VERSION ""

NS_ :

BS_:

BU_: Airbag Allrad EPS Teves_MK60_ESP LWS LWR Teves_MK70_MABS Waehlhebel EPB TRW_ESP ACC_Radar AFS Magne_Ride RKA_Plus Selespeed Waehlhebel_Sele PDC_PLA Lenkhilfe_APA VAQ Daempfer Hybrid_BMS Hybrid_PWR Hybrid_DQ200 EKlimakomp SWA HCA ACC_Lidar Lenkhilfe_ZF_3G FLA AG6 DQ Hybrid_MSG Diesel Otto Gateway_PQ35_A Gateway_PQ46_A Vector_XXX Fzg_CAN

BO_ 1472 mEPB_1: 8 EPB
 SG_ EP1_Spannkraft : 8|5@1+ (1,0) [0|30] "kN"  Gateway_PQ46_A,Diesel,Otto,ACC_Radar,Gateway_PQ35_A,Daempfer
 SG_ EP1_Sta_EPB : 6|1@1+ (1,0) [0|1] ""  Gateway_PQ46_A,Diesel,Otto,ACC_Radar,Gateway_PQ35_A,Daempfer,PDC_PLA
 SG_ EP1_Fehler_Sta : 4|2@1+ (1,0) [0|3] ""  Gateway_PQ46_A,Diesel,Otto,ACC_Radar,Gateway_PQ35_A,Daempfer,PDC_PLA
 SG_ EP1_Zaehler : 0|4@1+ (1,0) [0|15] ""  Gateway_PQ46_A,Diesel,Otto,ACC_Radar,Gateway_PQ35_A,Daempfer
 SG_ EP1_Schalterinfo : 13|2@1+ (1,0) [0|3] ""  Gateway_PQ46_A,Diesel,Otto,ACC_Radar,Gateway_PQ35_A,Daempfer
 SG_ EP1_Sta_Schalter : 7|1@1+ (1,0) [0|1] ""  Gateway_PQ46_A,Diesel,Otto,ACC_Radar,Gateway_PQ35_A,Daempfer
 SG_ EP1_Sta_NWS : 15|1@1+ (1,0) [0|1] ""  Gateway_PQ46_A,Diesel,Otto,ACC_Radar,Gateway_PQ35_A,Daempfer
 SG_ EP1_Fkt_Lampe : 48|1@1+ (1,0) [0|1] ""  Gateway_PQ46_A,Diesel,Otto,ACC_Radar,Gateway_PQ35_A,Daempfer
 SG_ EP1_Verzoegerung : 24|8@1+ (0.048,-7.968) [-7.968|4.224] "m/s²"  Gateway_PQ46_A,Diesel,Otto,ACC_Radar,Gateway_PQ35_A,Daempfer
 SG_ EP1_Neig_winkel : 16|8@1+ (1,-128) [-128|127] "%g"  Gateway_PQ46_A,Diesel,Otto,ACC_Radar,Gateway_PQ35_A,Daempfer
 SG_ EP1_Fehler_gelb : 51|1@1+ (1,0) [0|1] ""  Gateway_PQ46_A,Diesel,Otto,ACC_Radar,Gateway_PQ35_A,Daempfer
 SG_ EP1_Warnton : 49|1@1+ (1,0) [0|1] ""  Gateway_PQ46_A,Diesel,Otto,ACC_Radar,Gateway_PQ35_A,Daempfer
 SG_ EP1_Fehler_BKL : 50|1@1+ (1,0) [0|1] ""  Gateway_PQ46_A,Gateway_PQ35_A,Otto,Diesel,Daempfer,ACC_Radar
 SG_ EP1_Fehlereintr : 32|1@1+ (1,0) [0|1] ""  Gateway_PQ46_A,Diesel,Otto,ACC_Radar,Gateway_PQ35_A,Daempfer
 SG_ EP1__Text : 52|4@1+ (1,0) [0|15] ""  Gateway_PQ46_A,Diesel,Otto,ACC_Radar,Gateway_PQ35_A,Daempfer
 SG_ EP1_Freigabe_Ver : 33|1@1+ (1,0) [0|1] ""  Gateway_PQ46_A,Diesel,Otto,ACC_Radar,Gateway_PQ35_A,Daempfer
 SG_ EP1_Checksum : 56|8@1+ (1,0) [0|255] ""  Gateway_PQ46_A,Diesel,Otto,ACC_Radar,Gateway_PQ35_A,Daempfer
 SG_ EP1_Auto_Schl_Oe : 43|1@1+ (1,0) [0|1] ""  Gateway_PQ46_A,Gateway_PQ35_A
 SG_ EP1_SleepInd : 36|1@1+ (1,0) [0|1] ""  Gateway_PQ46_A,Diesel,Otto,ACC_Radar,Gateway_PQ35_A,Daempfer
 SG_ EP1_Bremslicht : 39|1@1+ (1,0) [0|1] ""  Gateway_PQ46_A,Diesel,Otto,ACC_Radar,Gateway_PQ35_A,Daempfer
 SG_ EP1_Status_Kl_15 : 37|1@1+ (1,0) [0|1] ""  Gateway_PQ46_A,Diesel,Otto,ACC_Radar,Gateway_PQ35_A,Daempfer
 SG_ EP1_Warnton2 : 41|1@1+ (1,0) [0|1] ""  Gateway_PQ46_A,Diesel,Otto,ACC_Radar,Gateway_PQ35_A,Daempfer
 SG_ EP1_Lampe_AutoP : 38|1@1+ (1,0) [0|1] ""  Gateway_PQ46_A,Diesel,Otto,ACC_Radar,Gateway_PQ35_A,Daempfer
 SG_ EP1_QualNeigWi : 44|1@1+ (1,0) [0|1] ""  Gateway_PQ46_A,Gateway_PQ35_A
 SG_ EP1_AnfShLock : 42|1@1+ (1,0) [0|1] ""  Gateway_PQ46_A,Diesel,Otto,ACC_Radar,Gateway_PQ35_A,Daempfer
 SG_ EP1_HydrHalten : 47|1@1+ (1,0) [0|1] ""  Gateway_PQ46_A,Diesel,Otto,ACC_Radar,Gateway_PQ35_A,Daempfer
 SG_ EP1_Warnton1 : 40|1@1+ (1,0) [0|1] ""  Gateway_PQ46_A,Diesel,Otto,ACC_Radar,Gateway_PQ35_A,Daempfer
 SG_ EP1_KuppModBer : 45|2@1+ (1,0) [0|3] ""  Gateway_PQ46_A,Diesel,Gateway_PQ35_A,Otto
 SG_ EP1_AutoHold_zul : 34|1@1+ (1,0) [0|1] ""  ACC_Radar,Daempfer,Gateway_PQ35_A,Diesel,Otto,Gateway_PQ46_A
 SG_ EP1_AutoHold_aktiv : 35|1@1+ (1,0) [0|1] ""  ACC_Radar,Daempfer,Gateway_PQ35_A,Diesel,Gateway_PQ46_A,Otto

BO_ 537 mTP_Er_EPB: 7 EPB
 SG_ EPB_TP_Er : 0|56@1+ (1,0) [0|7.2057594038E+016] ""  Gateway_PQ46_A,Gateway_PQ35_A

BO_ 1386 mACC_GRA_Anzeige: 8 ACC_Radar
 SG_ ACA_ID_StaACC : 11|5@1+ (1,0) [0|31] ""  Gateway_PQ46_A,Gateway_PQ35_A
 SG_ ACA_Fahrerhinw : 16|1@1+ (1,0) [0|1] ""  Gateway_PQ46_A,Gateway_PQ35_A
 SG_ ACA_V_Wunsch : 24|8@1+ (1,0) [0|254] "km/h"  Gateway_PQ46_A,Gateway_PQ35_A,DQ,AG6
 SG_ ACA_PrioDisp : 35|2@1+ (1,0) [0|3] ""  Gateway_PQ46_A,Gateway_PQ35_A
 SG_ ACA_StaACC : 8|3@1+ (1,0) [0|7] ""  Gateway_PQ46_A,Gateway_PQ35_A
 SG_ ACA_AnzDisplay : 17|1@1+ (1,0) [0|1] ""  Gateway_PQ46_A,Gateway_PQ35_A
 SG_ ACA_Zeitluecke : 18|4@1+ (1,0) [0|15] ""  Gateway_PQ46_A,Gateway_PQ35_A
 SG_ ACA_gemZeitl : 40|4@1+ (1,0) [0|15] ""  Gateway_PQ46_A,Gateway_PQ35_A
 SG_ ACA_kmh_mph : 32|1@1+ (1,0) [0|1] ""  Gateway_PQ46_A,Gateway_PQ35_A
 SG_ ACA_Akustik1 : 33|1@1+ (1,0) [0|1] ""  Gateway_PQ46_A,Gateway_PQ35_A
 SG_ ACA_Akustik2 : 34|1@1+ (1,0) [0|1] ""  Gateway_PQ46_A,Gateway_PQ35_A
 SG_ ACA_Checksum : 0|8@1+ (1,0) [0|255] ""  Gateway_PQ46_A,Gateway_PQ35_A
 SG_ ACA_Codierung : 56|1@1+ (1,0) [0|1] ""  Gateway_PQ46_A,Gateway_PQ35_A
 SG_ ACA_Tachokranz : 57|1@1+ (1,0) [0|1] ""  Gateway_PQ46_A,Gateway_PQ35_A
 SG_ ACA_ACC_Verz : 44|1@1+ (1,0) [0|1] ""  Gateway_PQ46_A,Gateway_PQ35_A
 SG_ ACA_res_22 : 22|2@1+ (1,0) [0|3] ""  Gateway_PQ46_A,Gateway_PQ35_A
 SG_ ACA_Zaehler : 60|4@1+ (1,0) [0|15] ""  Gateway_PQ46_A,Gateway_PQ35_A
 SG_ ACA_res_37 : 37|2@1+ (1,0) [0|3] ""  Gateway_PQ46_A,Gateway_PQ35_A
 SG_ ACA_res_45 : 45|3@1+ (1,0) [0|7] ""  Gateway_PQ46_A,Gateway_PQ35_A
 SG_ ACA_ID_StaGRA : 51|5@1+ (1,0) [0|31] ""  Gateway_PQ46_A,Gateway_PQ35_A
 SG_ ACA_res_59 : 59|1@1+ (1,0) [0|1] ""  Gateway_PQ46_A,Gateway_PQ35_A
 SG_ ACA_res_39 : 39|1@1+ (1,0) [0|1] ""  Gateway_PQ46_A,Gateway_PQ35_A
 SG_ ACA_Aend_Zeitluecke : 58|1@1+ (1,0) [0|1] ""  Gateway_PQ46_A,Gateway_PQ35_A
 SG_ ACA_StaGRA : 48|3@1+ (1,0) [0|7] ""  Gateway_PQ46_A,Gateway_PQ35_A

BO_ 523 mTP_Er_ADR: 7 ACC_Radar
 SG_ ADR_TP_Er : 0|56@1+ (1,0) [0|7.2057594038E+016] ""  Gateway_PQ46_A

BO_ 872 mACC_System: 8 ACC_Radar
 SG_ ACS_Schubabsch : 15|1@1+ (1,0) [0|1] ""  Diesel,Otto,AG6,DQ
 SG_ ACS_ADR_Schub : 14|1@1+ (1,0) [0|1] ""  Diesel,Otto,DQ,AG6
 SG_ ACS_Checksum : 0|8@1+ (1,0) [0|255] ""  Diesel,Otto,Daempfer
 SG_ ACS_Sta_ADR : 12|2@1+ (1,0) [0|3] ""  Diesel,Otto,AG6,DQ
 SG_ ACS_StSt_Info : 16|2@1+ (1,0) [0|3] ""  Diesel,Otto
 SG_ ACS_Zaehler : 8|4@1+ (1,0) [0|15] ""  Diesel,Otto,Daempfer
 SG_ ACS_MomEingriff : 18|1@1+ (1,0) [0|1] ""  Diesel,Otto,AG6,DQ
 SG_ ACS_FreigSollB : 23|1@1+ (1,0) [0|1] ""  Diesel,Otto,Daempfer,AG6,DQ
 SG_ ACS_Sollbeschl : 24|11@1+ (0.005,-7.22) [-7.22|3.005] "m/s²"  Diesel,Otto,Daempfer,DQ,AG6
 SG_ ACS_res_21 : 21|2@1+ (1,0) [0|3] ""  Otto,Diesel
 SG_ ACS_res_37 : 37|1@1+ (1,0) [0|1] ""  Otto,Diesel
 SG_ ACS_res_35 : 35|1@1+ (1,0) [0|1] ""  Otto,Diesel
 SG_ ACS_Typ_ACC : 19|2@1+ (1,0) [0|3] ""  Diesel,Otto,DQ,AG6
 SG_ ACS_Anhaltewunsch : 38|1@1+ (1,0) [0|1] ""  Diesel,Otto
 SG_ ACS_zul_Regelabw : 40|8@1+ (0.005,0) [0|1.265] "m/s²"  Diesel,Otto
 SG_ ACS_res_36 : 36|1@1+ (1,0) [0|1] ""  Otto,Diesel
 SG_ ACS_max_AendGrad : 48|8@1+ (0.02,0) [0.02|5.06] "m/s²"  Diesel,Otto
 SG_ ACS_res_56 : 56|1@1+ (1,0) [0|1] ""  Otto,Diesel
 SG_ ACS_res_57 : 57|1@1+ (1,0) [0|1] ""  Otto,Diesel
 SG_ ACS_Fehler : 39|1@1+ (1,0) [0|1] ""  Gateway_PQ46_A,Diesel,Otto,Gateway_PQ35_A
 SG_ ACS_res_58 : 58|1@1+ (1,0) [0|1] ""  Otto,Diesel
 SG_ ACS_res_59 : 59|1@1+ (1,0) [0|1] ""  Otto,Diesel
 SG_ ACS_res_63 : 63|1@1+ (1,0) [0|1] ""  Otto,Diesel
 SG_ ACS_res_60 : 60|1@1+ (1,0) [0|1] ""  Otto,Diesel
 SG_ ACS_res_62 : 62|1@1+ (1,0) [0|1] ""  Otto,Diesel
 SG_ ACS_res_61 : 61|1@1+ (1,0) [0|1] ""  Otto,Diesel

BO_ 870 mAWV: 5 ACC_Radar
 SG_ AWV_2_Status : 24|1@1+ (1,0) [0|1] ""  Gateway_PQ46_A,TRW_ESP,HCA,Gateway_PQ35_A
 SG_ AWV_2_SU_Warnzeit : 26|2@1+ (1,0) [0|3] ""  Gateway_PQ46_A,TRW_ESP,HCA,Gateway_PQ35_A
 SG_ AWV_Checksumme : 0|8@1+ (1,0) [0|255] ""  Gateway_PQ46_A,TRW_ESP,HCA,Gateway_PQ35_A
 SG_ AWV_Zaehler : 8|4@1+ (1,0) [0|15] ""  Gateway_PQ46_A,TRW_ESP,HCA,Gateway_PQ35_A
 SG_ AWV_2_Fehler : 25|1@1+ (1,0) [0|1] ""  Gateway_PQ46_A,TRW_ESP,HCA,Gateway_PQ35_A
 SG_ AWV_1_Prefill : 17|1@1+ (1,0) [0|1] ""  Gateway_PQ46_A,TRW_ESP,HCA,Gateway_PQ35_A
 SG_ AWV_Text : 12|4@1+ (1,0) [0|15] ""  Gateway_PQ46_A,TRW_ESP,HCA,Gateway_PQ35_A
 SG_ AWV_res_20 : 20|4@1+ (1,0) [0|15] ""  Gateway_PQ46_A,Gateway_PQ35_A,HCA,TRW_ESP
 SG_ AWV_1_Freigabe : 16|1@1+ (1,0) [0|1] ""  Gateway_PQ46_A,TRW_ESP,HCA,Gateway_PQ35_A
 SG_ AWV_2_SU_Bremsruck : 28|1@1+ (1,0) [0|1] ""  Gateway_PQ46_A,TRW_ESP,HCA,Gateway_PQ35_A
 SG_ AWV_1_Parameter : 18|2@1+ (1,0) [0|3] ""  Gateway_PQ46_A,TRW_ESP,HCA,Gateway_PQ35_A
 SG_ AWV_2_Umfeldwarn : 31|1@1+ (1,0) [0|1] ""  Gateway_PQ46_A,TRW_ESP,HCA,Gateway_PQ35_A
 SG_ AWV_2_Freigabe : 32|1@1+ (1,0) [0|1] ""  Gateway_PQ46_A,TRW_ESP,HCA,Gateway_PQ35_A
 SG_ AWV_2_Gurtstraffer : 39|1@1+ (1,0) [0|1] ""  Gateway_PQ46_A,TRW_ESP,HCA,Gateway_PQ35_A
 SG_ AWV_2_SU_Gong : 29|1@1+ (1,0) [0|1] ""  Gateway_PQ46_A,TRW_ESP,HCA,Gateway_PQ35_A
 SG_ AWV_Infoton : 38|1@1+ (1,0) [0|1] ""  Gateway_PQ46_A,TRW_ESP,HCA,Gateway_PQ35_A
 SG_ AWV_2_Warnsymbol : 37|1@1+ (1,0) [0|1] ""  Gateway_PQ46_A,TRW_ESP,HCA,Gateway_PQ35_A
 SG_ AWV_2_Warnton : 36|1@1+ (1,0) [0|1] ""  Gateway_PQ46_A,TRW_ESP,HCA,Gateway_PQ35_A
 SG_ AWV_2_Ruckprofil : 33|3@1+ (1,0) [0|7] ""  Gateway_PQ46_A,TRW_ESP,HCA,Gateway_PQ35_A
 SG_ AWV_2_SU_Lampe : 30|1@1+ (1,0) [0|1] ""  Gateway_PQ46_A,TRW_ESP,HCA,Gateway_PQ35_A

BO_ 1652 BAP_ACC: 8 ACC_Radar
 SG_ BAP_Data_ACC : 0|16@1+ (1,0) [0|65535] ""  Gateway_PQ46_A,Gateway_PQ35_A
 SG_ BAP_var_ACC : 16|48@1+ (1,0) [0|2.8147497671E+014] ""  Gateway_PQ46_A,Gateway_PQ35_A

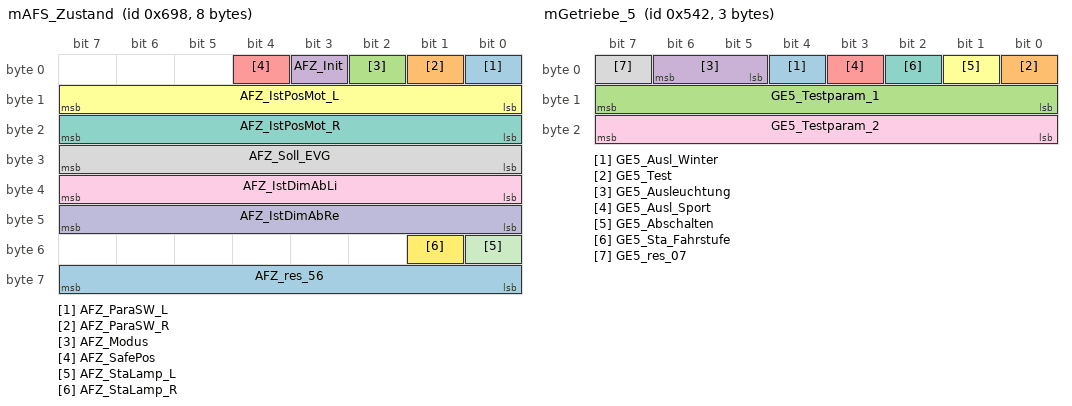
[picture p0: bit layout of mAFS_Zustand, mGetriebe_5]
BO_ 1688 mAFS_Zustand: 8 AFS
 SG_ AFZ_ParaSW_L : 0|1@1+ (1,0) [0|1] "" Vector__XXX
 SG_ AFZ_ParaSW_R : 1|1@1+ (1,0) [0|1] "" Vector__XXX
 SG_ AFZ_Modus : 2|1@1+ (1,0) [0|1] "" Vector__XXX
 SG_ AFZ_Init : 3|1@1+ (1,0) [0|1] "" Vector__XXX
 SG_ AFZ_SafePos : 4|1@1+ (1,0) [0|1] "" Vector__XXX
 SG_ AFZ_IstPosMot_L : 8|8@1+ (0.4,0) [0|100] "%" Vector__XXX
 SG_ AFZ_IstPosMot_R : 16|8@1+ (0.4,0) [0|100] "%" Vector__XXX
 SG_ AFZ_Soll_EVG : 24|8@1+ (0.4,0) [0|100] "%" Vector__XXX
 SG_ AFZ_IstDimAbLi : 32|8@1+ (0.4,0) [0|100] "%" Vector__XXX
 SG_ AFZ_IstDimAbRe : 40|8@1+ (0.4,0) [0|100] "%" Vector__XXX
 SG_ AFZ_StaLamp_L : 48|1@1+ (1,0) [0|1] "" Vector__XXX
 SG_ AFZ_StaLamp_R : 49|1@1+ (1,0) [0|1] "" Vector__XXX
 SG_ AFZ_res_56 : 56|8@1+ (1,0) [0|255] "" Vector__XXX

BO_ 1428 mNiveau_2: 8 Magne_Ride
 SG_ NI2_Hoehe_HR m0 : 40|8@1+ (1,-127) [-127|126] "mm"  LWR,AFS
 SG_ NI2_Hoehe_VL m0 : 16|8@1+ (1,-127) [-127|126] "mm"  LWR,AFS
 SG_ NI2_Hoehe_HL m0 : 32|8@1+ (1,-127) [-127|126] "mm"  LWR,AFS
 SG_ NI2_Checksum : 0|8@1+ (1,0) [0|255] ""  LWR,AFS
 SG_ NI2_Hoehe_VR m0 : 24|8@1+ (1,-127) [-127|126] "mm"  LWR,AFS
 SG_ NI2_AufbBeschl_VL : 48|8@1+ (0.08,-10.08) [-10.08|10.08] "m/s²"  AFS,LWR
 SG_ NI2_Zaehler : 8|4@1+ (1,0) [0|15] ""  LWR,AFS
 SG_ NI2_Reserve1 : 13|3@1+ (1,0) [0|7] ""  AFS,LWR
 SG_ NI2_AufbBeschl_VR : 56|8@1+ (0.08,-10.08) [-10.08|10.08] "m/s²"  AFS,LWR
 SG_ NI2_Hoehe_VL_Roh m1 : 16|8@1+ (0.4,0) [0|100] "%"  AFS
 SG_ NI2_Hoehe_HR_Roh m1 : 40|8@1+ (0.4,0) [0|100] "%"  AFS
 SG_ NI2_Hoehe_HL_Roh m1 : 32|8@1+ (0.4,0) [0|100] "%"  AFS
 SG_ NI2_Hoehenflag M : 12|1@1+ (1,0) [0|1] ""  AFS
 SG_ NI2_Hoehe_VR_Roh m1 : 24|8@1+ (0.4,0) [0|100] "%"  AFS

BO_ 524 mTP_Er_Daempfer: 7 Magne_Ride
 SG_ Daempfer_TP_Er : 0|56@1+ (1,0) [0|7.2057594038E+016] ""  Gateway_PQ46_A,Gateway_PQ35_A

BO_ 1432 mDaempfer_1: 8 Magne_Ride
 SG_ DA1_Warnlampe : 3|1@1+ (1,0) [0|1] ""  Gateway_PQ46_A,Teves_MK60_ESP,Gateway_PQ35_A
 SG_ DA1_Systemstatus : 6|1@1+ (1,0) [0|1] ""  Gateway_PQ46_A,Teves_MK60_ESP,Gateway_PQ35_A
 SG_ DA1_Taster : 4|1@1+ (1,0) [0|1] ""  Gateway_PQ46_A,Teves_MK60_ESP,Gateway_PQ35_A
 SG_ DA1_Textbits : 8|4@1+ (1,0) [0|15] ""  Gateway_PQ46_A,Teves_MK60_ESP,Gateway_PQ35_A
 SG_ DA1_Zaehler : 12|4@1+ (1,0) [0|15] ""  Gateway_PQ46_A,Teves_MK60_ESP,Gateway_PQ35_A
 SG_ DA1_res_06 : 5|1@1+ (1,0) [0|1] ""  Gateway_PQ46_A,Gateway_PQ35_A,Teves_MK60_ESP
 SG_ DA1_Daempferreg : 0|3@1+ (1,0) [0|7] ""  Gateway_PQ46_A,Teves_MK60_ESP,Gateway_PQ35_A
 SG_ DA1_Checksumme : 56|8@1+ (1,0) [0|15] ""  Gateway_PQ46_A,Teves_MK60_ESP,Gateway_PQ35_A
 SG_ DA1_Fehlereintr : 7|1@1+ (1,0) [0|1] ""  Gateway_PQ46_A,Teves_MK60_ESP,Gateway_PQ35_A
 SG_ DA1_res_32 : 32|8@1+ (1,0) [0|255] ""  Gateway_PQ46_A,Gateway_PQ35_A,Teves_MK60_ESP
 SG_ DA1_ESP_Zwang : 16|1@1+ (1,0) [0|1] ""  Gateway_PQ46_A,Teves_MK60_ESP,Gateway_PQ35_A
 SG_ DA1_res_24 : 24|8@1+ (1,0) [0|255] ""  Gateway_PQ46_A,Gateway_PQ35_A,Teves_MK60_ESP
 SG_ DA1_res_18 : 19|5@1+ (1,0) [0|31] ""  Gateway_PQ46_A,Gateway_PQ35_A,Teves_MK60_ESP
 SG_ DA1_res_40 : 40|8@1+ (1,0) [0|255] ""  Gateway_PQ46_A,Gateway_PQ35_A,Teves_MK60_ESP
 SG_ DA1_res_48 : 48|8@1+ (1,0) [0|255] ""  Gateway_PQ46_A,Gateway_PQ35_A,Teves_MK60_ESP
 SG_ DA1_LampPruef : 17|1@1+ (1,0) [0|1] ""  Gateway_PQ46_A,Teves_MK60_ESP,Gateway_PQ35_A
 SG_ DA1_Charisma : 18|1@1+ (1,0) [0|1] ""  Gateway_PQ46_A,Gateway_PQ35_A

BO_ 520 mTP_Er_RKA_Plus: 7 RKA_Plus
 SG_ RKA_Plus_TP_Er : 0|56@1+ (1,0) [0|7.2057594038E+016] ""  Gateway_PQ35_A

BO_ 1091 mRDK_1_D3: 6 RKA_Plus
 SG_ RDK_Prio1_Warnung : 0|1@1+ (1,0) [0|1] ""  Gateway_PQ35_A,Gateway_PQ46_A
 SG_ RDK_FMVSS_138_Warnung : 6|1@1+ (1,0) [0|1] ""  Gateway_PQ35_A,Gateway_PQ46_A
 SG_ RDK_neue_Solldruecke : 10|1@1+ (1,0) [0|1] ""  Gateway_PQ46_A,Gateway_PQ35_A
 SG_ RDK_Ack_IstZu_Solldruecke : 9|1@1+ (1,0) [0|1] ""  Gateway_PQ46_A,Gateway_PQ35_A
 SG_ RDK_res11 : 11|1@1+ (1,0) [0|1] ""  Gateway_PQ46_A,Gateway_PQ35_A
 SG_ RDK_KD_Fehler : 15|1@1+ (1,0) [0|1] ""  Gateway_PQ35_A,Gateway_PQ46_A
 SG_ RDK_res12 : 12|1@1+ (1,0) [0|1] ""  Gateway_PQ46_A,Gateway_PQ35_A
 SG_ RDK_res13 : 13|1@1+ (1,0) [0|1] ""  Gateway_PQ46_A,Gateway_PQ35_A
 SG_ RDK_res23 : 23|1@1+ (1,0) [0|1] ""  Gateway_PQ46_A,Gateway_PQ35_A
 SG_ RDK_res38 : 38|1@1+ (1,0) [0|1] ""  Gateway_PQ46_A,Gateway_PQ35_A
 SG_ RDK_res22 : 22|1@1+ (1,0) [0|1] ""  Gateway_PQ46_A,Gateway_PQ35_A
 SG_ RDK_res14 : 14|1@1+ (1,0) [0|1] ""  Gateway_PQ46_A,Gateway_PQ35_A
 SG_ RDK_res47 : 47|1@1+ (1,0) [0|1] ""  Gateway_PQ46_A,Gateway_PQ35_A
 SG_ RDK_Prio2_Warnung : 1|1@1+ (1,0) [0|1] ""  Gateway_PQ35_A,Gateway_PQ46_A
 SG_ RDK_res39 : 39|1@1+ (1,0) [0|1] ""  Gateway_PQ46_A,Gateway_PQ35_A
 SG_ RDK_Status : 8|1@1+ (1,0) [0|1] ""  Gateway_PQ46_A,Gateway_PQ35_A
 SG_ RDK_Warnungen : 2|4@1+ (1,0) [0|15] ""  Gateway_PQ35_A,Gateway_PQ46_A
 SG_ RDK_xx_Color : 20|2@1+ (1,0) [0|2] ""  Gateway_PQ46_A,Gateway_PQ35_A
 SG_ RDK_xx_Ist_Temp : 24|8@1+ (1,-60) [-60|194] "°C"  Gateway_PQ46_A,Gateway_PQ35_A
 SG_ RDK_res46 : 46|1@1+ (1,0) [0|1] ""  Gateway_PQ46_A,Gateway_PQ35_A
 SG_ RDK_xx_Soll_Druck : 40|6@1+ (0.1,0) [0|6.3] "bar"  Gateway_PQ46_A,Gateway_PQ35_A
 SG_ RDK_xx_Status_Sensor : 19|1@1+ (1,0) [0|1] ""  Gateway_PQ46_A,Gateway_PQ35_A
 SG_ RDK_Sensor_Multiplex : 16|3@1+ (1,0) [0|4] ""  Gateway_PQ46_A,Gateway_PQ35_A
 SG_ RDK_xx_Ist_Druck : 32|6@1+ (0.1,0) [0|6.3] "bar"  Gateway_PQ46_A,Gateway_PQ35_A
 SG_ RDK_FMVSS_138_MIL : 7|1@1+ (1,0) [0|1] ""  Gateway_PQ35_A,Gateway_PQ46_A

BO_ 514 mTP_Er_Getriebe: 7 Selespeed
 SG_ Getriebe_TP_Er : 0|56@1+ (1,0) [0|7.2057594038E+016] ""  Gateway_PQ46_A,Gateway_PQ35_A

BO_ 1344 mGetriebe_2: 8 Selespeed
 SG_ GE2_Sta_ZwGas : 3|1@1+ (1,0) [0|1] ""  Gateway_PQ46_A,Diesel,Otto,Gateway_PQ35_A,Hybrid_MSG
 SG_ GE2_Sta_SAS : 1|1@1+ (1,0) [0|1] ""  Gateway_PQ46_A,Otto,Gateway_PQ35_A
 SG_ GE2_SlipStDZEingr : 2|1@1+ (1,0) [0|1] ""  Gateway_PQ46_A,Gateway_PQ35_A,Hybrid_MSG
 SG_ GE2_LFR_Adap : 0|1@1+ (1,0) [0|1] ""  Gateway_PQ46_A,Diesel,Otto,Gateway_PQ35_A,Hybrid_MSG
 SG_ GE2_Zaehler : 4|4@1+ (1,0) [0|15] ""  Gateway_PQ46_A,Diesel,Otto,Gateway_PQ35_A,Hybrid_MSG
 SG_ GE2_Grad_begr : 16|8@1+ (10,0) [0|2540] "Nm/s"  Gateway_PQ46_A,Diesel,Otto,Gateway_PQ35_A,Hybrid_MSG
 SG_ GE2_LL_Solldz : 8|8@1+ (10,0) [0|2540] "1/min"  Gateway_PQ46_A,Diesel,Otto,Gateway_PQ35_A,Hybrid_MSG
 SG_ GE2_Sync_Zeit : 40|8@1+ (20,0) [0|5080] "ms"  Gateway_PQ46_A,Diesel,Otto,Gateway_PQ35_A,Hybrid_MSG
 SG_ GE2_DZM_Daempf : 48|1@1+ (1,0) [0|1] ""  Gateway_PQ46_A,Gateway_PQ35_A
 SG_ GE2_Fehlertext_Freigabe : 51|1@1+ (1,0) [0|1] ""  Gateway_PQ46_A,Gateway_PQ35_A
 SG_ GE2_Gong : 50|1@1+ (1,0) [0|1] ""  Gateway_PQ46_A,Gateway_PQ35_A
 SG_ GE2_Senderkennung : 53|1@1+ (1,0) [0|1] ""  Gateway_PQ46_A,Gateway_PQ35_A
 SG_ GE2_Shift_Lock : 52|1@1+ (1,0) [0|1] ""  Gateway_PQ46_A,Gateway_PQ35_A
 SG_ GE2_Variante M : 56|4@1+ (1,0) [0|15] ""  Gateway_PQ46_A,Gateway_PQ35_A,Waehlhebel_Sele
 SG_ GE2_Sync_Dz : 24|8@1+ (25,0) [0|6375] "1/min"  Gateway_PQ46_A,Diesel,Otto,Gateway_PQ35_A,Hybrid_MSG
 SG_ GE2_invMSB_Sync : 49|1@1+ (1,0) [0|1] ""  Gateway_PQ46_A,Gateway_PQ35_A,Diesel,Otto
 SG_ GE2_WBA_Blinken : 55|1@1+ (1,0) [0|1] ""  Gateway_PQ46_A,Diesel,Otto,Gateway_PQ35_A,Hybrid_MSG
 SG_ GE2_MSB_Sync : 54|1@1+ (1,0) [0|1] ""  Gateway_PQ46_A,Gateway_PQ35_A,Otto,Diesel
 SG_ GE2_5Gang m0 : 60|4@1+ (1,0) [0|8] ""  Gateway_PQ46_A,Gateway_PQ35_A
 SG_ GE2_invSync_Dz : 32|8@1+ (-25,6375) [0|6375] "1/min"  Gateway_PQ46_A,Diesel,Otto,Gateway_PQ35_A,Hybrid_MSG
 SG_ GE2_PRND m1 : 60|4@1+ (1,0) [0|5] ""  Gateway_PQ46_A,Gateway_PQ35_A
 SG_ GE2_4Gang m2 : 60|4@1+ (1,0) [0|8] ""  Gateway_PQ46_A,Gateway_PQ35_A
 SG_ GE2_Tip4Gang m8 : 60|4@1+ (1,0) [0|5] ""  Gateway_PQ46_A,Gateway_PQ35_A
 SG_ GE2_akt_Gang m15 : 60|4@1+ (1,0) [0|13] ""  Gateway_PQ46_A,Gateway_PQ35_A,Waehlhebel_Sele
 SG_ GE2_Tip6Gang m12 : 60|4@1+ (1,0) [0|7] ""  Gateway_PQ46_A,Gateway_PQ35_A
 SG_ GE2_ASG m3 : 60|4@1+ (1,0) [0|12] ""  Gateway_PQ46_A,Gateway_PQ35_A
 SG_ GE2_PRNDS m6 : 60|4@1+ (1,0) [0|6] ""  Gateway_PQ46_A,Gateway_PQ35_A
 SG_ GE2_Tip7Gang m13 : 60|4@1+ (1,0) [0|8] ""  Gateway_PQ46_A,Gateway_PQ35_A
 SG_ GE2_Selespeed m4 : 60|4@1+ (1,0) [0|10] ""  Gateway_PQ46_A,Gateway_PQ35_A,Waehlhebel_Sele
 SG_ GE2_Tip5Gang m9 : 60|4@1+ (1,0) [0|6] ""  Gateway_PQ46_A,Gateway_PQ35_A

BO_ 1346 mGetriebe_5: 3 Selespeed
 SG_ GE5_Ausl_Winter : 4|1@1+ (1,0) [0|1] ""  Waehlhebel_Sele
 SG_ GE5_Test : 0|1@1+ (1,0) [0|1] ""  Waehlhebel_Sele
 SG_ GE5_Testparam_1 : 8|8@1+ (1,0) [0|255] ""  Waehlhebel_Sele
 SG_ GE5_Ausleuchtung : 5|2@1+ (1,0) [0|3] ""  Waehlhebel_Sele
 SG_ GE5_Ausl_Sport : 3|1@1+ (1,0) [0|1] ""  Waehlhebel_Sele
 SG_ GE5_Abschalten : 1|1@1+ (1,0) [0|1] ""  Waehlhebel_Sele
 SG_ GE5_Sta_Fahrstufe : 2|1@1+ (1,0) [0|1] ""  Waehlhebel_Sele
 SG_ GE5_res_07 : 7|1@1+ (1,0) [0|1] "" Vector__XXX
 SG_ GE5_Testparam_2 : 16|8@1+ (1,0) [0|255] ""  Waehlhebel_Sele

BO_ 1348 mGetriebe_7: 4 Selespeed
 SG_ GE7_Text_01 : 0|1@1+ (1,0) [0|1] ""  Gateway_PQ35_A
 SG_ GE7_Text_04 : 4|1@1+ (1,0) [0|1] ""  Gateway_PQ35_A
 SG_ GE7_Text_05 : 5|1@1+ (1,0) [0|1] ""  Gateway_PQ35_A
 SG_ GE7_Text_03 : 2|1@1+ (1,0) [0|1] ""  Gateway_PQ35_A
 SG_ GE7_Gong : 3|1@1+ (1,0) [0|1] ""  Gateway_PQ35_A
 SG_ GE7_Text_02 : 1|1@1+ (1,0) [0|1] ""  Gateway_PQ35_A
 SG_ GE7_res_11 : 11|1@1+ (1,0) [0|1] ""  Gateway_PQ35_A
 SG_ GE7_res_12 : 12|1@1+ (1,0) [0|1] ""  Gateway_PQ35_A
 SG_ GE7_res_15 : 15|1@1+ (1,0) [0|1] ""  Gateway_PQ35_A
 SG_ GE7_res_13 : 13|1@1+ (1,0) [0|1] ""  Gateway_PQ35_A
 SG_ GE7_res_17 : 17|1@1+ (1,0) [0|1] ""  Gateway_PQ35_A
 SG_ GE7_res_18 : 18|1@1+ (1,0) [0|1] ""  Gateway_PQ35_A
 SG_ GE7_res_16 : 16|1@1+ (1,0) [0|1] ""  Gateway_PQ35_A
 SG_ GE7_res_19 : 19|1@1+ (1,0) [0|1] ""  Gateway_PQ35_A
 SG_ GE7_res_20 : 20|1@1+ (1,0) [0|1] ""  Gateway_PQ35_A
 SG_ GE7_res_14 : 14|1@1+ (1,0) [0|1] ""  Gateway_PQ35_A
 SG_ GE7_res_21 : 21|1@1+ (1,0) [0|1] ""  Gateway_PQ35_A
 SG_ GE7_res_22 : 22|1@1+ (1,0) [0|1] ""  Gateway_PQ35_A
 SG_ GE7_res_23 : 23|1@1+ (1,0) [0|1] ""  Gateway_PQ35_A
 SG_ GE7_res_25 : 25|1@1+ (1,0) [0|1] ""  Gateway_PQ35_A
 SG_ GE7_res_27 : 27|1@1+ (1,0) [0|1] ""  Gateway_PQ35_A
 SG_ GE7_res_24 : 24|1@1+ (1,0) [0|1] ""  Gateway_PQ35_A
 SG_ GE7_res_26 : 26|1@1+ (1,0) [0|1] ""  Gateway_PQ35_A
 SG_ GE7_res_29 : 29|1@1+ (1,0) [0|1] ""  Gateway_PQ35_A
 SG_ GE7_res_30 : 30|1@1+ (1,0) [0|1] ""  Gateway_PQ35_A
 SG_ GE7_res_28 : 28|1@1+ (1,0) [0|1] ""  Gateway_PQ35_A
 SG_ GE7_res_31 : 31|1@1+ (1,0) [0|1] ""  Gateway_PQ35_A
 SG_ GE7_Text_07 : 7|1@1+ (1,0) [0|1] ""  Gateway_PQ35_A
 SG_ GE7_Feh_2Warn : 9|1@1+ (1,0) [0|1] ""  Gateway_PQ35_A
 SG_ GE7_Waehlh_ausgef : 6|1@1+ (1,0) [0|1] ""  Gateway_PQ35_A
 SG_ GE7_Feh_1Warn : 8|1@1+ (1,0) [0|1] ""  Gateway_PQ35_A
 SG_ GE7_SyncWarn : 10|1@1+ (1,0) [0|1] ""  Gateway_PQ35_A

BO_ 1088 mGetriebe_1: 8 Selespeed
 SG_ GE1_Klimakompr : 2|1@1+ (1,0) [0|1] ""  Diesel,Otto,TRW_ESP,Hybrid_MSG
 SG_ GE1_Sta_Schutz : 1|1@1+ (1,0) [0|1] ""  Otto,TRW_ESP,Diesel
 SG_ GE1_Zielgang : 8|4@1+ (1,0) [0|15] ""  Diesel,Otto,Teves_MK60_ESP,Teves_MK70_MABS,TRW_ESP,RKA_Plus,Hybrid_MSG
 SG_ GE1_EGS_Anf : 7|1@1+ (1,0) [0|1] ""  Diesel,Otto,TRW_ESP,Hybrid_MSG
 SG_ GE1_Soll_Mo : 24|8@1+ (0.39,0) [0|99.06] "%MDI"  Diesel,Otto,TRW_ESP
 SG_ GE1_WK : 3|2@1+ (1,0) [0|3] ""  Diesel,Otto,TRW_ESP,RKA_Plus,Hybrid_MSG,Allrad
 SG_ GE1_Schaltung : 0|1@1+ (1,0) [0|1] ""  Gateway_PQ46_A,Diesel,Otto,Teves_MK60_ESP,Teves_MK70_MABS,TRW_ESP,Gateway_PQ35_A,RKA_Plus,Hybrid_MSG
 SG_ GE1_Mrad_Mkurb : 16|8@1+ (0.1,0) [0|25.4] ""  Diesel,Otto,Teves_MK60_ESP,Teves_MK70_MABS,TRW_ESP,Hybrid_MSG
 SG_ GE1_Zaehler : 51|4@1+ (1,0) [0|15] ""  Diesel,Otto,EPB,TRW_ESP,ACC_Radar,Hybrid_MSG,ACC_Lidar,Teves_MK60_ESP
 SG_ GE1_Infobit : 49|1@1+ (1,0) [0|1] ""  TRW_ESP
 SG_ GE1_Fahrwistd : 32|8@1+ (0.249,-31.623) [-31.623|31.623] ""  Diesel,Otto,TRW_ESP,Hybrid_MSG
 SG_ GE1_Wahl_Pos : 12|4@1+ (1,0) [0|15] ""  Gateway_PQ46_A,Diesel,Otto,Teves_MK60_ESP,EPB,TRW_ESP,ACC_Radar,Gateway_PQ35_A,RKA_Plus,PDC_PLA,Hybrid_MSG,ACC_Lidar,Teves_MK70_MABS
 SG_ GE1_LaunchControl : 48|1@1+ (1,0) [0|1] ""  Otto,Teves_MK60_ESP,Teves_MK70_MABS,TRW_ESP,Hybrid_MSG,Diesel
 SG_ GE1_Fehlereintr : 55|1@1+ (1,0) [0|1] ""  Gateway_PQ46_A,TRW_ESP,Gateway_PQ35_A
 SG_ GE1_v_Umkehr : 46|1@1+ (1,0) [0|1] ""  TRW_ESP
 SG_ GE1_SleepInd : 50|1@1+ (1,0) [0|1] ""  Gateway_PQ46_A,TRW_ESP,Gateway_PQ35_A
 SG_ GE1_Notlauf : 40|4@1+ (1,0) [0|15] ""  Diesel,Otto,EPB,TRW_ESP,Hybrid_MSG
 SG_ GE1_WaVerl_Mo : 56|8@1+ (0.39,0) [0|99.06] "%MDI"  Diesel,Otto,TRW_ESP,Hybrid_MSG
 SG_ GE1_Kuehlung : 44|2@1+ (1,0) [0|3] ""  Diesel,Otto,TRW_ESP,Hybrid_MSG
 SG_ GE1_Sta_OBD : 47|1@1+ (1,0) [0|1] ""  Diesel,Otto,TRW_ESP,Hybrid_MSG
 SG_ GE1_StSt_Info : 5|2@1+ (1,0) [0|3] ""  TRW_ESP,Diesel,Otto

BO_TX_BU_ 1472 : TRW_ESP,EPB;
BO_TX_BU_ 537 : TRW_ESP,EPB;
BO_TX_BU_ 1386 : Otto,Diesel,ACC_Lidar,ACC_Radar;
BO_TX_BU_ 872 : ACC_Lidar,ACC_Radar;
BO_TX_BU_ 1652 : ACC_Lidar,ACC_Radar;
BO_TX_BU_ 1428 : Daempfer,Magne_Ride;
BO_TX_BU_ 524 : Daempfer,Magne_Ride;
BO_TX_BU_ 1432 : Daempfer,Magne_Ride;
BO_TX_BU_ 514 : DQ,AG6,Hybrid_DQ200,Selespeed;
BO_TX_BU_ 1344 : Otto,Diesel,DQ,AG6,Hybrid_DQ200,Selespeed;
BO_TX_BU_ 1088 : DQ,AG6,Hybrid_DQ200,Selespeed;
CM_ SG_ 1472 EP1_Spannkraft "Erreichte Spannkraft
Erzeugte Spannkraft. Bezieht sich auf die Aktuatoren";
CM_ SG_ 1472 EP1_Sta_EPB "Status Parkbremse
Gibt den Zustand der EPB-Aktuatoren an. Verknüpfung mit Fehlerstatus; wenn z.B. 'Linke Seite Fehlerhaft' und 'Bremse geschlossen', dann ist nur die rechte Seite geschlossen. Das Bit gesetzt, wenn auf einer Seite Spannkraft aufgebaut wird. Wenn auf beiden Seiten keine Spannkraft mehr vorhanden ist, wird Bit wieder zurückgesetzt.";
CM_ SG_ 1472 EP1_Fehler_Sta "Fehlerstatus Parkbremse
 ";
CM_ SG_ 1472 EP1_Zaehler "Zaehler Parkbremse
Freilaufender Botschaftszähler";
CM_ SG_ 1472 EP1_Schalterinfo "Schalterinfo Parkbremse
Spiegelt die Schalterstellung wider";
CM_ SG_ 1472 EP1_Sta_Schalter "Schalterstatus Parkbremse
Auch bei vollen Funktion kann kurzfristig ein Schalterfehler vorliegen";
CM_ SG_ 1472 EP1_Sta_NWS "Status Neigungswinkelgeber
Funktion des Neigungswinkelsensors1: Dauerhafter Ausfall oder Fehler Neigungswinkelgeber";
CM_ SG_ 1472 EP1_Fkt_Lampe "Funktionslampe (EPB 1)
Bit wird nur gesetzt, wenn volle Spannkraft auf beiden Seiten erreichtPQ46: Bit wird gesetzt, wenn BKL direkt vom EPB-SG als Funktionslampe angesteuert wird";
CM_ SG_ 1472 EP1_Verzoegerung "Verzoegerungsanforderung (EPB)
Steuerungsanforderung an andere Systeme (z.B. ESP), um während der Fahrt, durch den Handbrems-schalter ausgelöst, zu Bremsen (ECD-Funktion).";
CM_ SG_ 1472 EP1_Neig_winkel "Neigungswinkel
Neigungswinkelsignal";
CM_ SG_ 1472 EP1_Fehler_gelb "Fehlerlampe (gelb)
Fehlerlampe für nicht 'liegenbleiberelevante' Fehler";
CM_ SG_ 1472 EP1_Warnton "Warnton (EPB 1)
Bit wird gesetzt, wenn bei v > 0 eine Fahreranforderung schließen vorhanden ist (ECD angefordert)PQ46-Kombi sendet Warnton (600 Hz) solange dieses Bit gesetzt ist";
CM_ SG_ 1472 EP1_Fehler_BKL "Fehlerlampe (BKL)
Die BKL dient als rote Fehlerlampe für die EPB. Sie wird vom EPB-SG aktiv ausgeschaltet.(nicht PQ46)";
CM_ SG_ 1472 EP1_Fehlereintr "Fehlerspeichereintrag (EPB 1)
Bei gesetztem Bit ist mindestens ein Kundendienstfehler eingetragen";
CM_ SG_ 1472 EP1__Text "Textmeldungen (EPB 1)
0000 keine Textanzeige im Kombi 0001 Neigungswinkel zu groß (nicht PQ46)0010 Parkbremse von Hand öffnen0011 EPB in Diagnose (nicht PQ46)0100 Bremspedal betätigen (wird solange angezeigt, wie Fahrer das Bedienteil drückt und Bremspedal nicht betätigt)0101 Parkbremse bei laufendem Motor schließen (nicht PQ46)1000 Fehler Parkbremse Bedienungsanleitung beachten (nur PQ46)Anmerkung: Es kann immer nur ein Text gleichzeitig ausgegeben werden";
CM_ SG_ 1472 EP1_Freigabe_Ver "Freigabe Verzögerungs-Anforderung
 ";
CM_ SG_ 1472 EP1_Checksum "Checksumme Parkbremse
Prüfsumme, Definition im CAN Lastenheft ";
CM_ SG_ 1472 EP1_Auto_Schl_Oe "Automatisches Schließen, Öffnen erlaubt
'Automatisches schließen/öffnen' der EPB: z. Zt. nur bei Audi für CVT-Getriebe Projekte";
CM_ SG_ 1472 EP1_SleepInd "Sleep Indication
 ";
CM_ SG_ 1472 EP1_Bremslicht "Bremslicht
Bremslichtansteuerung bei dynamischer Abbremsung (nur im PQ46)";
CM_ SG_ 1472 EP1_Status_Kl_15 "Statusbit Klemme 15
Klemme 15 am EPB-Steuergerät";
CM_ SG_ 1472 EP1_Warnton2 "Warnton 2
PQ46-Kombi löst dreimal Warnton; wird zusammen mit roter Fehlerlampe (Byte 7, Bit 2) gesetzt";
CM_ SG_ 1472 EP1_Lampe_AutoP "Funktionslampe Auto Hold
Fahrerwunsch 'Auto Hold': im Stillstand wird die Parkstellung eingenommen (nur im PQ46)";
CM_ SG_ 1472 EP1_QualNeigWi "Qualifizierungsbit Neigungswinkel
Mitteilung z. Zt. für ACC um unter bestimmten Zuständen mitzuteilen, dass Neigungswinkel temporär ungültig ist.Beispiel: Selbsttest NeigungswinkelsensorErstmalig Audi C6";
CM_ SG_ 1472 EP1_AnfShLock "Anforderung Shift-Lock-Lampe
EPB kann manuell nur bei betätigter Fußbremse geöffnet werden. Wenn Bit gesetzt ist zeigt PQ46-Kombi die Shift-Lock-Lampe an";
CM_ SG_ 1472 EP1_HydrHalten "Hydraulisches Halten aktiv (Auto-Hold)
Bit wird gesetzt, wenn das Fahrzeug im Auto-Hold-Modus hydraulisch gehalten wird";
CM_ SG_ 1472 EP1_Warnton1 "Warnton 1
PQ46-Kombi löst einmal Warnton aus; wird nur zusammen mit gelber Fehlerlampe (Byte 7, Bit 3) gesetzt";
CM_ SG_ 1472 EP1_KuppModBer "Kupplungsmodulationsbereich
Nur für Handschalter. Wird auf 01 gesetzt, wenn das PWM-Signal des Kupplungspedalsensors im Bereich zwischen 80%-Signalpegel und Minimum liegt.Der Zustand 10b kann derzeit nur von Audi bedient werden, da der PQ46-Sensor keine Plausibilisierung des Signalverlaufes durchführen kann.Gültig für VW: Das Signal wird auf 01 gesetzt, wenn der Kupplungspedalweg von der Stellung unbetätigt aus ca. 50mm überschreitet.";
CM_ SG_ 1472 EP1_AutoHold_zul "Personalisierung Auto Hold zulässig
Mit diesem Bit soll das Kombi den Menüpunkt Auto Hold zur Verfügung stellen und das Bit Auto Hold umschalten (Kombi_3, Byte 3, Bit 6) bedienen.(geplant für PQ46 ab 22/08, VW469)";
CM_ SG_ 1472 EP1_AutoHold_aktiv "Auto Hold aktiviert
Funktion Auto Hold ist in der EPB aktiviert und wird im Kombi zur Anzeige gebracht (nur gültig, wenn Byte 5, Bit 2 Personalisierung zulässt)(geplant für PQ46 ab 22/08, VW469)";
CM_ SG_ 537 EPB_TP_Er "TP 2.0 Eroeffnungskanal
 ";
CM_ SG_ 1386 ACA_ID_StaACC "Index ACC System Status
siehe Schnittstellenbeschreibung ACC/Kombi";
CM_ SG_ 1386 ACA_Fahrerhinw "Ansteuerung optischer Fahrerhinweis
Zur optischen Information des Fahrers, dass Systemgrenze erreicht ist";
CM_ SG_ 1386 ACA_V_Wunsch "Wunschgeschwindigkeit
Anzeige im Kombi, wenn ADR aktiv oder ADR passiv";
CM_ SG_ 1386 ACA_PrioDisp "Anzeige Display Priorität
siehe Schnittstellenbeschreibung ACC/Kombi";
CM_ SG_ 1386 ACA_StaACC "ACC System Status
Status nur zur Anzeige im KombiAchtung: ACC aktiv nicht im Sinne Status ADRsiehe Schnittstellenbeschreibung ACC/Kombi";
CM_ SG_ 1386 ACA_AnzDisplay "Anzeige Display
siehe Schnittstellenbeschreibung ACC/Kombi";
CM_ SG_ 1386 ACA_Zeitluecke "Gesetzte Zeitlücke
Anzeige im Kombi, wenn ADR aktiv oder ADR passiv";
CM_ SG_ 1386 ACA_gemZeitl "Zeitlücke gemessen
Aktuelle Distanz zum vorausfahrenden Fahrzeug, auf das geregelt wird; die Einheit ist Stufen der Zeitlücke (vgl. Gesetzte Zeitlücke)";
CM_ SG_ 1386 ACA_kmh_mph "Info Einheit der Geschwindigkeit
ADR zeigt damit an, dass es mit der Anzeige im Kombi synchronisiert arbeitet";
CM_ SG_ 1386 ACA_Akustik1 "Ansteuerung Akustik 1
Löst niederprioren Gong (´leise´) im Kombi aus und ist im Kombi bei aktuellem Bild mit Anzeigepriorität 2 gekoppelt. Mitteldisplay wird in jedem Fall angezeigt";
CM_ SG_ 1386 ACA_Akustik2 "Ansteuerung Akustik 2
Löst Summer (´laut´) im Kombi aus und ist im Kombi bei aktuellem Bild mit Anzeigepriorität 1 gekoppelt. Mitteldisplay wird in jedem Fall angezeigt";
CM_ SG_ 1386 ACA_Checksum "Checksumme
Prüfsumme, Definition im CAN-Lastenheft";
CM_ SG_ 1386 ACA_Codierung "Sendercodierung
 ";
CM_ SG_ 1386 ACA_Tachokranz "Tachokranz
Zusätzliche Status- und Einstellbereichsanzeige im Tachometer (z. Zt. nur Touareg GP)";
CM_ SG_ 1386 ACA_ACC_Verz "ACC Verzögerung
Bei gesetztem Bit befindet sich das ACC Fahrzeug in einer Verzögerung";
CM_ SG_ 1386 ACA_res_22 " 
Vorhalt Erweiterung Wunschgeschwindigkeit";
CM_ SG_ 1386 ACA_Zaehler "Botschaftszähler
Definition im CAN-Lastenheft";
CM_ SG_ 1386 ACA_res_37 " 
Vorhalt Erweiterung Gong 2 Lautstärke";
CM_ SG_ 1386 ACA_res_45 " 
Vorhalt Erweiterung Zeitlücke gemessen";
CM_ SG_ 1386 ACA_ID_StaGRA "Index GRA Status Anzeige
GRA Zustandsanzeige Ergänzung";
CM_ SG_ 1386 ACA_res_59 " 
Vorhalt Erweiterung";
CM_ SG_ 1386 ACA_res_39 " 
Vorhalt Erweiterung Mute Infotainment";
CM_ SG_ 1386 ACA_Aend_Zeitluecke "Anzeige Änderung Zeitlücke
Anzeige der Zeitlückenänderung im Kombiinstrument (z. Zt. nur Touareg GP)";
CM_ SG_ 1386 ACA_StaGRA "GRA System Status
primäre GRA Zustandsanzeige";
CM_ SG_ 523 ADR_TP_Er "TP 2.0 Eroeffnungskanal
 ";
CM_ SG_ 872 ACS_Schubabsch "Verhinderung Schubabschaltung
 ";
CM_ SG_ 872 ACS_ADR_Schub "ADR Schub
 ";
CM_ SG_ 872 ACS_Checksum "Checksumme
Prüfsumme, Definition im CAN-Lastenheft";
CM_ SG_ 872 ACS_Sta_ADR "Status ADR
Aktivierung ADR durchläuft Algorithmus, in den der GRA_Status (Motor 2) eingeht";
CM_ SG_ 872 ACS_StSt_Info "ACC Start Stopp Info
Stopp-Freigabe/Start-Anforderung für den Start-Stopp-Koordinator0 = Motorlauf langfristig nicht notwendig [Stoppfreigabe] 1 = Motoranlauf nicht zwingend notwendig [Stoppverbot, keine Startanforderung]2 = Motoranlauf zwingend notwendig [Startanforderung]3 = Systemfehler";
CM_ SG_ 872 ACS_Zaehler "Botschaftszähler
Definition im CAN Lastenheft";
CM_ SG_ 872 ACS_MomEingriff "Verhinderung Momenteneingriff
Das Setzen dieses Bits bedeutet, dass kein Momenteneingriff erfolgen soll. Wird für Komfortfunktion verwendet";
CM_ SG_ 872 ACS_FreigSollB "Freigabe Sollbeschleunigung
Beschleunigungsanforderung in Byte 4,5 wird mit diesem Bit aktiviert";
CM_ SG_ 872 ACS_Sollbeschl "Sollbeschleunigung
Byte 4 LSB, Byte 5 (2...0) MSB Eingriff in Motorsteuergerät (aktiv, wenn Byte 3 Bit 7 gesetzt ist)";
CM_ SG_ 872 ACS_res_21 " 
 ";
CM_ SG_ 872 ACS_res_37 " 
 ";
CM_ SG_ 872 ACS_res_35 " 
 ";
CM_ SG_ 872 ACS_Typ_ACC "Typ ACC
Motor plausibilisiert seine eigene Kodierung (z. Zt. nur PQ46)";
CM_ SG_ 872 ACS_Anhaltewunsch "Anhaltewunsch
Erweiterung für ACC Follow to Stop (im PQ46)";
CM_ SG_ 872 ACS_zul_Regelabw "Zulässige Regelabweichung
Betrag der regulär zulässigen Regelabweichung zwischen angefordeter und umgesetzter SollbeschleunigungWird für Komfortfunktion verwendet";
CM_ SG_ 872 ACS_res_36 " 
 ";
CM_ SG_ 872 ACS_max_AendGrad "Maximaler Änderungsgradient
Betrag des max. zulässigen Gradienten zur Änderung der aktuell umgesetzten SollbeschleunigungWird für Komfortfunktion verwendet";
CM_ SG_ 872 ACS_res_56 " 
 ";
CM_ SG_ 872 ACS_res_57 " 
 ";
CM_ SG_ 872 ACS_Fehler "Fehlerspeichereintrag ACC-SG
Bei gesetztem Bit ist mindestens ein Kundendienstfehler eingetragen";
CM_ SG_ 872 ACS_res_58 " 
 ";
CM_ SG_ 872 ACS_res_59 " 
 ";
CM_ SG_ 872 ACS_res_63 " 
 ";
CM_ SG_ 872 ACS_res_60 " 
 ";
CM_ SG_ 872 ACS_res_62 " 
 ";
CM_ SG_ 872 ACS_res_61 " 
 ";
CM_ SG_ 870 AWV_2_Status "AWV2 Statusanzeige
Ansteuerung der Statusanzeige (grüne Lampe)  im Kombiinstrument";
CM_ SG_ 870 AWV_2_SU_Warnzeit "AWV2 Setup Warnzeitpunkt
Eingestellter Warnzeitpunkt(Empfang nur, wenn kein BAP umgesetzt)";
CM_ SG_ 870 AWV_Checksumme "Checksumme (AWV)
Prüfsumme, Definition im CAN-Lastenheft";
CM_ SG_ 870 AWV_Zaehler "Botschaftszähler (AWV)
Freilaufender Botschaftszähler";
CM_ SG_ 870 AWV_2_Fehler "AWV2 Fehleranzeige
Ansteuerung der Fehleranzeige (gelbe Lampe) im Kombiinstrument";
CM_ SG_ 870 AWV_1_Prefill "AWV1 Prefill
Anforderung an ESP, dass Prefill-Funktion aktiviert werden soll. Umsetzung der Prefill-Anforderung im ESP nur in Verbindung mit gesetztem Bit 'AWV1_Freigabe'.";
CM_ SG_ 870 AWV_Text "AWV Textindex
Anforderung an das Kombiinstrument, den ausgewählten Text anzuzeigen0000 kein Text0001 Front Scan aus0010 Front Scan startet0011 Front Scan nicht verfügbar0100 Front Scan Sensor reinigen0101 Front Scan Fehler0110 Front Scan Warnung0111 Vorhalt";
CM_ SG_ 870 AWV_res_20 " 
Reserviert AWV1 Parameter Nachtreten HBA";
CM_ SG_ 870 AWV_1_Freigabe "AWV1 Freigabe
Das Freigabebit muss gesetzt sein, um die Anforderungen 'Prefill' oder 'adaptiver HBA' freizugeben. (HBA = hydraulischer Bremsassistent)";
CM_ SG_ 870 AWV_2_SU_Bremsruck "AWV2 Setup Bremsruck
Einstellung, ob der Fahrer einen Bremsruck erlaubt(Empfang nur, wenn kein BAP umgesetzt)";
CM_ SG_ 870 AWV_1_Parameter "AWV1 Parameter HBA
Anforderung an ESP, welcher HBA-Parametersatz verwendet werden soll. (Die Festlegung der Empfindlichkeitsschwellen der verschiedenen Parametersätze erfolgt mit der Applikation des Gesamtsystems ESP/ACC bzw. des HBA.)Umsetzung der Anforderung im ESP nur in Verbindung mit gesetztem Bit 'AWV1_Freigabe'";
CM_ SG_ 870 AWV_2_Umfeldwarn "AWV2 Umfeldwarnung
Anforderung für eine Warnung des Umfeldes / anderer Verkehrsteilnehmer (z. B. Warnblinken) bei extremen Fahrmanövern";
CM_ SG_ 870 AWV_2_Freigabe "AWV2 Freigabe
Freigabe eines Ruckes  Auswertung des ´AWV2 Ruckprofil bzw. Abbruch eines aktiven Bremsrucks";
CM_ SG_ 870 AWV_2_Gurtstraffer "AWV2 rev. Gurtstraffer
Anforderung an den reversiblen Gurtstraffer, den Gurt zu straffen (z.B. Warnaktuator, Precrash)";
CM_ SG_ 870 AWV_2_SU_Gong "AWV2 Setup Gong
Einstellung, ob der Fahrer eine akustische Warnung erlaubt(Empfang nur, wenn kein BAP umgesetzt)";
CM_ SG_ 870 AWV_Infoton "AWV Infoton
Anforderung an das Kombiinstrument, die Anzeige des ausgwählten Textes (AWV Textindex) mit einer Akustik zu koppeln";
CM_ SG_ 870 AWV_2_Warnsymbol "AWV2 Warnsymbol
Anforderung an das Kombiinstrument eine optische Fahrerwarnung mit hoher Priorität (rote Lampe/Pictogramm) im Mitteldisplay durchzuführen";
CM_ SG_ 870 AWV_2_Warnton "AWV2 Warnton
Anforderung an das Kombiinstrument eine akustische Fahrerwarnung (Summer) durchzuführen";
CM_ SG_ 870 AWV_2_Ruckprofil "AWV2 Ruckprofil
Anforderung an ESP / Boostersteuergerät, welcher Ruck verwendet werden soll. Die Festlegung der Parameter der verschiedenen Ruckprofile erfolgt mit der Applikation des Gesamtsystems ESP/Boostersteuergerät/ACC. Die Umsetzung der Anforderung im ESP/Boostersteuergerät erfolgt nur mit gesetztem Bit ´AWV2 Freigabe";
CM_ SG_ 870 AWV_2_SU_Lampe "AWV2 Setup Lampe
Einstellung, ob der Fahrer eine optische Warnung erlaubt(Empfang nur, wenn kein BAP umgesetzt)";
CM_ SG_ 1652 BAP_Data_ACC " 
 ";
CM_ SG_ 1652 BAP_var_ACC " 
 ";
CM_ SG_ 1688 AFZ_ParaSW_L "AFZ_ParaSW_L
Erst wenn AFS Master und die beiden Scheinwerfer parametriesiert/codiert sind ist die Grundeinstellung möglich";
CM_ SG_ 1688 AFZ_ParaSW_R "AFZ_ParaSW_R
Erst wenn AFS Master und die beiden Scheinwerfer parametriesiert/codiert sind ist die Grundeinstellung möglich";
CM_ SG_ 1688 AFZ_Modus "AFZ_Modus
Touristenlösung über Anpassung anwählbar (Schwenken deaktiviert)";
CM_ SG_ 1688 AFZ_Init "AFZ_Init
Initialisierungslauf beider Kurvenlicht Schrittmotoren, erfolgt defaultmäßig beim Motorstart";
CM_ SG_ 1688 AFZ_SafePos "AFZ_SafePos
AFS Sicherheitsposition beider Scheinwerfer des dyn. Kurvenlichts";
CM_ SG_ 1688 AFZ_IstPosMot_L "AFZ_IstPosMot_L
(Gespiegelt vom AFS-Subbus)Position des Aktuators in Prozent des maximalen Stellweges; vor dem Initialisierungslauf (z. Zt. Motorstart) wird der Initwert ausgegeben0% ist die Position (auf Block) des Schrittmotors100% maximaler Verstellweg des Schrittmotors (nicht die Grenze des Scheinwerfers!)";
CM_ SG_ 1688 AFZ_IstPosMot_R "AFZ_IstPosMot_R
(Gespiegelt vom AFS-Subbus)Position des Aktuators in Prozent des maximalen Stellweges; vor dem Initialisierungslauf (z. Zt. Motorstart) wird der Initwert ausgegeben0% ist die Position (auf Block) des Schrittmotors100% maximaler Verstellweg des Schrittmotors (nicht die Grenze des Scheinwerfers!)";
CM_ SG_ 1688 AFZ_Soll_EVG "AFZ_Soll_EVG
100% entsprechen 35 WattDie Last schaltet nur das ILM";
CM_ SG_ 1688 AFZ_IstDimAbLi "AFZ_IstDimAbLi
(Gespiegelt vom AFS-Subbus)0% - 100% bezogen auf die Versorgungsspannung des linken Moduls";
CM_ SG_ 1688 AFZ_IstDimAbRe "AFZ_IstDimAbRe
(Gespiegelt vom AFS-Subbus)0% - 100% bezogen auf die Versorgungsspannung des rechten Moduls";
CM_ SG_ 1688 AFZ_StaLamp_L "AFZ_StaLamp_L
Statusmeldung des Lampenausfalls für das linke statische Kurvenlicht";
CM_ SG_ 1688 AFZ_StaLamp_R "AFZ_StaLamp_R
Statusmeldung des Lampenausfalls für das rechte statische Kurvenlicht";
CM_ SG_ 1688 AFZ_res_56 " 
 ";
CM_ SG_ 1428 NI2_Hoehe_HR "Höhenwert HR
aktueller Höhensensorwert hinten rechtsim Audi C6, VW D1 ungefiltertes Signal";
CM_ SG_ 1428 NI2_Hoehe_VL "Höhenwert VL
aktueller Höhensensorwert vorne linksim Audi C6, VW D1 ungefiltertes Signal";
CM_ SG_ 1428 NI2_Hoehe_HL "Höhenwert HL
aktueller Höhensensorwert hinten linksim Audi C6, VW D1 ungefiltertes Signal";
CM_ SG_ 1428 NI2_Checksum "Checksumme (Niveau 2)
Prüfsumme, Definition im CAN Lastenheft";
CM_ SG_ 1428 NI2_Hoehe_VR "Höhenwert VR
aktueller Höhensensorwert vorne rechtsim Audi C6, VW D1 ungefiltertes Signal";
CM_ SG_ 1428 NI2_AufbBeschl_VL "Aufbaubeschleunigung VL
Aufbaubeschleunigung VL(für aktive Wankstabilisierung)";
CM_ SG_ 1428 NI2_Zaehler "Zähler (Niveau 2)
Freilaufender Botschaftszähler";
CM_ SG_ 1428 NI2_Reserve1 " 
 ";
CM_ SG_ 1428 NI2_AufbBeschl_VR "Aufbaubeschleunigung VR
Aufbaubeschleunigung VR(für aktive Wankstabilisierung)";
CM_ SG_ 1428 NI2_Hoehe_VL_Roh "Höhenwert VL Rohwerte
aktueller Höhensensorwert vorne links, ungefiltert, Rohwert";
CM_ SG_ 1428 NI2_Hoehe_HR_Roh "Höhenwert HR Rohwerte
aktueller Höhensensorwert hinten rechts, ungefiltert, Rohwert";
CM_ SG_ 1428 NI2_Hoehe_HL_Roh "Höhenwert HL Rohwerte
aktueller Höhensensorwert hinten links, ungefiltert, Rohwert";
CM_ SG_ 1428 NI2_Hoehenflag "Höhenflag
legt fest, wie die Höhenwerte in Byte 3-6 interpretiert werden müssen";
CM_ SG_ 1428 NI2_Hoehe_VR_Roh "Höhenwert VR Rohwerte
aktueller Höhensensorwert vorne rechts, ungefiltert, Rohwert";
CM_ SG_ 524 Daempfer_TP_Er "TP 2.0 Eroeffnungskanal
 ";
CM_ SG_ 1432 DA1_Warnlampe "Gelbe Warnlampe
Dient der Anzeige von Warnungen im Kombiinstrument (nicht Colorado)(nicht Audi D3)";
CM_ SG_ 1432 DA1_Systemstatus "Systemstatus (Dämpfer 1)
Bit wird gesetzt, wenn interne Funktionsprüfung i.O. und System generell funktionsfähig ist.(nicht Audi D3)";
CM_ SG_ 1432 DA1_Taster "Status CDC Taster
Nach Betätigung des Tasters wird das Fahrwerk-Menü im ZAB (D1) aktiviert(nicht Audi D3) Charisma-Taster (PQ35/46)";
CM_ SG_ 1432 DA1_Textbits "Textbits (Dämpfer 1)
Die Textbits werden verwendet, um im Kombi Texte oder Bilder für die Dämpferregelung darzustellen; (nicht Colorado) (nicht Audi D3)Text 1: ´CDC Sport 1´Text 2: ´CDC Sport 2´Text 3: ´CDC Basis´Text 4: ´CDC Komfort´";
CM_ SG_ 1432 DA1_Zaehler "Botschaftszähler
Freilaufender Botschaftszähler";
CM_ SG_ 1432 DA1_res_06 " 
 ";
CM_ SG_ 1432 DA1_Daempferreg "Status Dämpferregelung
Bei Statusänderung wird der Soll-Zustand ausgegeben. Der Status beschreibt einen Papametersatz: Temporäre Änderungen der Dämpfereinstellungen werden hier nicht abgebildet(nicht Audi D3)";
CM_ SG_ 1432 DA1_Checksumme "Checksumme
Prüfsumme, Definition im CAN-Lastenheft";
CM_ SG_ 1432 DA1_Fehlereintr "Fehlerspeichereintrag (Dämpfer 1)
im Fehlerspeicher der Dämpferregelung gibt es einen aktuellen (statischen oder sporadischen) Kundendienst-Fehlerspeichereintrag";
CM_ SG_ 1432 DA1_res_32 " 
 ";
CM_ SG_ 1432 DA1_ESP_Zwang "ESP-Zwangszuschaltung
(nicht Dämpfer PQ35/46)";
CM_ SG_ 1432 DA1_res_24 " 
 ";
CM_ SG_ 1432 DA1_res_18 " 
 ";
CM_ SG_ 1432 DA1_res_40 " 
 ";
CM_ SG_ 1432 DA1_res_48 " 
 ";
CM_ SG_ 1432 DA1_LampPruef "Aufprüfbit Warnlampe
 ";
CM_ SG_ 1432 DA1_Charisma "Charisma aktiv
Gateway erkennt, ob im Dämpfer Charisma aktiv ist und liest ggf. Tasterzustand (Byte 1, Bit 4) ein";
CM_ SG_ 520 RKA_Plus_TP_Er "TP 2.0 Eroeffnungskanal
 ";
CM_ SG_ 1091 RDK_Prio1_Warnung "Prio 1 Warnung fuer Kombi
1 = Prio 1 Warnung";
CM_ SG_ 1091 RDK_FMVSS_138_Warnung "RDK_FMVSS_138_Warnung
1 = Warnlampe FMVSS 138";
CM_ SG_ 1091 RDK_neue_Solldruecke "RDK hat neue Solldruecke erkannt
0 = keine neuen Solldruecke; 1 = es liegen neue Solldruecke vor";
CM_ SG_ 1091 RDK_Ack_IstZu_Solldruecke "Die aktuellen Istdruecke wurden zu neuen Solldruecken uebernommen
1 = Bestaetigung fuer MMI, dass neue Solldruecke ueberwacht werden";
CM_ SG_ 1091 RDK_res11 "n.n.
 ";
CM_ SG_ 1091 RDK_KD_Fehler "Kundendienstfehler
1 = mindestens ein Fehler im Steuergeraet vorhanden";
CM_ SG_ 1091 RDK_res12 "n.n.
 ";
CM_ SG_ 1091 RDK_res13 "n.n.
 ";
CM_ SG_ 1091 RDK_res23 "n.n.
 ";
CM_ SG_ 1091 RDK_res38 "n.n.
 ";
CM_ SG_ 1091 RDK_res22 "n.n.
 ";
CM_ SG_ 1091 RDK_res14 "n.n.
 ";
CM_ SG_ 1091 RDK_res47 "n.n.
 ";
CM_ SG_ 1091 RDK_Prio2_Warnung "Prio 2 Warnung fuer Kombi
1 = Prio 2 Warnung";
CM_ SG_ 1091 RDK_res39 "n.n.
 ";
CM_ SG_ 1091 RDK_Status "Status der RDK
RDK Status Eins/Aus; 0 = System aus; 1 = System ein";
CM_ SG_ 1091 RDK_Warnungen "Warnungen
Warnmeldungen fuers Kombi";
CM_ SG_ 1091 RDK_xx_Color "Farbdarstellung der Reifen im Kombi in Abhaengigkeit von Byte 3, Bit 0...2
0 = gruen; 1 = gelb; 2 = rot (xx = vl, vr, hl, hr, RR)";
CM_ SG_ 1091 RDK_xx_Ist_Temp "Isttemperatur des Reifens in Abhaengigkeit von Byte 3, Bit 0...2
Reifentemperatur_xx (xx = vl, vr, hl, hr)";
CM_ SG_ 1091 RDK_res46 "n.n.
 ";
CM_ SG_ 1091 RDK_xx_Soll_Druck "Solldruck des Reifens in Abhaengigkeit von Byte 3, Bit 0...2
Sollreifendruck_xx (xx = vl, vr, hl, hr, RR)";
CM_ SG_ 1091 RDK_xx_Status_Sensor "Status des einzelnen Sensors in Abhaengigkeit von Byte 3, Bit 0...2
0 = Sensorwert ungueltig; 1 = Sensorwert gueltig (xx = vl, vr, hl, hr, RR)";
CM_ SG_ 1091 RDK_Sensor_Multiplex "Multiplexinformation fuer die Auswahl eines Reifens
0x00 = vl; 0x01 = vr; 0x02 = hl; 0x03 = hr; 0x04 = RR;";
CM_ SG_ 1091 RDK_xx_Ist_Druck "Istdruck des Reifens in Abhaengigkeit von Byte 3, Bit 0...2
Istreifendruck_xx (xx = vl, vr, hl, hr)";
CM_ SG_ 1091 RDK_FMVSS_138_MIL "RDK_FMVSS_138_MIL
 ";
CM_ SG_ 514 Getriebe_TP_Er "TP 2.0 Eroeffnungskanal
 ";
CM_ SG_ 1344 GE2_Sta_ZwGas "Zwischengasflag
Byte 4,5 und 6 sollen ausgeführt werdenHybrid:Falls Bit 3 aktiv, dann sollen Byte 4, 5 und 6 ausgeführt werden.- falls Bit 3 und Bit 2 aktiv: DZ-Vorgabe von Getriebe im Low-Speed-Modus (s. Byte 7 Bit 3 (Motor_Hybrid_1)).- Falls Bit 3 aktiv und Bit 2 nicht aktiv: ZG-Eingriff.Falls Senderkennung = 1 (MSG): Bedienung mit Initwert";
CM_ SG_ 1344 GE2_Sta_SAS "Schubabschaltunterstützung
Wenn die SAS-Unterstützung aktiv ist, wird vom VL30-Steuergerät sichergestellt, daß die Kupplung nicht schlagartig geöffnet wird.Falls Senderkennung = 1 (MSG): Bedienung mit Initwert";
CM_ SG_ 1344 GE2_SlipStDZEingr "DZ-Eingriff Slip-Start
(war Ecomatic)Hybrid:PL71H: Falls Bit 2 aktiv und Bit 3 nicht aktiv, dann wird ein DZ-Eingriff wegen einer Wiederstartanforderung durchgeführt: Byte 4, 5 und 6 sollen ausgeführt werden.PL71H/PQ35H: Verwendung für DZ-Eingriff Low-Speed-Mode";
CM_ SG_ 1344 GE2_LFR_Adap "LFR-Adaption Freigabeflag
Da das VL30-Getriebe im Stillstand unter gewissen Randbedingungen wechselnde Kupplungsmomente ein-stellt (z.B. Hillholder), sollte die Leerlauffüllungsadaption im Motorsteuergerät für diese Zustände gesperrt werdenFalls Senderkennung = 1 (MSG): Bedienung mit Initwert";
CM_ SG_ 1344 GE2_Zaehler "Botschaftszähler (Getriebe 2)
Überwachung von Byte 4 und 5; Zähler läuft synchron mit Zähler in Getriebe 1 Bedienung unabhängig von Senderkennung";
CM_ SG_ 1344 GE2_Grad_begr "Gradientenbegrenzung
Drehmomenten-Gradientenbegrenzung für Teillastanfahrten mit dem VL30-Getriebe und Standabkopplung beim 5HP19Hybrid (Signal Gradientenbegrenzung Summenmoment):Soll für Summenmoment VM + EM gelten. Soll auch negative Gradienten (Rekuperation) gelten!Falls Senderkennung = 1 (MSG): Bedienung mit Initwert";
CM_ SG_ 1344 GE2_LL_Solldz "Leerlaufsolldrehzahl (Getriebe 2)
Wunschvorgabewert vom CVT Getriebe, 5HP19, 5HP24 und ASG an MotorHybrid:Getriebe kann auch im Low-Speed-Modus Verbrenner-LLSoll-DZ anfordern (Spiegelung Byte 6 aus Motor 2)Falls Senderkennung = 1 (MSG): Bedienung mit Initwert";
CM_ SG_ 1344 GE2_Sync_Zeit "Synchronisationszeit
Falls Senderkennung = 1 (MSG): Bedienung mit Initwert";
CM_ SG_ 1344 GE2_DZM_Daempf "Drehzahlmesserdämpfung
Beim Getriebe kann die Anzeigedämpfung des Drehzahlmessers beim Schalten geändert werdenFalls Senderkennung = 1 (MSG): Bedienung mit Initwert";
CM_ SG_ 1344 GE2_Fehlertext_Freigabe "Fehlertext Freigabe
(war Unterdrückung von Warnungen)Ausgabe der Fehlertexte im Kombi wird freigegeben. Der Inhalt der Texte wird über WBA_Blinken gesteuert (nur Audi C6/AU716)Falls Senderkennung = 1 (MSG): Bedienung mit Initwert";
CM_ SG_ 1344 GE2_Gong "Gong / Kupplungstemperaturwarnung
wichtiger Warnhinweis vom Getriebe: Textanzeige Kupplungstemperaturwarnung für DQ-Getriebe: ´Stop Anhalten Getriebe´ (z. Zt. noch Vorhalt)Falls Senderkennung = 1 (MSG): Bedienung mit Initwert";
CM_ SG_ 1344 GE2_Senderkennung "Senderkennung
(war ECO-Anzeige)Die Botschaft Getriebe 2 wird vom Automatgetriebe gesendet, bei Handschaltern alternativ vom Motor. Das Getriebe stellt damit die Wählbereichsanzeige dar, der Motor beim Handschalter die Hochschaltaufforderung für den Fahrer im Kombi. Zur Unterscheidung der Anzeigestrategie des Senders für das Kombi wird deswegen eine Information benötigt, die den jeweiligen Sender kennzeichnet. Anhand des Senders ändert sich die Bedeutung der Inhalte der Botschaft, weil funktional verschi";
CM_ SG_ 1344 GE2_Shift_Lock "Shift-Lock-Lampe
Wählhebel ist durch Shift-Lock Funktion blockiertFalls Senderkennung = 1 (MSG): Bedienung mit Initwert";
CM_ SG_ 1344 GE2_Variante "Ganganzeige Kombi Getriebe Variante / Istgang
vgl. Multiplex-InformationFalls Senderkennung = 1 (MSG): Wenn Motor die Botschaft sendet wird in diesem Signal der aktuelle Gang ausgegeben (= Istgang des Schaltgetriebes).";
CM_ SG_ 1344 GE2_Sync_Dz "Synchronisations-Wunschdrehzahl
Drehzahlverhalten zu Schaltvorgang(Bei Selespeed-Getriebe im AU714 größerer Wertebereich 0-8128 mit Auflösung 32/min)Hybrid:ASG-Drehschnittstelle soll bei Hybrid implementiert sein.Neu: Soll auch tauglich sein für DZ-reduzierende Eingriffe!Falls Senderkennung = 1 (MSG): Bedienung mit Initwert";
CM_ SG_ 1344 GE2_invMSB_Sync "Invertiertes MSB Synchronisations Wunschdrehzahl
(war: Starter wird angesteuert)bitinvertiertes Byte 7, Bit 6Falls Senderkennung = 1 (MSG): Bedienung mit 0";
CM_ SG_ 1344 GE2_WBA_Blinken "Fehlerlampe für Kupplung / WBA Blinken
Dieses Bit steuert die Fehlerlampe an oder wird zum Blinken der WBA-Anzeige genutzt (5HP, 6HP, PNG, ASG, VL30)Falls Senderkennung = 1 (MSG): Bedienung mit Initwert";
CM_ SG_ 1344 GE2_MSB_Sync "MSB Synchronisations Wunschdrehzahl
(war: Anforderung Kriechadaptionsmodus)Bei gesetztem Bit sind zu der Synchronisationswunschdrehzahl in Byte 4 6400 /min (Selespeed 8192) zu addieren. Inverses Bit in Byte 7, Bit 1 beachtenFalls Senderkennung = 1 (MSG): Bedienung mit Initwert";
CM_ SG_ 1344 GE2_5Gang "5-Gang Automat
5-Gang Automat (PRND432)";
CM_ SG_ 1344 GE2_invSync_Dz "invertierte Synchronisations Wunschdrehz.
bitinvertiertes Byte 4(Bei Selespeed-Getriebe im AU714 größerer Wertebereich 0-8128 mit Auflösung 32/min)Hybrid:ASG-Drehschnittstelle soll bei Hybrid implementiert sein.Neu: Soll auch tauglich sein für DZ-reduzierende Eingriffe!Falls Senderkennung = 1 (MSG): Bedienung mit Initwert";
CM_ SG_ 1344 GE2_PRND "Automat PRND
Automat (PRND) (4/5/6-Gang), z.B. CVT-Getriebe";
CM_ SG_ 1344 GE2_4Gang "4-Gang Automat
4-Gang Automat (PRND321)";
CM_ SG_ 1344 GE2_Tip4Gang "4 Gang Automat Tiptronic
4 Gang Automat Tiptronic";
CM_ SG_ 1344 GE2_akt_Gang "eingelegte Fahrstufe / Sollgang
aktuell eingelegter GangFalls Senderkennung = 1 (MSG):Motor sendet den Sollgang in den der Fahrer schalten soll. Wird im Kombi als Hochschaltempfehlung hervorgehoben.";
CM_ SG_ 1344 GE2_Tip6Gang "6 Gang Automat Tiptronic
6 Gang Automat Tiptronic";
CM_ SG_ 1344 GE2_ASG "ASG-Getriebe
ASG-Getriebe";
CM_ SG_ 1344 GE2_PRNDS "Automat PRNDS
Automat (PRNDS) (4/5/6-Gang)";
CM_ SG_ 1344 GE2_Tip7Gang "7 Gang Automat Tiptronic
7 Gang Automat Tiptronic";
CM_ SG_ 1344 GE2_Selespeed "Selespeed-Getriebe
Selespeed-GetriebeBesonderheit Selespeed:0000: Es wird nur ein M angezeigt. Diese Anzeige erfolgt, wenn das Getriebe keine Gangposition bestimmen kann. Selespeed besitzt keine Normaldarstellung wie ein echter Automat. Die Fahrstufen M/S/A sind zueinander kombinierbar, im Defaultzustand steht nur ein M in der Anzeige zum Kombi.0001: Es wird nur ein M angezeigt. Die Anzeige ist komplett invertiert. Anzeige für Getriebefehler und Notlauf**: N bei eingelegter Gang ist bei Selespeed erford";
CM_ SG_ 1344 GE2_Tip5Gang "5 Gang Automat Tiptronic
5 Gang Automat Tiptronic (auch im 3l Auto)";
CM_ SG_ 1346 GE5_Ausl_Winter "Wählhebelausleuchtung Winter
Mit dieser Botschaft wird Ausleuchtung der Winterfunktion am Wählhebel gesteuert";
CM_ SG_ 1346 GE5_Test "Testfreigabeflag
Controllertest mit den Testparametern 1+2 durchführen";
CM_ SG_ 1346 GE5_Testparam_1 "Testparameter 1
Testparameter 1 zum Funktionstest des Wählhebel-Controllers";
CM_ SG_ 1346 GE5_Ausleuchtung "Wählhebelausleuchtung Istgang
Mit dieser Botschaft wird die aktive Istgangausleuchtung des Wählhebels gesteuert.";
CM_ SG_ 1346 GE5_Ausl_Sport "Wählhebelausleuchtung Sport
Mit dieser Bit wird Ausleuchtung der Sportfunktion am Wählhebel gesteuert";
CM_ SG_ 1346 GE5_Abschalten "Wählhebelmodul abschalten
Mit diesem Bit kann das Getriebe den Wählhebel im Fehlerfall deaktivieren. Der Wählhebel geht dann in einen Standby-Modus. Alle Wählhebelanzeigen blinken.";
CM_ SG_ 1346 GE5_Sta_Fahrstufe "Fahrstufeninformation ungültig
Kann das Getriebe keine Information über die aktuell eingelegte Fahrstufe an den Wählhebel übergeben, so wird dieses Bit gesetzt. Am Wählhebel wird keine Fahrstufe angezeigt, solange das Bit gesetzt ist.";
CM_ SG_ 1346 GE5_res_07 " 
 ";
CM_ SG_ 1346 GE5_Testparam_2 "Testparameter 2
Testparameter 2 zum Funktionstest des Wählhebel-Controllers";
CM_ SG_ 1348 GE7_Text_01 "Textmeldung Kupplungsschutz
Bit schaltet Textmeldung im Kombi als Fahrerhinweis:Wenn die Kupplungsschutzfunktion des Selespeed-Getriebes aktiv ist, wird über diesen Text der Fahrer informiert.";
CM_ SG_ 1348 GE7_Text_04 "Textmeldung Motorstart Selespeed
Bit schaltet Textmeldung im Kombi als Fahrerhinweis: ´Zum Starten des Motors Bremse betätigen´Das Bit wird gesetzt, wenn der Fahrer den Motor zu starten versucht ohne die Bremse zu betätigen, wird vom Getriebe über eine diskrete Leitung der Motorstart verhindert. Der Text fordert den Fahrer auf die Bremse zu betätigen.";
CM_ SG_ 1348 GE7_Text_05 "Textmeldung Soft-Shiftlock Selespeed
Bit schaltet Textmeldung im Kombi als Fahrerhinweis:´Zum Einlegen einer Fahrstufe im Stand Fussbremse betätigen´";
CM_ SG_ 1348 GE7_Text_03 "Textmeldung Wegrollwarnung 2
Bit schaltet Textmeldung im Kombi als Fahrerhinweis:´Gang nicht eingelegt´Wenn sich das Getriebe nach KL15-Aus nicht im wegrollsicheren Zustand befindet, wird der Fahrer aufgefordert durch Tippen des Wählhebels einen Gang einzulegen";
CM_ SG_ 1348 GE7_Gong "Gong
Selespeed-Getriebe kann den Fahrer in bestimmten Situationen durch einen Gong zusätzlich warnen";
CM_ SG_ 1348 GE7_Text_02 "Textmeldung Wegrollwarnung 1
Bit schaltet Textmeldung im Kombi als Fahrerhinweis:´Handbremse nicht betätigt´Wenn sich das Getriebe nach KL15-Aus nicht im wegrollsicheren Zustand befindet, wird der Fahrer aufgefordert die Handbremse zu ziehen";
CM_ SG_ 1348 GE7_res_11 " 
 ";
CM_ SG_ 1348 GE7_res_12 " 
 ";
CM_ SG_ 1348 GE7_res_15 " 
 ";
CM_ SG_ 1348 GE7_res_13 " 
 ";
CM_ SG_ 1348 GE7_res_17 " 
 ";
CM_ SG_ 1348 GE7_res_18 " 
 ";
CM_ SG_ 1348 GE7_res_16 " 
 ";
CM_ SG_ 1348 GE7_res_19 " 
 ";
CM_ SG_ 1348 GE7_res_20 " 
 ";
CM_ SG_ 1348 GE7_res_14 " 
 ";
CM_ SG_ 1348 GE7_res_21 " 
 ";
CM_ SG_ 1348 GE7_res_22 " 
 ";
CM_ SG_ 1348 GE7_res_23 " 
 ";
CM_ SG_ 1348 GE7_res_25 " 
 ";
CM_ SG_ 1348 GE7_res_27 " 
 ";
CM_ SG_ 1348 GE7_res_24 " 
 ";
CM_ SG_ 1348 GE7_res_26 " 
 ";
CM_ SG_ 1348 GE7_res_29 " 
 ";
CM_ SG_ 1348 GE7_res_30 " 
 ";
CM_ SG_ 1348 GE7_res_28 " 
 ";
CM_ SG_ 1348 GE7_res_31 " 
 ";
CM_ SG_ 1348 GE7_Text_07 "Textmeldung Rückwärtsgang ausgefallen
Bit schaltet Prio 2 Warnung im Display des Kombis:Rückwärtsgang nicht schaltbar";
CM_ SG_ 1348 GE7_Feh_2Warn "Fehler 2. Warnschwelle
Text Prio2-Meldung ´Getriebefehler: Weiterfahrt nur eingeschränkt möglich´ + gelbes Getriebefehlersymbol";
CM_ SG_ 1348 GE7_Waehlh_ausgef "Wählhebel ausgefallen
Ist der Wählhebel nicht mehr in der Lage eine gültige Position an das Getriebesteuergerät zu ermitteln, so wird dieses Bit gesetzt und im Kombiinstrument erscheint die Priorität 2 Warnmeldung ´Wählhebel defekt, kein R-Gang´.";
CM_ SG_ 1348 GE7_Feh_1Warn "Fehler 1. Warnschwelle
Text Prio2-Meldung ´Getriebefehler: Weiterfahrt möglich´ + gelbes Getriebefehlersymbol";
CM_ SG_ 1348 GE7_SyncWarn "Synchronisation Meldungen bei Kl.-15 aus
tbd";
CM_ SG_ 1088 GE1_Klimakompr "Klimakompressor aus (Getriebe 1)
Weiterleiten an Motor, der Klima ausschaltet";
CM_ SG_ 1088 GE1_Sta_Schutz "Status Getriebe und Wandlerschutz
Umschaltung permanente Leistungsreduzierung (Ein-spritzausblendung) oder Zündwinkelverstellung (Otto)Hybrid:Langsamer Eingriff soll für Hybrid implementiert werden.";
CM_ SG_ 1088 GE1_Zielgang "Zielgang oder eingelegter Gang
Zielgang, wenn Schaltung aktiv";
CM_ SG_ 1088 GE1_EGS_Anf "EGS-Anforderung
Byte 4 wird damit gültig";
CM_ SG_ 1088 GE1_Soll_Mo "Inneres Soll-Motormoment
Getriebeeingriff an den MotorHybrid:Getriebeeingriff auf indiziertes Moment (Absolutwert)";
CM_ SG_ 1088 GE1_WK "Wandlerkupplung
auch für Anfahrkupplung beim VL30 und Kupplung beim Ecodrive (geregelt bedeutet in diesem Fall die Kupplung ist nicht vollständig getrennt bzw hat Schlupf) genutzt; bei starken Verstellwegen wird geöffnet gesendet (VQ250)";
CM_ SG_ 1088 GE1_Schaltung "Schaltung aktiv (Getriebe 1)
 ";
CM_ SG_ 1088 GE1_Mrad_Mkurb "Übertragungsfunktion
Mrad / Mkurbelwelle";
CM_ SG_ 1088 GE1_Zaehler "Botschaftszähler (Getriebe 1)
Zähler läuft synchron mit dem Zähler in der Getriebe 2 Botschaft (zur Sicherstellung der Synchronität)";
CM_ SG_ 1088 GE1_Infobit "Getriebeinfobit
CVT-Getriebe (VL30,..) setzen Bit auf 1; Sonstige Getriebe (z. B. Stufenautomat) geben 0 aus";
CM_ SG_ 1088 GE1_Fahrwistd "Fahrwiderstandsindex
auf % Steigung am Berg normiert";
CM_ SG_ 1088 GE1_Wahl_Pos "Wählhebelposition / Fahrprogramm
bei Selespeed Bedeutung ´Fahrprogramm´, da keine Wählhebelgasse vorhanden istAnmerkung: Empfänger erwartet ´P´ wegen Zündschlüsselabzugsperre.Das Selespeed-Getriebe (automatisierter Handschalter) hat den Zustand ´P´ nicht, bedient aber den Wert (08H), wenn sich das Getriebe nach Kl. 15 aus in sicherem Zustand befindet.";
CM_ SG_ 1088 GE1_LaunchControl "LaunchControl
Während einer LaunchControl-Anfahrt sendet das Getriebesteuergerät das Bit LaunchControl_aktiv. Die Bremse wertet dieses Bit aus, um während einer solchen Anfahrt die Regelgrenzen der Schlupfregelung zu erweitern (z. Zt. nur DQ250)";
CM_ SG_ 1088 GE1_Fehlereintr "Fehlerspeichereintrag (Getriebe 1)
Bei gesetztem Bit ist mindestens ein Kundendienstfehler eingetragen";
CM_ SG_ 1088 GE1_v_Umkehr "Geschwindigkeit Umkehr
Bremse verhindert, dass das Fahrzeug beim Schalten des Längsgetriebes (Getriebe in N) zurückrollt. Nur Colorado!";
CM_ SG_ 1088 GE1_SleepInd "Sleep Indication
Die Sleep-Bereitschaft wird nach Klemme 15 aus durch Setzen dieses Bits signalisiertNMHigh-Teilnehmer der PQ35/46 müssen das Signal nach Kl.-15 aus weiterhin bedienen oder dauerhaft auf 1 = Sleep bereit setzen!";
CM_ SG_ 1088 GE1_Notlauf "Getriebe-Notlauf
Notlauf:0000B kein Notlauf; Gangwechsel=0; Zielgang erreicht=00001B kein Schalten0010B Schalten nach n0011B 50% Schalten0100B Fahren ohne ÜK0101B kein Notlauf; Gangwechsel=0; Zielgang erreicht=10110B kein Notlauf; Gangwechsel=1; Zielgang erreicht=00111B kein Notlauf; Gangwechsel=1; Zielgang erreicht=11xxxB reduziertes Anfahrmoment gefordert, Fehler muss im Getriebesteuergerät abgelegt sein!1111B TotalausfallKodierung für Gangwechsel / Zielgang erreicht ist vorerst speziell für ZF-Getrieb";
CM_ SG_ 1088 GE1_WaVerl_Mo "Getriebeverlustmoment
Kupplungsmoment bei ASG / DQ-Getriebe ; wird als Vorsteuermoment für LFR genutzt; Gesamtes Aufnahmemoment des GetriebesHybrid:Kriechvorsteuerung soll bei Hybrid PL71 und PQ35 implementiert sein.PL71H: im Low-Speed-Modus (elektrisch mit geschlossenem Triebstrang) ist das übermittelte Moment als Fahrmoment umzusetzen.";
CM_ SG_ 1088 GE1_Kuehlung "Kühlleistung
00: keine zusätzliche Kühlleistung ; 01: Lüfterleistung um 20% erhöhen ; 10: Lüfterleistung um 40% erhöhen, Wassertemp. 10  ; 11: maximale Lüfterleistung; Wassertemp. Senken (max)";
CM_ SG_ 1088 GE1_Sta_OBD "OBD Status
Bit 7 steuert (nicht mehr Bit 6) die MIL-Lampe an (Motor-SG reicht diese Info an Kombi weiter)";
CM_ SG_ 1088 GE1_StSt_Info "Getriebe Start Stopp Info
Stopp-Freigabe/Start-Anforderung für den Start-Stopp-Koordinator(Verriegelt über Systemstatus Start/Stopp wegen ESP8 bei AUDI und ggf. alter Motoren: Getriebe darf nur einen Wert ungleich 0 senden, wenn mMotor_10 empfangen wurde und der ´Systemstatus Start Stopp´ ungleich 0 ist.) (Bit 5 war: ´Leerlaufsolldrehzahl-Anhebung´ (z.B. Erhöhung des Pumpendrucks beim CVT-Getriebe))(Bit 6 war: ´Kodierung im MSG´ (Getriebe-Kodierung im Motor-Steuergerät ist in Ordnung))";
BA_DEF_ BO_  "VAGTP20_API" HEX 0 255;
BA_DEF_ BO_  "VAGTP20_StatConnection" ENUM  "No","Yes";
BA_DEF_ BO_  "VAGTP20_DynConnection" ENUM  "No","Yes";
BA_DEF_ BO_  "VAGTP20_DynSetup" ENUM  "No","Yes";
BA_DEF_ BO_  "NmMessage" ENUM  "No","Yes";
BA_DEF_ BO_  "NmhMessage" ENUM  "No","Yes";
BA_DEF_ BO_  "GenMsgCycleTime" INT 0 65535;
BA_DEF_ BO_  "GenMsgSendType" ENUM  "cyclicX","spontanX","cyclicIfActiveX","spontanWithDelay","cyclicAndSpontanX","cyclicAndSpontanWithDelay","spontanWithRepitition","cyclicIfActiveAndSpontanWD","NoMsgSendType","cyclicWithRepeatOnDemand";
BA_DEF_ BO_  "GenMsgCycleTimeFast" INT 0 65535;
BA_DEF_ BO_  "GenMsgNrOfRepetition" INT 0 255;
BA_DEF_ BO_  "GenMsgDelayTime" INT 0 100000;
BA_DEF_ BO_  "GenMsgILSupport" ENUM  "No","Yes";
BA_DEF_ BO_  "GenMsgTimeoutTime" INT 0 100000;
BA_DEF_ BO_  "GenMsgAutoGenDsp" ENUM  "No","Yes";
BA_DEF_ BO_  "GenMsgAutoGenSnd" ENUM  "No","Yes";
BA_DEF_ BO_  "DiagRequest" ENUM  "No","Yes";
BA_DEF_ BO_  "DiagResponse" ENUM  "No","Yes";
BA_DEF_ BO_  "DiagState" ENUM  "No","Yes";
BA_DEF_ SG_  "GenSigSendType" ENUM  "Cyclic","OnWrite","OnWriteWithRepetition","OnChange","OnChangeWithRepetition","IfActive","IfActiveWithRepetition","NoSigSendType";
BA_DEF_ SG_  "GenSigStartValue" INT 0 4294967295;
BA_DEF_ SG_  "GenSigInactiveValue" INT 0 2147483647;
BA_DEF_ SG_  "GenSigAutoGenDsp" ENUM  "No","Yes";
BA_DEF_ SG_  "GenSigAutoGenSnd" ENUM  "No","Yes";
BA_DEF_ SG_  "GenSigEnvVarType" STRING ;
BA_DEF_ SG_  "GenSigFuncType" ENUM  "NoFunction","MsgCounter","CRC-8","XOR","XOR-2","DatedBit","SW-Kl15","CHK","Constant","Protokoll";
BA_DEF_ SG_  "NWM-WakeUpAllowed" ENUM  "No","Yes";
BA_DEF_ SG_  "INIT" STRING ;
BA_DEF_ SG_  "GenSigTimeoutMsg_Airbag" HEX 0 2047;
BA_DEF_ SG_  "GenSigTimeoutTime_Airbag" INT 0 65535;
BA_DEF_ SG_  "GenSigTimeoutMsg_Allrad" HEX 0 2047;
BA_DEF_ SG_  "GenSigTimeoutTime_Allrad" INT 0 65535;
BA_DEF_ SG_  "GenSigTimeoutMsg_Lenkhilfe_ZF_2" HEX 0 2047;
BA_DEF_ SG_  "GenSigTimeoutTime_Lenkhilfe_ZF_2" INT 0 65535;
BA_DEF_ SG_  "GenSigTimeoutMsg_Teves_MK60_ESP" HEX 0 2047;
BA_DEF_ SG_  "GenSigTimeoutTime_Teves_MK60_ESP" INT 0 65535;
BA_DEF_ SG_  "GenSigTimeoutMsg_LWS" HEX 0 2047;
BA_DEF_ SG_  "GenSigTimeoutTime_LWS" INT 0 65535;
BA_DEF_ SG_  "GenSigTimeoutMsg_LWR" HEX 0 2047;
BA_DEF_ SG_  "GenSigTimeoutTime_LWR" INT 0 65535;
BA_DEF_ SG_  "GenSigTimeoutMsg_Teves_MK70_MAB" HEX 0 2047;
BA_DEF_ SG_  "GenSigTimeoutTime_Teves_MK70_MAB" INT 0 65535;
BA_DEF_ SG_  "GenSigTimeoutMsg_Waehlhebel" HEX 0 2047;
BA_DEF_ SG_  "GenSigTimeoutTime_Waehlhebel" INT 0 65535;
BA_DEF_ SG_  "GenSigTimeoutMsg_EPB" HEX 0 2047;
BA_DEF_ SG_  "GenSigTimeoutTime_EPB" INT 0 65535;
BA_DEF_ SG_  "GenSigTimeoutMsg_TRW_ESP" HEX 0 2047;
BA_DEF_ SG_  "GenSigTimeoutTime_TRW_ESP" INT 0 65535;
BA_DEF_ SG_  "GenSigTimeoutMsg_ACC_Radar" HEX 0 2047;
BA_DEF_ SG_  "GenSigTimeoutTime_ACC_Radar" INT 0 65535;
BA_DEF_ SG_  "GenSigTimeoutMsg_AFS" HEX 0 2047;
BA_DEF_ SG_  "GenSigTimeoutTime_AFS" INT 0 65535;
BA_DEF_ SG_  "GenSigTimeoutMsg_Magne_Ride" HEX 0 2047;
BA_DEF_ SG_  "GenSigTimeoutTime_Magne_Ride" INT 0 65535;
BA_DEF_ SG_  "GenSigTimeoutMsg_RKA_Plus" HEX 0 2047;
BA_DEF_ SG_  "GenSigTimeoutTime_RKA_Plus" INT 0 65535;
BA_DEF_ SG_  "GenSigTimeoutMsg_Selespeed" HEX 0 2047;
BA_DEF_ SG_  "GenSigTimeoutTime_Selespeed" INT 0 65535;
BA_DEF_ SG_  "GenSigTimeoutMsg_Waehlhebel_Sel" HEX 0 2047;
BA_DEF_ SG_  "GenSigTimeoutTime_Waehlhebel_Sel" INT 0 65535;
BA_DEF_ SG_  "GenSigTimeoutMsg_PDC_PLA" HEX 0 2047;
BA_DEF_ SG_  "GenSigTimeoutTime_PDC_PLA" INT 0 65535;
BA_DEF_ SG_  "GenSigTimeoutMsg_Lenkhilfe_APA" HEX 0 2047;
BA_DEF_ SG_  "GenSigTimeoutTime_Lenkhilfe_APA" INT 0 65535;
BA_DEF_ SG_  "GenSigTimeoutMsg_VAQ" HEX 0 2047;
BA_DEF_ SG_  "GenSigTimeoutTime_VAQ" INT 0 65535;
BA_DEF_ SG_  "GenSigTimeoutMsg_Daempfer" HEX 0 2047;
BA_DEF_ SG_  "GenSigTimeoutTime_Daempfer" INT 0 65535;
BA_DEF_ SG_  "GenSigTimeoutMsg_Hybrid_BMS" HEX 0 2047;
BA_DEF_ SG_  "GenSigTimeoutTime_Hybrid_BMS" INT 0 65535;
BA_DEF_ SG_  "GenSigTimeoutMsg_Hybrid_PWR" HEX 0 2047;
BA_DEF_ SG_  "GenSigTimeoutTime_Hybrid_PWR" INT 0 65535;
BA_DEF_ SG_  "GenSigTimeoutMsg_Hybrid_DQ200" HEX 0 2047;
BA_DEF_ SG_  "GenSigTimeoutTime_Hybrid_DQ200" INT 0 65535;
BA_DEF_ SG_  "GenSigTimeoutMsg_EKlimakomp" HEX 0 2047;
BA_DEF_ SG_  "GenSigTimeoutTime_EKlimakomp" INT 0 65535;
BA_DEF_ SG_  "GenSigTimeoutMsg_SWA" HEX 0 2047;
BA_DEF_ SG_  "GenSigTimeoutTime_SWA" INT 0 65535;
BA_DEF_ SG_  "GenSigTimeoutMsg_HCA" HEX 0 2047;
BA_DEF_ SG_  "GenSigTimeoutTime_HCA" INT 0 65535;
BA_DEF_ SG_  "GenSigTimeoutMsg_ACC_Lidar" HEX 0 2047;
BA_DEF_ SG_  "GenSigTimeoutTime_ACC_Lidar" INT 0 65535;
BA_DEF_ SG_  "GenSigTimeoutMsg_Lenkhilfe_ZF_3" HEX 0 2047;
BA_DEF_ SG_  "GenSigTimeoutTime_Lenkhilfe_ZF_3" INT 0 65535;
BA_DEF_ SG_  "GenSigTimeoutMsg_FLA" HEX 0 2047;
BA_DEF_ SG_  "GenSigTimeoutTime_FLA" INT 0 65535;
BA_DEF_ SG_  "GenSigTimeoutMsg_AG6" HEX 0 2047;
BA_DEF_ SG_  "GenSigTimeoutTime_AG6" INT 0 65535;
BA_DEF_ SG_  "GenSigTimeoutMsg_DQ" HEX 0 2047;
BA_DEF_ SG_  "GenSigTimeoutTime_DQ" INT 0 65535;
BA_DEF_ SG_  "GenSigTimeoutMsg_Hybrid_MSG" HEX 0 2047;
BA_DEF_ SG_  "GenSigTimeoutTime_Hybrid_MSG" INT 0 65535;
BA_DEF_ SG_  "GenSigTimeoutMsg_Diesel" HEX 0 2047;
BA_DEF_ SG_  "GenSigTimeoutTime_Diesel" INT 0 65535;
BA_DEF_ SG_  "GenSigTimeoutMsg_Otto" HEX 0 2047;
BA_DEF_ SG_  "GenSigTimeoutTime_Otto" INT 0 65535;
BA_DEF_ SG_  "GenSigTimeoutMsg_Gateway_PQ35_A" HEX 0 2047;
BA_DEF_ SG_  "GenSigTimeoutTime_Gateway_PQ35_A" INT 0 65535;
BA_DEF_ SG_  "GenSigTimeoutMsg_Gateway_PQ46_A" HEX 0 2047;
BA_DEF_ SG_  "GenSigTimeoutTime_Gateway_PQ46_A" INT 0 65535;
BA_DEF_DEF_  "VAGTP20_API" 0;
BA_DEF_DEF_  "VAGTP20_StatConnection" "No";
BA_DEF_DEF_  "VAGTP20_DynConnection" "No";
BA_DEF_DEF_  "VAGTP20_DynSetup" "No";
BA_DEF_DEF_  "NmMessage" "No";
BA_DEF_DEF_  "NmhMessage" "No";
BA_DEF_DEF_  "GenMsgCycleTime" 0;
BA_DEF_DEF_  "GenMsgSendType" "NoMsgSendType";
BA_DEF_DEF_  "GenMsgCycleTimeFast" 0;
BA_DEF_DEF_  "GenMsgNrOfRepetition" 0;
BA_DEF_DEF_  "GenMsgDelayTime" 0;
BA_DEF_DEF_  "GenMsgILSupport" "No";
BA_DEF_DEF_  "GenMsgTimeoutTime" 0;
BA_DEF_DEF_  "GenMsgAutoGenDsp" "Yes";
BA_DEF_DEF_  "GenMsgAutoGenSnd" "Yes";
BA_DEF_DEF_  "DiagRequest" "No";
BA_DEF_DEF_  "DiagResponse" "No";
BA_DEF_DEF_  "DiagState" "No";
BA_DEF_DEF_  "GenSigSendType" "NoSigSendType";
BA_DEF_DEF_  "GenSigStartValue" 0;
BA_DEF_DEF_  "GenSigInactiveValue" 0;
BA_DEF_DEF_  "GenSigAutoGenDsp" "Yes";
BA_DEF_DEF_  "GenSigAutoGenSnd" "Yes";
BA_DEF_DEF_  "GenSigEnvVarType" "Undef";
BA_DEF_DEF_  "GenSigFuncType" "NoFunction";
BA_DEF_DEF_  "NWM-WakeUpAllowed" "No";
BA_DEF_DEF_  "INIT" "";
BA_DEF_DEF_  "GenSigTimeoutMsg_Airbag" 0;
BA_DEF_DEF_  "GenSigTimeoutTime_Airbag" 0;
BA_DEF_DEF_  "GenSigTimeoutMsg_Allrad" 0;
BA_DEF_DEF_  "GenSigTimeoutTime_Allrad" 0;
BA_DEF_DEF_  "GenSigTimeoutMsg_Lenkhilfe_ZF_2" 0;
BA_DEF_DEF_  "GenSigTimeoutTime_Lenkhilfe_ZF_2" 0;
BA_DEF_DEF_  "GenSigTimeoutMsg_Teves_MK60_ESP" 0;
BA_DEF_DEF_  "GenSigTimeoutTime_Teves_MK60_ESP" 0;
BA_DEF_DEF_  "GenSigTimeoutMsg_LWS" 0;
BA_DEF_DEF_  "GenSigTimeoutTime_LWS" 0;
BA_DEF_DEF_  "GenSigTimeoutMsg_LWR" 0;
BA_DEF_DEF_  "GenSigTimeoutTime_LWR" 0;
BA_DEF_DEF_  "GenSigTimeoutMsg_Teves_MK70_MAB" 0;
BA_DEF_DEF_  "GenSigTimeoutTime_Teves_MK70_MAB" 0;
BA_DEF_DEF_  "GenSigTimeoutMsg_Waehlhebel" 0;
BA_DEF_DEF_  "GenSigTimeoutTime_Waehlhebel" 0;
BA_DEF_DEF_  "GenSigTimeoutMsg_EPB" 0;
BA_DEF_DEF_  "GenSigTimeoutTime_EPB" 0;
BA_DEF_DEF_  "GenSigTimeoutMsg_TRW_ESP" 0;
BA_DEF_DEF_  "GenSigTimeoutTime_TRW_ESP" 0;
BA_DEF_DEF_  "GenSigTimeoutMsg_ACC_Radar" 0;
BA_DEF_DEF_  "GenSigTimeoutTime_ACC_Radar" 0;
BA_DEF_DEF_  "GenSigTimeoutMsg_AFS" 0;
BA_DEF_DEF_  "GenSigTimeoutTime_AFS" 0;
BA_DEF_DEF_  "GenSigTimeoutMsg_Magne_Ride" 0;
BA_DEF_DEF_  "GenSigTimeoutTime_Magne_Ride" 0;
BA_DEF_DEF_  "GenSigTimeoutMsg_RKA_Plus" 0;
BA_DEF_DEF_  "GenSigTimeoutTime_RKA_Plus" 0;
BA_DEF_DEF_  "GenSigTimeoutMsg_Selespeed" 0;
BA_DEF_DEF_  "GenSigTimeoutTime_Selespeed" 0;
BA_DEF_DEF_  "GenSigTimeoutMsg_Waehlhebel_Sel" 0;
BA_DEF_DEF_  "GenSigTimeoutTime_Waehlhebel_Sel" 0;
BA_DEF_DEF_  "GenSigTimeoutMsg_PDC_PLA" 0;
BA_DEF_DEF_  "GenSigTimeoutTime_PDC_PLA" 0;
BA_DEF_DEF_  "GenSigTimeoutMsg_Lenkhilfe_APA" 0;
BA_DEF_DEF_  "GenSigTimeoutTime_Lenkhilfe_APA" 0;
BA_DEF_DEF_  "GenSigTimeoutMsg_VAQ" 0;
BA_DEF_DEF_  "GenSigTimeoutTime_VAQ" 0;
BA_DEF_DEF_  "GenSigTimeoutMsg_Daempfer" 0;
BA_DEF_DEF_  "GenSigTimeoutTime_Daempfer" 0;
BA_DEF_DEF_  "GenSigTimeoutMsg_Hybrid_BMS" 0;
BA_DEF_DEF_  "GenSigTimeoutTime_Hybrid_BMS" 0;
BA_DEF_DEF_  "GenSigTimeoutMsg_Hybrid_PWR" 0;
BA_DEF_DEF_  "GenSigTimeoutTime_Hybrid_PWR" 0;
BA_DEF_DEF_  "GenSigTimeoutMsg_Hybrid_DQ200" 0;
BA_DEF_DEF_  "GenSigTimeoutTime_Hybrid_DQ200" 0;
BA_DEF_DEF_  "GenSigTimeoutMsg_EKlimakomp" 0;
BA_DEF_DEF_  "GenSigTimeoutTime_EKlimakomp" 0;
BA_DEF_DEF_  "GenSigTimeoutMsg_SWA" 0;
BA_DEF_DEF_  "GenSigTimeoutTime_SWA" 0;
BA_DEF_DEF_  "GenSigTimeoutMsg_HCA" 0;
BA_DEF_DEF_  "GenSigTimeoutTime_HCA" 0;
BA_DEF_DEF_  "GenSigTimeoutMsg_ACC_Lidar" 0;
BA_DEF_DEF_  "GenSigTimeoutTime_ACC_Lidar" 0;
BA_DEF_DEF_  "GenSigTimeoutMsg_Lenkhilfe_ZF_3" 0;
BA_DEF_DEF_  "GenSigTimeoutTime_Lenkhilfe_ZF_3" 0;
BA_DEF_DEF_  "GenSigTimeoutMsg_FLA" 0;
BA_DEF_DEF_  "GenSigTimeoutTime_FLA" 0;
BA_DEF_DEF_  "GenSigTimeoutMsg_AG6" 0;
BA_DEF_DEF_  "GenSigTimeoutTime_AG6" 0;
BA_DEF_DEF_  "GenSigTimeoutMsg_DQ" 0;
BA_DEF_DEF_  "GenSigTimeoutTime_DQ" 0;
BA_DEF_DEF_  "GenSigTimeoutMsg_Hybrid_MSG" 0;
BA_DEF_DEF_  "GenSigTimeoutTime_Hybrid_MSG" 0;
BA_DEF_DEF_  "GenSigTimeoutMsg_Diesel" 0;
BA_DEF_DEF_  "GenSigTimeoutTime_Diesel" 0;
BA_DEF_DEF_  "GenSigTimeoutMsg_Otto" 0;
BA_DEF_DEF_  "GenSigTimeoutTime_Otto" 0;
BA_DEF_DEF_  "GenSigTimeoutMsg_Gateway_PQ35_A" 0;
BA_DEF_DEF_  "GenSigTimeoutTime_Gateway_PQ35_A" 0;
BA_DEF_DEF_  "GenSigTimeoutMsg_Gateway_PQ46_A" 0;
BA_DEF_DEF_  "GenSigTimeoutTime_Gateway_PQ46_A" 0;
BA_ "GenMsgTimeoutTime" BO_ 1472 500;
BA_ "GenMsgSendType" BO_ 1472 0;
BA_ "GenMsgCycleTime" BO_ 1472 20;
BA_ "GenMsgSendType" BO_ 537 1;
BA_ "VAGTP20_DynSetup" BO_ 537 1;
BA_ "GenMsgTimeoutTime" BO_ 1386 500;
BA_ "GenMsgSendType" BO_ 1386 0;
BA_ "GenMsgCycleTime" BO_ 1386 40;
BA_ "GenMsgSendType" BO_ 523 1;
BA_ "VAGTP20_DynSetup" BO_ 523 1;
BA_ "GenMsgTimeoutTime" BO_ 872 500;
BA_ "GenMsgSendType" BO_ 872 0;
BA_ "GenMsgCycleTime" BO_ 872 20;
BA_ "GenMsgTimeoutTime" BO_ 870 500;
BA_ "GenMsgSendType" BO_ 870 0;
BA_ "GenMsgCycleTime" BO_ 870 40;
BA_ "GenMsgSendType" BO_ 1652 1;
BA_ "GenMsgTimeoutTime" BO_ 1688 1000;
BA_ "GenMsgSendType" BO_ 1688 0;
BA_ "GenMsgCycleTime" BO_ 1688 100;
BA_ "GenMsgTimeoutTime" BO_ 1428 500;
BA_ "GenMsgSendType" BO_ 1428 0;
BA_ "GenMsgCycleTime" BO_ 1428 25;
BA_ "GenMsgSendType" BO_ 524 1;
BA_ "VAGTP20_DynSetup" BO_ 524 1;
BA_ "GenMsgTimeoutTime" BO_ 1432 1000;
BA_ "GenMsgCycleTimeFast" BO_ 1432 30;
BA_ "GenMsgSendType" BO_ 1432 0;
BA_ "GenMsgCycleTime" BO_ 1432 100;
BA_ "GenMsgSendType" BO_ 520 1;
BA_ "VAGTP20_DynSetup" BO_ 520 1;
BA_ "GenMsgTimeoutTime" BO_ 1091 5000;
BA_ "GenMsgSendType" BO_ 1091 0;
BA_ "GenMsgCycleTime" BO_ 1091 500;
BA_ "GenMsgSendType" BO_ 514 1;
BA_ "VAGTP20_DynSetup" BO_ 514 1;
BA_ "GenMsgTimeoutTime" BO_ 1344 500;
BA_ "GenMsgSendType" BO_ 1344 0;
BA_ "GenMsgCycleTime" BO_ 1344 10;
BA_ "GenMsgTimeoutTime" BO_ 1346 500;
BA_ "GenMsgSendType" BO_ 1346 0;
BA_ "GenMsgCycleTime" BO_ 1346 10;
BA_ "GenMsgTimeoutTime" BO_ 1348 1000;
BA_ "GenMsgSendType" BO_ 1348 0;
BA_ "GenMsgCycleTime" BO_ 1348 100;
BA_ "GenMsgTimeoutTime" BO_ 1088 500;
BA_ "GenMsgSendType" BO_ 1088 0;
BA_ "GenMsgCycleTime" BO_ 1088 10;
BA_ "GenSigTimeoutTime_Daempfer" SG_ 1472 EP1_Spannkraft 500;
BA_ "GenSigTimeoutMsg_Daempfer" SG_ 1472 EP1_Spannkraft 1472;
BA_ "GenSigTimeoutTime_Gateway_PQ35_A" SG_ 1472 EP1_Spannkraft 500;
BA_ "GenSigTimeoutMsg_Gateway_PQ35_A" SG_ 1472 EP1_Spannkraft 1472;
BA_ "GenSigTimeoutTime_ACC_Radar" SG_ 1472 EP1_Spannkraft 500;
BA_ "GenSigTimeoutMsg_ACC_Radar" SG_ 1472 EP1_Spannkraft 1472;
BA_ "GenSigTimeoutTime_Otto" SG_ 1472 EP1_Spannkraft 500;
BA_ "GenSigTimeoutMsg_Otto" SG_ 1472 EP1_Spannkraft 1472;
BA_ "GenSigTimeoutTime_Diesel" SG_ 1472 EP1_Spannkraft 500;
BA_ "GenSigTimeoutMsg_Diesel" SG_ 1472 EP1_Spannkraft 1472;
BA_ "GenSigTimeoutTime_Gateway_PQ46_A" SG_ 1472 EP1_Spannkraft 500;
BA_ "GenSigTimeoutMsg_Gateway_PQ46_A" SG_ 1472 EP1_Spannkraft 1472;
BA_ "GenSigSendType" SG_ 1472 EP1_Spannkraft 0;
BA_ "INIT" SG_ 1472 EP1_Spannkraft "alt";
BA_ "GenSigTimeoutTime_PDC_PLA" SG_ 1472 EP1_Sta_EPB 500;
BA_ "GenSigTimeoutMsg_PDC_PLA" SG_ 1472 EP1_Sta_EPB 1472;
BA_ "GenSigTimeoutTime_Daempfer" SG_ 1472 EP1_Sta_EPB 500;
BA_ "GenSigTimeoutMsg_Daempfer" SG_ 1472 EP1_Sta_EPB 1472;
BA_ "GenSigTimeoutTime_Gateway_PQ35_A" SG_ 1472 EP1_Sta_EPB 500;
BA_ "GenSigTimeoutMsg_Gateway_PQ35_A" SG_ 1472 EP1_Sta_EPB 1472;
BA_ "GenSigTimeoutTime_ACC_Radar" SG_ 1472 EP1_Sta_EPB 500;
BA_ "GenSigTimeoutMsg_ACC_Radar" SG_ 1472 EP1_Sta_EPB 1472;
BA_ "GenSigTimeoutTime_Otto" SG_ 1472 EP1_Sta_EPB 500;
BA_ "GenSigTimeoutMsg_Otto" SG_ 1472 EP1_Sta_EPB 1472;
BA_ "GenSigTimeoutTime_Diesel" SG_ 1472 EP1_Sta_EPB 500;
BA_ "GenSigTimeoutMsg_Diesel" SG_ 1472 EP1_Sta_EPB 1472;
BA_ "GenSigTimeoutTime_Gateway_PQ46_A" SG_ 1472 EP1_Sta_EPB 500;
BA_ "GenSigTimeoutMsg_Gateway_PQ46_A" SG_ 1472 EP1_Sta_EPB 1472;
BA_ "GenSigSendType" SG_ 1472 EP1_Sta_EPB 0;
BA_ "INIT" SG_ 1472 EP1_Sta_EPB "alt";
BA_ "GenSigTimeoutTime_PDC_PLA" SG_ 1472 EP1_Fehler_Sta 500;
BA_ "GenSigTimeoutMsg_PDC_PLA" SG_ 1472 EP1_Fehler_Sta 1472;
BA_ "GenSigTimeoutTime_Daempfer" SG_ 1472 EP1_Fehler_Sta 500;
BA_ "GenSigTimeoutMsg_Daempfer" SG_ 1472 EP1_Fehler_Sta 1472;
BA_ "GenSigTimeoutTime_Gateway_PQ35_A" SG_ 1472 EP1_Fehler_Sta 500;
BA_ "GenSigTimeoutMsg_Gateway_PQ35_A" SG_ 1472 EP1_Fehler_Sta 1472;
BA_ "GenSigTimeoutTime_ACC_Radar" SG_ 1472 EP1_Fehler_Sta 500;
BA_ "GenSigTimeoutMsg_ACC_Radar" SG_ 1472 EP1_Fehler_Sta 1472;
BA_ "GenSigTimeoutTime_Otto" SG_ 1472 EP1_Fehler_Sta 500;
BA_ "GenSigTimeoutMsg_Otto" SG_ 1472 EP1_Fehler_Sta 1472;
BA_ "GenSigTimeoutTime_Diesel" SG_ 1472 EP1_Fehler_Sta 500;
BA_ "GenSigTimeoutMsg_Diesel" SG_ 1472 EP1_Fehler_Sta 1472;
BA_ "GenSigTimeoutTime_Gateway_PQ46_A" SG_ 1472 EP1_Fehler_Sta 500;
BA_ "GenSigTimeoutMsg_Gateway_PQ46_A" SG_ 1472 EP1_Fehler_Sta 1472;
BA_ "GenSigSendType" SG_ 1472 EP1_Fehler_Sta 0;
BA_ "INIT" SG_ 1472 EP1_Fehler_Sta "alt";
BA_ "GenSigTimeoutTime_Daempfer" SG_ 1472 EP1_Zaehler 500;
BA_ "GenSigTimeoutMsg_Daempfer" SG_ 1472 EP1_Zaehler 1472;
BA_ "GenSigTimeoutTime_Gateway_PQ35_A" SG_ 1472 EP1_Zaehler 500;
BA_ "GenSigTimeoutMsg_Gateway_PQ35_A" SG_ 1472 EP1_Zaehler 1472;
BA_ "GenSigTimeoutTime_ACC_Radar" SG_ 1472 EP1_Zaehler 500;
BA_ "GenSigTimeoutMsg_ACC_Radar" SG_ 1472 EP1_Zaehler 1472;
BA_ "GenSigTimeoutTime_Otto" SG_ 1472 EP1_Zaehler 500;
BA_ "GenSigTimeoutMsg_Otto" SG_ 1472 EP1_Zaehler 1472;
BA_ "GenSigTimeoutTime_Diesel" SG_ 1472 EP1_Zaehler 500;
BA_ "GenSigTimeoutMsg_Diesel" SG_ 1472 EP1_Zaehler 1472;
BA_ "GenSigTimeoutTime_Gateway_PQ46_A" SG_ 1472 EP1_Zaehler 500;
BA_ "GenSigTimeoutMsg_Gateway_PQ46_A" SG_ 1472 EP1_Zaehler 1472;
BA_ "GenSigSendType" SG_ 1472 EP1_Zaehler 0;
BA_ "GenSigTimeoutTime_Daempfer" SG_ 1472 EP1_Schalterinfo 500;
BA_ "GenSigTimeoutMsg_Daempfer" SG_ 1472 EP1_Schalterinfo 1472;
BA_ "GenSigTimeoutTime_Gateway_PQ35_A" SG_ 1472 EP1_Schalterinfo 500;
BA_ "GenSigTimeoutMsg_Gateway_PQ35_A" SG_ 1472 EP1_Schalterinfo 1472;
BA_ "GenSigTimeoutTime_ACC_Radar" SG_ 1472 EP1_Schalterinfo 500;
BA_ "GenSigTimeoutMsg_ACC_Radar" SG_ 1472 EP1_Schalterinfo 1472;
BA_ "GenSigTimeoutTime_Otto" SG_ 1472 EP1_Schalterinfo 500;
BA_ "GenSigTimeoutMsg_Otto" SG_ 1472 EP1_Schalterinfo 1472;
BA_ "GenSigTimeoutTime_Diesel" SG_ 1472 EP1_Schalterinfo 500;
BA_ "GenSigTimeoutMsg_Diesel" SG_ 1472 EP1_Schalterinfo 1472;
BA_ "GenSigTimeoutTime_Gateway_PQ46_A" SG_ 1472 EP1_Schalterinfo 500;
BA_ "GenSigTimeoutMsg_Gateway_PQ46_A" SG_ 1472 EP1_Schalterinfo 1472;
BA_ "GenSigSendType" SG_ 1472 EP1_Schalterinfo 0;
BA_ "INIT" SG_ 1472 EP1_Schalterinfo "0/3";
BA_ "GenSigTimeoutTime_Daempfer" SG_ 1472 EP1_Sta_Schalter 500;
BA_ "GenSigTimeoutMsg_Daempfer" SG_ 1472 EP1_Sta_Schalter 1472;
BA_ "GenSigTimeoutTime_Gateway_PQ35_A" SG_ 1472 EP1_Sta_Schalter 500;
BA_ "GenSigTimeoutMsg_Gateway_PQ35_A" SG_ 1472 EP1_Sta_Schalter 1472;
BA_ "GenSigTimeoutTime_ACC_Radar" SG_ 1472 EP1_Sta_Schalter 500;
BA_ "GenSigTimeoutMsg_ACC_Radar" SG_ 1472 EP1_Sta_Schalter 1472;
BA_ "GenSigTimeoutTime_Otto" SG_ 1472 EP1_Sta_Schalter 500;
BA_ "GenSigTimeoutMsg_Otto" SG_ 1472 EP1_Sta_Schalter 1472;
BA_ "GenSigTimeoutTime_Diesel" SG_ 1472 EP1_Sta_Schalter 500;
BA_ "GenSigTimeoutMsg_Diesel" SG_ 1472 EP1_Sta_Schalter 1472;
BA_ "GenSigTimeoutTime_Gateway_PQ46_A" SG_ 1472 EP1_Sta_Schalter 500;
BA_ "GenSigTimeoutMsg_Gateway_PQ46_A" SG_ 1472 EP1_Sta_Schalter 1472;
BA_ "GenSigSendType" SG_ 1472 EP1_Sta_Schalter 0;
BA_ "INIT" SG_ 1472 EP1_Sta_Schalter "alt";
BA_ "GenSigTimeoutTime_Daempfer" SG_ 1472 EP1_Sta_NWS 500;
BA_ "GenSigTimeoutMsg_Daempfer" SG_ 1472 EP1_Sta_NWS 1472;
BA_ "GenSigTimeoutTime_Gateway_PQ35_A" SG_ 1472 EP1_Sta_NWS 500;
BA_ "GenSigTimeoutMsg_Gateway_PQ35_A" SG_ 1472 EP1_Sta_NWS 1472;
BA_ "GenSigTimeoutTime_ACC_Radar" SG_ 1472 EP1_Sta_NWS 500;
BA_ "GenSigTimeoutMsg_ACC_Radar" SG_ 1472 EP1_Sta_NWS 1472;
BA_ "GenSigTimeoutTime_Otto" SG_ 1472 EP1_Sta_NWS 500;
BA_ "GenSigTimeoutMsg_Otto" SG_ 1472 EP1_Sta_NWS 1472;
BA_ "GenSigTimeoutTime_Diesel" SG_ 1472 EP1_Sta_NWS 500;
BA_ "GenSigTimeoutMsg_Diesel" SG_ 1472 EP1_Sta_NWS 1472;
BA_ "GenSigTimeoutTime_Gateway_PQ46_A" SG_ 1472 EP1_Sta_NWS 500;
BA_ "GenSigTimeoutMsg_Gateway_PQ46_A" SG_ 1472 EP1_Sta_NWS 1472;
BA_ "GenSigSendType" SG_ 1472 EP1_Sta_NWS 0;
BA_ "INIT" SG_ 1472 EP1_Sta_NWS "alt";
BA_ "GenSigTimeoutTime_Daempfer" SG_ 1472 EP1_Fkt_Lampe 500;
BA_ "GenSigTimeoutMsg_Daempfer" SG_ 1472 EP1_Fkt_Lampe 1472;
BA_ "GenSigTimeoutTime_Gateway_PQ35_A" SG_ 1472 EP1_Fkt_Lampe 500;
BA_ "GenSigTimeoutMsg_Gateway_PQ35_A" SG_ 1472 EP1_Fkt_Lampe 1472;
BA_ "GenSigTimeoutTime_ACC_Radar" SG_ 1472 EP1_Fkt_Lampe 500;
BA_ "GenSigTimeoutMsg_ACC_Radar" SG_ 1472 EP1_Fkt_Lampe 1472;
BA_ "GenSigTimeoutTime_Otto" SG_ 1472 EP1_Fkt_Lampe 500;
BA_ "GenSigTimeoutMsg_Otto" SG_ 1472 EP1_Fkt_Lampe 1472;
BA_ "GenSigTimeoutTime_Diesel" SG_ 1472 EP1_Fkt_Lampe 500;
BA_ "GenSigTimeoutMsg_Diesel" SG_ 1472 EP1_Fkt_Lampe 1472;
BA_ "GenSigTimeoutTime_Gateway_PQ46_A" SG_ 1472 EP1_Fkt_Lampe 500;
BA_ "GenSigTimeoutMsg_Gateway_PQ46_A" SG_ 1472 EP1_Fkt_Lampe 1472;
BA_ "GenSigSendType" SG_ 1472 EP1_Fkt_Lampe 0;
BA_ "GenSigTimeoutTime_Daempfer" SG_ 1472 EP1_Verzoegerung 500;
BA_ "GenSigTimeoutMsg_Daempfer" SG_ 1472 EP1_Verzoegerung 1472;
BA_ "GenSigTimeoutTime_Gateway_PQ35_A" SG_ 1472 EP1_Verzoegerung 500;
BA_ "GenSigTimeoutMsg_Gateway_PQ35_A" SG_ 1472 EP1_Verzoegerung 1472;
BA_ "GenSigTimeoutTime_ACC_Radar" SG_ 1472 EP1_Verzoegerung 500;
BA_ "GenSigTimeoutMsg_ACC_Radar" SG_ 1472 EP1_Verzoegerung 1472;
BA_ "GenSigTimeoutTime_Otto" SG_ 1472 EP1_Verzoegerung 500;
BA_ "GenSigTimeoutMsg_Otto" SG_ 1472 EP1_Verzoegerung 1472;
BA_ "GenSigTimeoutTime_Diesel" SG_ 1472 EP1_Verzoegerung 500;
BA_ "GenSigTimeoutMsg_Diesel" SG_ 1472 EP1_Verzoegerung 1472;
BA_ "GenSigTimeoutTime_Gateway_PQ46_A" SG_ 1472 EP1_Verzoegerung 500;
BA_ "GenSigTimeoutMsg_Gateway_PQ46_A" SG_ 1472 EP1_Verzoegerung 1472;
BA_ "GenSigSendType" SG_ 1472 EP1_Verzoegerung 0;
BA_ "GenSigTimeoutTime_Daempfer" SG_ 1472 EP1_Neig_winkel 500;
BA_ "GenSigTimeoutMsg_Daempfer" SG_ 1472 EP1_Neig_winkel 1472;
BA_ "GenSigTimeoutTime_Gateway_PQ35_A" SG_ 1472 EP1_Neig_winkel 500;
BA_ "GenSigTimeoutMsg_Gateway_PQ35_A" SG_ 1472 EP1_Neig_winkel 1472;
BA_ "GenSigTimeoutTime_ACC_Radar" SG_ 1472 EP1_Neig_winkel 500;
BA_ "GenSigTimeoutMsg_ACC_Radar" SG_ 1472 EP1_Neig_winkel 1472;
BA_ "GenSigTimeoutTime_Otto" SG_ 1472 EP1_Neig_winkel 500;
BA_ "GenSigTimeoutMsg_Otto" SG_ 1472 EP1_Neig_winkel 1472;
BA_ "GenSigTimeoutTime_Diesel" SG_ 1472 EP1_Neig_winkel 500;
BA_ "GenSigTimeoutMsg_Diesel" SG_ 1472 EP1_Neig_winkel 1472;
BA_ "GenSigTimeoutTime_Gateway_PQ46_A" SG_ 1472 EP1_Neig_winkel 500;
BA_ "GenSigTimeoutMsg_Gateway_PQ46_A" SG_ 1472 EP1_Neig_winkel 1472;
BA_ "GenSigSendType" SG_ 1472 EP1_Neig_winkel 0;
BA_ "GenSigTimeoutTime_Daempfer" SG_ 1472 EP1_Fehler_gelb 500;
BA_ "GenSigTimeoutMsg_Daempfer" SG_ 1472 EP1_Fehler_gelb 1472;
BA_ "GenSigTimeoutTime_Gateway_PQ35_A" SG_ 1472 EP1_Fehler_gelb 500;
BA_ "GenSigTimeoutMsg_Gateway_PQ35_A" SG_ 1472 EP1_Fehler_gelb 1472;
BA_ "GenSigTimeoutTime_ACC_Radar" SG_ 1472 EP1_Fehler_gelb 500;
BA_ "GenSigTimeoutMsg_ACC_Radar" SG_ 1472 EP1_Fehler_gelb 1472;
BA_ "GenSigTimeoutTime_Otto" SG_ 1472 EP1_Fehler_gelb 500;
BA_ "GenSigTimeoutMsg_Otto" SG_ 1472 EP1_Fehler_gelb 1472;
BA_ "GenSigTimeoutTime_Diesel" SG_ 1472 EP1_Fehler_gelb 500;
BA_ "GenSigTimeoutMsg_Diesel" SG_ 1472 EP1_Fehler_gelb 1472;
BA_ "GenSigTimeoutTime_Gateway_PQ46_A" SG_ 1472 EP1_Fehler_gelb 500;
BA_ "GenSigTimeoutMsg_Gateway_PQ46_A" SG_ 1472 EP1_Fehler_gelb 1472;
BA_ "GenSigSendType" SG_ 1472 EP1_Fehler_gelb 0;
BA_ "GenSigTimeoutTime_Daempfer" SG_ 1472 EP1_Warnton 500;
BA_ "GenSigTimeoutMsg_Daempfer" SG_ 1472 EP1_Warnton 1472;
BA_ "GenSigTimeoutTime_Gateway_PQ35_A" SG_ 1472 EP1_Warnton 500;
BA_ "GenSigTimeoutMsg_Gateway_PQ35_A" SG_ 1472 EP1_Warnton 1472;
BA_ "GenSigTimeoutTime_ACC_Radar" SG_ 1472 EP1_Warnton 500;
BA_ "GenSigTimeoutMsg_ACC_Radar" SG_ 1472 EP1_Warnton 1472;
BA_ "GenSigTimeoutTime_Otto" SG_ 1472 EP1_Warnton 500;
BA_ "GenSigTimeoutMsg_Otto" SG_ 1472 EP1_Warnton 1472;
BA_ "GenSigTimeoutTime_Diesel" SG_ 1472 EP1_Warnton 500;
BA_ "GenSigTimeoutMsg_Diesel" SG_ 1472 EP1_Warnton 1472;
BA_ "GenSigTimeoutTime_Gateway_PQ46_A" SG_ 1472 EP1_Warnton 500;
BA_ "GenSigTimeoutMsg_Gateway_PQ46_A" SG_ 1472 EP1_Warnton 1472;
BA_ "GenSigSendType" SG_ 1472 EP1_Warnton 0;
BA_ "GenSigTimeoutTime_ACC_Radar" SG_ 1472 EP1_Fehler_BKL 500;
BA_ "GenSigTimeoutMsg_ACC_Radar" SG_ 1472 EP1_Fehler_BKL 1472;
BA_ "GenSigTimeoutTime_Daempfer" SG_ 1472 EP1_Fehler_BKL 500;
BA_ "GenSigTimeoutMsg_Daempfer" SG_ 1472 EP1_Fehler_BKL 1472;
BA_ "GenSigTimeoutTime_Diesel" SG_ 1472 EP1_Fehler_BKL 500;
BA_ "GenSigTimeoutMsg_Diesel" SG_ 1472 EP1_Fehler_BKL 1472;
BA_ "GenSigTimeoutTime_Otto" SG_ 1472 EP1_Fehler_BKL 500;
BA_ "GenSigTimeoutMsg_Otto" SG_ 1472 EP1_Fehler_BKL 1472;
BA_ "GenSigTimeoutTime_Gateway_PQ35_A" SG_ 1472 EP1_Fehler_BKL 500;
BA_ "GenSigTimeoutMsg_Gateway_PQ35_A" SG_ 1472 EP1_Fehler_BKL 1472;
BA_ "GenSigTimeoutTime_Gateway_PQ46_A" SG_ 1472 EP1_Fehler_BKL 500;
BA_ "GenSigTimeoutMsg_Gateway_PQ46_A" SG_ 1472 EP1_Fehler_BKL 1472;
BA_ "GenSigSendType" SG_ 1472 EP1_Fehler_BKL 0;
BA_ "GenSigTimeoutTime_Daempfer" SG_ 1472 EP1_Fehlereintr 500;
BA_ "GenSigTimeoutMsg_Daempfer" SG_ 1472 EP1_Fehlereintr 1472;
BA_ "GenSigTimeoutTime_Gateway_PQ35_A" SG_ 1472 EP1_Fehlereintr 500;
BA_ "GenSigTimeoutMsg_Gateway_PQ35_A" SG_ 1472 EP1_Fehlereintr 1472;
BA_ "GenSigTimeoutTime_ACC_Radar" SG_ 1472 EP1_Fehlereintr 500;
BA_ "GenSigTimeoutMsg_ACC_Radar" SG_ 1472 EP1_Fehlereintr 1472;
BA_ "GenSigTimeoutTime_Otto" SG_ 1472 EP1_Fehlereintr 500;
BA_ "GenSigTimeoutMsg_Otto" SG_ 1472 EP1_Fehlereintr 1472;
BA_ "GenSigTimeoutTime_Diesel" SG_ 1472 EP1_Fehlereintr 500;
BA_ "GenSigTimeoutMsg_Diesel" SG_ 1472 EP1_Fehlereintr 1472;
BA_ "GenSigTimeoutTime_Gateway_PQ46_A" SG_ 1472 EP1_Fehlereintr 500;
BA_ "GenSigTimeoutMsg_Gateway_PQ46_A" SG_ 1472 EP1_Fehlereintr 1472;
BA_ "GenSigSendType" SG_ 1472 EP1_Fehlereintr 0;
BA_ "GenSigTimeoutTime_Daempfer" SG_ 1472 EP1__Text 500;
BA_ "GenSigTimeoutMsg_Daempfer" SG_ 1472 EP1__Text 1472;
BA_ "GenSigTimeoutTime_Gateway_PQ35_A" SG_ 1472 EP1__Text 500;
BA_ "GenSigTimeoutMsg_Gateway_PQ35_A" SG_ 1472 EP1__Text 1472;
BA_ "GenSigTimeoutTime_ACC_Radar" SG_ 1472 EP1__Text 500;
BA_ "GenSigTimeoutMsg_ACC_Radar" SG_ 1472 EP1__Text 1472;
BA_ "GenSigTimeoutTime_Otto" SG_ 1472 EP1__Text 500;
BA_ "GenSigTimeoutMsg_Otto" SG_ 1472 EP1__Text 1472;
BA_ "GenSigTimeoutTime_Diesel" SG_ 1472 EP1__Text 500;
BA_ "GenSigTimeoutMsg_Diesel" SG_ 1472 EP1__Text 1472;
BA_ "GenSigTimeoutTime_Gateway_PQ46_A" SG_ 1472 EP1__Text 500;
BA_ "GenSigTimeoutMsg_Gateway_PQ46_A" SG_ 1472 EP1__Text 1472;
BA_ "GenSigSendType" SG_ 1472 EP1__Text 0;
BA_ "GenSigTimeoutTime_Daempfer" SG_ 1472 EP1_Freigabe_Ver 500;
BA_ "GenSigTimeoutMsg_Daempfer" SG_ 1472 EP1_Freigabe_Ver 1472;
BA_ "GenSigTimeoutTime_Gateway_PQ35_A" SG_ 1472 EP1_Freigabe_Ver 500;
BA_ "GenSigTimeoutMsg_Gateway_PQ35_A" SG_ 1472 EP1_Freigabe_Ver 1472;
BA_ "GenSigTimeoutTime_ACC_Radar" SG_ 1472 EP1_Freigabe_Ver 500;
BA_ "GenSigTimeoutMsg_ACC_Radar" SG_ 1472 EP1_Freigabe_Ver 1472;
BA_ "GenSigTimeoutTime_Otto" SG_ 1472 EP1_Freigabe_Ver 500;
BA_ "GenSigTimeoutMsg_Otto" SG_ 1472 EP1_Freigabe_Ver 1472;
BA_ "GenSigTimeoutTime_Diesel" SG_ 1472 EP1_Freigabe_Ver 500;
BA_ "GenSigTimeoutMsg_Diesel" SG_ 1472 EP1_Freigabe_Ver 1472;
BA_ "GenSigTimeoutTime_Gateway_PQ46_A" SG_ 1472 EP1_Freigabe_Ver 500;
BA_ "GenSigTimeoutMsg_Gateway_PQ46_A" SG_ 1472 EP1_Freigabe_Ver 1472;
BA_ "GenSigSendType" SG_ 1472 EP1_Freigabe_Ver 0;
BA_ "GenSigTimeoutTime_Daempfer" SG_ 1472 EP1_Checksum 500;
BA_ "GenSigTimeoutMsg_Daempfer" SG_ 1472 EP1_Checksum 1472;
BA_ "GenSigTimeoutTime_Gateway_PQ35_A" SG_ 1472 EP1_Checksum 500;
BA_ "GenSigTimeoutMsg_Gateway_PQ35_A" SG_ 1472 EP1_Checksum 1472;
BA_ "GenSigTimeoutTime_ACC_Radar" SG_ 1472 EP1_Checksum 500;
BA_ "GenSigTimeoutMsg_ACC_Radar" SG_ 1472 EP1_Checksum 1472;
BA_ "GenSigTimeoutTime_Otto" SG_ 1472 EP1_Checksum 500;
BA_ "GenSigTimeoutMsg_Otto" SG_ 1472 EP1_Checksum 1472;
BA_ "GenSigTimeoutTime_Diesel" SG_ 1472 EP1_Checksum 500;
BA_ "GenSigTimeoutMsg_Diesel" SG_ 1472 EP1_Checksum 1472;
BA_ "GenSigTimeoutTime_Gateway_PQ46_A" SG_ 1472 EP1_Checksum 500;
BA_ "GenSigTimeoutMsg_Gateway_PQ46_A" SG_ 1472 EP1_Checksum 1472;
BA_ "GenSigSendType" SG_ 1472 EP1_Checksum 0;
BA_ "INIT" SG_ 1472 EP1_Checksum "CHK";
BA_ "GenSigTimeoutTime_Gateway_PQ35_A" SG_ 1472 EP1_Auto_Schl_Oe 500;
BA_ "GenSigTimeoutMsg_Gateway_PQ35_A" SG_ 1472 EP1_Auto_Schl_Oe 1472;
BA_ "GenSigTimeoutTime_Gateway_PQ46_A" SG_ 1472 EP1_Auto_Schl_Oe 500;
BA_ "GenSigTimeoutMsg_Gateway_PQ46_A" SG_ 1472 EP1_Auto_Schl_Oe 1472;
BA_ "GenSigSendType" SG_ 1472 EP1_Auto_Schl_Oe 0;
BA_ "GenSigTimeoutTime_Daempfer" SG_ 1472 EP1_SleepInd 500;
BA_ "GenSigTimeoutMsg_Daempfer" SG_ 1472 EP1_SleepInd 1472;
BA_ "GenSigTimeoutTime_Gateway_PQ35_A" SG_ 1472 EP1_SleepInd 500;
BA_ "GenSigTimeoutMsg_Gateway_PQ35_A" SG_ 1472 EP1_SleepInd 1472;
BA_ "GenSigTimeoutTime_ACC_Radar" SG_ 1472 EP1_SleepInd 500;
BA_ "GenSigTimeoutMsg_ACC_Radar" SG_ 1472 EP1_SleepInd 1472;
BA_ "GenSigTimeoutTime_Otto" SG_ 1472 EP1_SleepInd 500;
BA_ "GenSigTimeoutMsg_Otto" SG_ 1472 EP1_SleepInd 1472;
BA_ "GenSigTimeoutTime_Diesel" SG_ 1472 EP1_SleepInd 500;
BA_ "GenSigTimeoutMsg_Diesel" SG_ 1472 EP1_SleepInd 1472;
BA_ "GenSigTimeoutTime_Gateway_PQ46_A" SG_ 1472 EP1_SleepInd 500;
BA_ "GenSigTimeoutMsg_Gateway_PQ46_A" SG_ 1472 EP1_SleepInd 1472;
BA_ "GenSigSendType" SG_ 1472 EP1_SleepInd 0;
BA_ "GenSigTimeoutTime_Daempfer" SG_ 1472 EP1_Bremslicht 500;
BA_ "GenSigTimeoutMsg_Daempfer" SG_ 1472 EP1_Bremslicht 1472;
BA_ "GenSigTimeoutTime_Gateway_PQ35_A" SG_ 1472 EP1_Bremslicht 500;
BA_ "GenSigTimeoutMsg_Gateway_PQ35_A" SG_ 1472 EP1_Bremslicht 1472;
BA_ "GenSigTimeoutTime_ACC_Radar" SG_ 1472 EP1_Bremslicht 500;
BA_ "GenSigTimeoutMsg_ACC_Radar" SG_ 1472 EP1_Bremslicht 1472;
BA_ "GenSigTimeoutTime_Otto" SG_ 1472 EP1_Bremslicht 500;
BA_ "GenSigTimeoutMsg_Otto" SG_ 1472 EP1_Bremslicht 1472;
BA_ "GenSigTimeoutTime_Diesel" SG_ 1472 EP1_Bremslicht 500;
BA_ "GenSigTimeoutMsg_Diesel" SG_ 1472 EP1_Bremslicht 1472;
BA_ "GenSigTimeoutTime_Gateway_PQ46_A" SG_ 1472 EP1_Bremslicht 500;
BA_ "GenSigTimeoutMsg_Gateway_PQ46_A" SG_ 1472 EP1_Bremslicht 1472;
BA_ "GenSigSendType" SG_ 1472 EP1_Bremslicht 0;
BA_ "GenSigTimeoutTime_Daempfer" SG_ 1472 EP1_Status_Kl_15 500;
BA_ "GenSigTimeoutMsg_Daempfer" SG_ 1472 EP1_Status_Kl_15 1472;
BA_ "GenSigTimeoutTime_Gateway_PQ35_A" SG_ 1472 EP1_Status_Kl_15 500;
BA_ "GenSigTimeoutMsg_Gateway_PQ35_A" SG_ 1472 EP1_Status_Kl_15 1472;
BA_ "GenSigTimeoutTime_ACC_Radar" SG_ 1472 EP1_Status_Kl_15 500;
BA_ "GenSigTimeoutMsg_ACC_Radar" SG_ 1472 EP1_Status_Kl_15 1472;
BA_ "GenSigTimeoutTime_Otto" SG_ 1472 EP1_Status_Kl_15 500;
BA_ "GenSigTimeoutMsg_Otto" SG_ 1472 EP1_Status_Kl_15 1472;
BA_ "GenSigTimeoutTime_Diesel" SG_ 1472 EP1_Status_Kl_15 500;
BA_ "GenSigTimeoutMsg_Diesel" SG_ 1472 EP1_Status_Kl_15 1472;
BA_ "GenSigTimeoutTime_Gateway_PQ46_A" SG_ 1472 EP1_Status_Kl_15 500;
BA_ "GenSigTimeoutMsg_Gateway_PQ46_A" SG_ 1472 EP1_Status_Kl_15 1472;
BA_ "GenSigSendType" SG_ 1472 EP1_Status_Kl_15 0;
BA_ "GenSigStartValue" SG_ 1472 EP1_Status_Kl_15 1;
BA_ "GenSigTimeoutTime_Daempfer" SG_ 1472 EP1_Warnton2 500;
BA_ "GenSigTimeoutMsg_Daempfer" SG_ 1472 EP1_Warnton2 1472;
BA_ "GenSigTimeoutTime_Gateway_PQ35_A" SG_ 1472 EP1_Warnton2 500;
BA_ "GenSigTimeoutMsg_Gateway_PQ35_A" SG_ 1472 EP1_Warnton2 1472;
BA_ "GenSigTimeoutTime_ACC_Radar" SG_ 1472 EP1_Warnton2 500;
BA_ "GenSigTimeoutMsg_ACC_Radar" SG_ 1472 EP1_Warnton2 1472;
BA_ "GenSigTimeoutTime_Otto" SG_ 1472 EP1_Warnton2 500;
BA_ "GenSigTimeoutMsg_Otto" SG_ 1472 EP1_Warnton2 1472;
BA_ "GenSigTimeoutTime_Diesel" SG_ 1472 EP1_Warnton2 500;
BA_ "GenSigTimeoutMsg_Diesel" SG_ 1472 EP1_Warnton2 1472;
BA_ "GenSigTimeoutTime_Gateway_PQ46_A" SG_ 1472 EP1_Warnton2 500;
BA_ "GenSigTimeoutMsg_Gateway_PQ46_A" SG_ 1472 EP1_Warnton2 1472;
BA_ "GenSigSendType" SG_ 1472 EP1_Warnton2 0;
BA_ "GenSigTimeoutTime_Daempfer" SG_ 1472 EP1_Lampe_AutoP 500;
BA_ "GenSigTimeoutMsg_Daempfer" SG_ 1472 EP1_Lampe_AutoP 1472;
BA_ "GenSigTimeoutTime_Gateway_PQ35_A" SG_ 1472 EP1_Lampe_AutoP 500;
BA_ "GenSigTimeoutMsg_Gateway_PQ35_A" SG_ 1472 EP1_Lampe_AutoP 1472;
BA_ "GenSigTimeoutTime_ACC_Radar" SG_ 1472 EP1_Lampe_AutoP 500;
BA_ "GenSigTimeoutMsg_ACC_Radar" SG_ 1472 EP1_Lampe_AutoP 1472;
BA_ "GenSigTimeoutTime_Otto" SG_ 1472 EP1_Lampe_AutoP 500;
BA_ "GenSigTimeoutMsg_Otto" SG_ 1472 EP1_Lampe_AutoP 1472;
BA_ "GenSigTimeoutTime_Diesel" SG_ 1472 EP1_Lampe_AutoP 500;
BA_ "GenSigTimeoutMsg_Diesel" SG_ 1472 EP1_Lampe_AutoP 1472;
BA_ "GenSigTimeoutTime_Gateway_PQ46_A" SG_ 1472 EP1_Lampe_AutoP 500;
BA_ "GenSigTimeoutMsg_Gateway_PQ46_A" SG_ 1472 EP1_Lampe_AutoP 1472;
BA_ "GenSigSendType" SG_ 1472 EP1_Lampe_AutoP 0;
BA_ "GenSigTimeoutTime_Gateway_PQ35_A" SG_ 1472 EP1_QualNeigWi 500;
BA_ "GenSigTimeoutMsg_Gateway_PQ35_A" SG_ 1472 EP1_QualNeigWi 1472;
BA_ "GenSigTimeoutTime_Gateway_PQ46_A" SG_ 1472 EP1_QualNeigWi 500;
BA_ "GenSigTimeoutMsg_Gateway_PQ46_A" SG_ 1472 EP1_QualNeigWi 1472;
BA_ "GenSigSendType" SG_ 1472 EP1_QualNeigWi 0;
BA_ "GenSigStartValue" SG_ 1472 EP1_QualNeigWi 1;
BA_ "GenSigTimeoutTime_Daempfer" SG_ 1472 EP1_AnfShLock 500;
BA_ "GenSigTimeoutMsg_Daempfer" SG_ 1472 EP1_AnfShLock 1472;
BA_ "GenSigTimeoutTime_Gateway_PQ35_A" SG_ 1472 EP1_AnfShLock 500;
BA_ "GenSigTimeoutMsg_Gateway_PQ35_A" SG_ 1472 EP1_AnfShLock 1472;
BA_ "GenSigTimeoutTime_ACC_Radar" SG_ 1472 EP1_AnfShLock 500;
BA_ "GenSigTimeoutMsg_ACC_Radar" SG_ 1472 EP1_AnfShLock 1472;
BA_ "GenSigTimeoutTime_Otto" SG_ 1472 EP1_AnfShLock 500;
BA_ "GenSigTimeoutMsg_Otto" SG_ 1472 EP1_AnfShLock 1472;
BA_ "GenSigTimeoutTime_Diesel" SG_ 1472 EP1_AnfShLock 500;
BA_ "GenSigTimeoutMsg_Diesel" SG_ 1472 EP1_AnfShLock 1472;
BA_ "GenSigTimeoutTime_Gateway_PQ46_A" SG_ 1472 EP1_AnfShLock 500;
BA_ "GenSigTimeoutMsg_Gateway_PQ46_A" SG_ 1472 EP1_AnfShLock 1472;
BA_ "GenSigSendType" SG_ 1472 EP1_AnfShLock 0;
BA_ "GenSigTimeoutTime_Daempfer" SG_ 1472 EP1_HydrHalten 500;
BA_ "GenSigTimeoutMsg_Daempfer" SG_ 1472 EP1_HydrHalten 1472;
BA_ "GenSigTimeoutTime_Gateway_PQ35_A" SG_ 1472 EP1_HydrHalten 500;
BA_ "GenSigTimeoutMsg_Gateway_PQ35_A" SG_ 1472 EP1_HydrHalten 1472;
BA_ "GenSigTimeoutTime_ACC_Radar" SG_ 1472 EP1_HydrHalten 500;
BA_ "GenSigTimeoutMsg_ACC_Radar" SG_ 1472 EP1_HydrHalten 1472;
BA_ "GenSigTimeoutTime_Otto" SG_ 1472 EP1_HydrHalten 500;
BA_ "GenSigTimeoutMsg_Otto" SG_ 1472 EP1_HydrHalten 1472;
BA_ "GenSigTimeoutTime_Diesel" SG_ 1472 EP1_HydrHalten 500;
BA_ "GenSigTimeoutMsg_Diesel" SG_ 1472 EP1_HydrHalten 1472;
BA_ "GenSigTimeoutTime_Gateway_PQ46_A" SG_ 1472 EP1_HydrHalten 500;
BA_ "GenSigTimeoutMsg_Gateway_PQ46_A" SG_ 1472 EP1_HydrHalten 1472;
BA_ "GenSigSendType" SG_ 1472 EP1_HydrHalten 0;
BA_ "GenSigTimeoutTime_Daempfer" SG_ 1472 EP1_Warnton1 500;
BA_ "GenSigTimeoutMsg_Daempfer" SG_ 1472 EP1_Warnton1 1472;
BA_ "GenSigTimeoutTime_Gateway_PQ35_A" SG_ 1472 EP1_Warnton1 500;
BA_ "GenSigTimeoutMsg_Gateway_PQ35_A" SG_ 1472 EP1_Warnton1 1472;
BA_ "GenSigTimeoutTime_ACC_Radar" SG_ 1472 EP1_Warnton1 500;
BA_ "GenSigTimeoutMsg_ACC_Radar" SG_ 1472 EP1_Warnton1 1472;
BA_ "GenSigTimeoutTime_Otto" SG_ 1472 EP1_Warnton1 500;
BA_ "GenSigTimeoutMsg_Otto" SG_ 1472 EP1_Warnton1 1472;
BA_ "GenSigTimeoutTime_Diesel" SG_ 1472 EP1_Warnton1 500;
BA_ "GenSigTimeoutMsg_Diesel" SG_ 1472 EP1_Warnton1 1472;
BA_ "GenSigTimeoutTime_Gateway_PQ46_A" SG_ 1472 EP1_Warnton1 500;
BA_ "GenSigTimeoutMsg_Gateway_PQ46_A" SG_ 1472 EP1_Warnton1 1472;
BA_ "GenSigSendType" SG_ 1472 EP1_Warnton1 0;
BA_ "GenSigTimeoutTime_Otto" SG_ 1472 EP1_KuppModBer 500;
BA_ "GenSigTimeoutMsg_Otto" SG_ 1472 EP1_KuppModBer 1472;
BA_ "GenSigTimeoutTime_Gateway_PQ35_A" SG_ 1472 EP1_KuppModBer 500;
BA_ "GenSigTimeoutMsg_Gateway_PQ35_A" SG_ 1472 EP1_KuppModBer 1472;
BA_ "GenSigTimeoutTime_Diesel" SG_ 1472 EP1_KuppModBer 500;
BA_ "GenSigTimeoutMsg_Diesel" SG_ 1472 EP1_KuppModBer 1472;
BA_ "GenSigTimeoutTime_Gateway_PQ46_A" SG_ 1472 EP1_KuppModBer 500;
BA_ "GenSigTimeoutMsg_Gateway_PQ46_A" SG_ 1472 EP1_KuppModBer 1472;
BA_ "GenSigSendType" SG_ 1472 EP1_KuppModBer 0;
BA_ "GenSigTimeoutTime_Gateway_PQ46_A" SG_ 1472 EP1_AutoHold_zul 500;
BA_ "GenSigTimeoutMsg_Gateway_PQ46_A" SG_ 1472 EP1_AutoHold_zul 1472;
BA_ "GenSigTimeoutTime_Otto" SG_ 1472 EP1_AutoHold_zul 500;
BA_ "GenSigTimeoutMsg_Otto" SG_ 1472 EP1_AutoHold_zul 1472;
BA_ "GenSigTimeoutTime_Diesel" SG_ 1472 EP1_AutoHold_zul 500;
BA_ "GenSigTimeoutMsg_Diesel" SG_ 1472 EP1_AutoHold_zul 1472;
BA_ "GenSigTimeoutTime_Gateway_PQ35_A" SG_ 1472 EP1_AutoHold_zul 500;
BA_ "GenSigTimeoutMsg_Gateway_PQ35_A" SG_ 1472 EP1_AutoHold_zul 1472;
BA_ "GenSigTimeoutTime_Daempfer" SG_ 1472 EP1_AutoHold_zul 500;
BA_ "GenSigTimeoutMsg_Daempfer" SG_ 1472 EP1_AutoHold_zul 1472;
BA_ "GenSigTimeoutTime_ACC_Radar" SG_ 1472 EP1_AutoHold_zul 500;
BA_ "GenSigTimeoutMsg_ACC_Radar" SG_ 1472 EP1_AutoHold_zul 1472;
BA_ "GenSigSendType" SG_ 1472 EP1_AutoHold_zul 0;
BA_ "INIT" SG_ 1472 EP1_AutoHold_zul "const";
BA_ "GenSigTimeoutTime_Otto" SG_ 1472 EP1_AutoHold_aktiv 500;
BA_ "GenSigTimeoutMsg_Otto" SG_ 1472 EP1_AutoHold_aktiv 1472;
BA_ "GenSigTimeoutTime_Gateway_PQ46_A" SG_ 1472 EP1_AutoHold_aktiv 500;
BA_ "GenSigTimeoutMsg_Gateway_PQ46_A" SG_ 1472 EP1_AutoHold_aktiv 1472;
BA_ "GenSigTimeoutTime_Diesel" SG_ 1472 EP1_AutoHold_aktiv 500;
BA_ "GenSigTimeoutMsg_Diesel" SG_ 1472 EP1_AutoHold_aktiv 1472;
BA_ "GenSigTimeoutTime_Gateway_PQ35_A" SG_ 1472 EP1_AutoHold_aktiv 500;
BA_ "GenSigTimeoutMsg_Gateway_PQ35_A" SG_ 1472 EP1_AutoHold_aktiv 1472;
BA_ "GenSigTimeoutTime_Daempfer" SG_ 1472 EP1_AutoHold_aktiv 500;
BA_ "GenSigTimeoutMsg_Daempfer" SG_ 1472 EP1_AutoHold_aktiv 1472;
BA_ "GenSigTimeoutTime_ACC_Radar" SG_ 1472 EP1_AutoHold_aktiv 500;
BA_ "GenSigTimeoutMsg_ACC_Radar" SG_ 1472 EP1_AutoHold_aktiv 1472;
BA_ "GenSigSendType" SG_ 1472 EP1_AutoHold_aktiv 0;
BA_ "GenSigTimeoutMsg_Gateway_PQ35_A" SG_ 537 EPB_TP_Er 537;
BA_ "GenSigTimeoutMsg_Gateway_PQ46_A" SG_ 537 EPB_TP_Er 537;
BA_ "GenSigSendType" SG_ 537 EPB_TP_Er 5;
BA_ "GenSigTimeoutTime_Gateway_PQ35_A" SG_ 1386 ACA_ID_StaACC 500;
BA_ "GenSigTimeoutMsg_Gateway_PQ35_A" SG_ 1386 ACA_ID_StaACC 1386;
BA_ "GenSigTimeoutTime_Gateway_PQ46_A" SG_ 1386 ACA_ID_StaACC 500;
BA_ "GenSigTimeoutMsg_Gateway_PQ46_A" SG_ 1386 ACA_ID_StaACC 1386;
BA_ "GenSigSendType" SG_ 1386 ACA_ID_StaACC 0;
BA_ "GenSigTimeoutTime_Gateway_PQ35_A" SG_ 1386 ACA_Fahrerhinw 500;
BA_ "GenSigTimeoutMsg_Gateway_PQ35_A" SG_ 1386 ACA_Fahrerhinw 1386;
BA_ "GenSigTimeoutTime_Gateway_PQ46_A" SG_ 1386 ACA_Fahrerhinw 500;
BA_ "GenSigTimeoutMsg_Gateway_PQ46_A" SG_ 1386 ACA_Fahrerhinw 1386;
BA_ "GenSigSendType" SG_ 1386 ACA_Fahrerhinw 0;
BA_ "GenSigTimeoutTime_AG6" SG_ 1386 ACA_V_Wunsch 500;
BA_ "GenSigTimeoutMsg_AG6" SG_ 1386 ACA_V_Wunsch 1386;
BA_ "GenSigTimeoutTime_DQ" SG_ 1386 ACA_V_Wunsch 500;
BA_ "GenSigTimeoutMsg_DQ" SG_ 1386 ACA_V_Wunsch 1386;
BA_ "GenSigTimeoutTime_Gateway_PQ35_A" SG_ 1386 ACA_V_Wunsch 500;
BA_ "GenSigTimeoutMsg_Gateway_PQ35_A" SG_ 1386 ACA_V_Wunsch 1386;
BA_ "GenSigTimeoutTime_Gateway_PQ46_A" SG_ 1386 ACA_V_Wunsch 500;
BA_ "GenSigTimeoutMsg_Gateway_PQ46_A" SG_ 1386 ACA_V_Wunsch 1386;
BA_ "GenSigSendType" SG_ 1386 ACA_V_Wunsch 0;
BA_ "GenSigTimeoutTime_Gateway_PQ35_A" SG_ 1386 ACA_PrioDisp 500;
BA_ "GenSigTimeoutMsg_Gateway_PQ35_A" SG_ 1386 ACA_PrioDisp 1386;
BA_ "GenSigTimeoutTime_Gateway_PQ46_A" SG_ 1386 ACA_PrioDisp 500;
BA_ "GenSigTimeoutMsg_Gateway_PQ46_A" SG_ 1386 ACA_PrioDisp 1386;
BA_ "GenSigSendType" SG_ 1386 ACA_PrioDisp 0;
BA_ "GenSigStartValue" SG_ 1386 ACA_PrioDisp 3;
BA_ "GenSigTimeoutTime_Gateway_PQ35_A" SG_ 1386 ACA_StaACC 500;
BA_ "GenSigTimeoutMsg_Gateway_PQ35_A" SG_ 1386 ACA_StaACC 1386;
BA_ "GenSigTimeoutTime_Gateway_PQ46_A" SG_ 1386 ACA_StaACC 500;
BA_ "GenSigTimeoutMsg_Gateway_PQ46_A" SG_ 1386 ACA_StaACC 1386;
BA_ "GenSigSendType" SG_ 1386 ACA_StaACC 0;
BA_ "GenSigTimeoutTime_Gateway_PQ35_A" SG_ 1386 ACA_AnzDisplay 500;
BA_ "GenSigTimeoutMsg_Gateway_PQ35_A" SG_ 1386 ACA_AnzDisplay 1386;
BA_ "GenSigTimeoutTime_Gateway_PQ46_A" SG_ 1386 ACA_AnzDisplay 500;
BA_ "GenSigTimeoutMsg_Gateway_PQ46_A" SG_ 1386 ACA_AnzDisplay 1386;
BA_ "GenSigSendType" SG_ 1386 ACA_AnzDisplay 0;
BA_ "GenSigTimeoutTime_Gateway_PQ35_A" SG_ 1386 ACA_Zeitluecke 500;
BA_ "GenSigTimeoutMsg_Gateway_PQ35_A" SG_ 1386 ACA_Zeitluecke 1386;
BA_ "GenSigTimeoutTime_Gateway_PQ46_A" SG_ 1386 ACA_Zeitluecke 500;
BA_ "GenSigTimeoutMsg_Gateway_PQ46_A" SG_ 1386 ACA_Zeitluecke 1386;
BA_ "GenSigSendType" SG_ 1386 ACA_Zeitluecke 0;
BA_ "GenSigStartValue" SG_ 1386 ACA_Zeitluecke 2;
BA_ "GenSigTimeoutTime_Gateway_PQ35_A" SG_ 1386 ACA_gemZeitl 500;
BA_ "GenSigTimeoutMsg_Gateway_PQ35_A" SG_ 1386 ACA_gemZeitl 1386;
BA_ "GenSigTimeoutTime_Gateway_PQ46_A" SG_ 1386 ACA_gemZeitl 500;
BA_ "GenSigTimeoutMsg_Gateway_PQ46_A" SG_ 1386 ACA_gemZeitl 1386;
BA_ "GenSigSendType" SG_ 1386 ACA_gemZeitl 0;
BA_ "GenSigTimeoutTime_Gateway_PQ35_A" SG_ 1386 ACA_kmh_mph 500;
BA_ "GenSigTimeoutMsg_Gateway_PQ35_A" SG_ 1386 ACA_kmh_mph 1386;
BA_ "GenSigTimeoutTime_Gateway_PQ46_A" SG_ 1386 ACA_kmh_mph 500;
BA_ "GenSigTimeoutMsg_Gateway_PQ46_A" SG_ 1386 ACA_kmh_mph 1386;
BA_ "GenSigSendType" SG_ 1386 ACA_kmh_mph 0;
BA_ "GenSigTimeoutTime_Gateway_PQ35_A" SG_ 1386 ACA_Akustik1 500;
BA_ "GenSigTimeoutMsg_Gateway_PQ35_A" SG_ 1386 ACA_Akustik1 1386;
BA_ "GenSigTimeoutTime_Gateway_PQ46_A" SG_ 1386 ACA_Akustik1 500;
BA_ "GenSigTimeoutMsg_Gateway_PQ46_A" SG_ 1386 ACA_Akustik1 1386;
BA_ "GenSigSendType" SG_ 1386 ACA_Akustik1 0;
BA_ "GenSigTimeoutTime_Gateway_PQ35_A" SG_ 1386 ACA_Akustik2 500;
BA_ "GenSigTimeoutMsg_Gateway_PQ35_A" SG_ 1386 ACA_Akustik2 1386;
BA_ "GenSigTimeoutTime_Gateway_PQ46_A" SG_ 1386 ACA_Akustik2 500;
BA_ "GenSigTimeoutMsg_Gateway_PQ46_A" SG_ 1386 ACA_Akustik2 1386;
BA_ "GenSigSendType" SG_ 1386 ACA_Akustik2 0;
BA_ "GenSigTimeoutTime_Gateway_PQ35_A" SG_ 1386 ACA_Checksum 500;
BA_ "GenSigTimeoutMsg_Gateway_PQ35_A" SG_ 1386 ACA_Checksum 1386;
BA_ "GenSigTimeoutTime_Gateway_PQ46_A" SG_ 1386 ACA_Checksum 500;
BA_ "GenSigTimeoutMsg_Gateway_PQ46_A" SG_ 1386 ACA_Checksum 1386;
BA_ "GenSigSendType" SG_ 1386 ACA_Checksum 0;
BA_ "INIT" SG_ 1386 ACA_Checksum "CHK";
BA_ "GenSigTimeoutTime_Gateway_PQ35_A" SG_ 1386 ACA_Codierung 500;
BA_ "GenSigTimeoutMsg_Gateway_PQ35_A" SG_ 1386 ACA_Codierung 1386;
BA_ "GenSigTimeoutTime_Gateway_PQ46_A" SG_ 1386 ACA_Codierung 500;
BA_ "GenSigTimeoutMsg_Gateway_PQ46_A" SG_ 1386 ACA_Codierung 1386;
BA_ "GenSigSendType" SG_ 1386 ACA_Codierung 0;
BA_ "INIT" SG_ 1386 ACA_Codierung "const";
BA_ "GenSigTimeoutTime_Gateway_PQ35_A" SG_ 1386 ACA_Tachokranz 500;
BA_ "GenSigTimeoutMsg_Gateway_PQ35_A" SG_ 1386 ACA_Tachokranz 1386;
BA_ "GenSigTimeoutTime_Gateway_PQ46_A" SG_ 1386 ACA_Tachokranz 500;
BA_ "GenSigTimeoutMsg_Gateway_PQ46_A" SG_ 1386 ACA_Tachokranz 1386;
BA_ "GenSigSendType" SG_ 1386 ACA_Tachokranz 0;
BA_ "GenSigTimeoutTime_Gateway_PQ35_A" SG_ 1386 ACA_ACC_Verz 500;
BA_ "GenSigTimeoutMsg_Gateway_PQ35_A" SG_ 1386 ACA_ACC_Verz 1386;
BA_ "GenSigTimeoutTime_Gateway_PQ46_A" SG_ 1386 ACA_ACC_Verz 500;
BA_ "GenSigTimeoutMsg_Gateway_PQ46_A" SG_ 1386 ACA_ACC_Verz 1386;
BA_ "GenSigSendType" SG_ 1386 ACA_ACC_Verz 0;
BA_ "GenSigTimeoutTime_Gateway_PQ35_A" SG_ 1386 ACA_res_22 500;
BA_ "GenSigTimeoutMsg_Gateway_PQ35_A" SG_ 1386 ACA_res_22 1386;
BA_ "GenSigTimeoutTime_Gateway_PQ46_A" SG_ 1386 ACA_res_22 500;
BA_ "GenSigTimeoutMsg_Gateway_PQ46_A" SG_ 1386 ACA_res_22 1386;
BA_ "GenSigSendType" SG_ 1386 ACA_res_22 0;
BA_ "GenSigTimeoutTime_Gateway_PQ35_A" SG_ 1386 ACA_Zaehler 500;
BA_ "GenSigTimeoutMsg_Gateway_PQ35_A" SG_ 1386 ACA_Zaehler 1386;
BA_ "GenSigTimeoutTime_Gateway_PQ46_A" SG_ 1386 ACA_Zaehler 500;
BA_ "GenSigTimeoutMsg_Gateway_PQ46_A" SG_ 1386 ACA_Zaehler 1386;
BA_ "GenSigSendType" SG_ 1386 ACA_Zaehler 0;
BA_ "GenSigTimeoutTime_Gateway_PQ35_A" SG_ 1386 ACA_res_37 500;
BA_ "GenSigTimeoutMsg_Gateway_PQ35_A" SG_ 1386 ACA_res_37 1386;
BA_ "GenSigTimeoutTime_Gateway_PQ46_A" SG_ 1386 ACA_res_37 500;
BA_ "GenSigTimeoutMsg_Gateway_PQ46_A" SG_ 1386 ACA_res_37 1386;
BA_ "GenSigSendType" SG_ 1386 ACA_res_37 0;
BA_ "GenSigTimeoutTime_Gateway_PQ35_A" SG_ 1386 ACA_res_45 500;
BA_ "GenSigTimeoutMsg_Gateway_PQ35_A" SG_ 1386 ACA_res_45 1386;
BA_ "GenSigTimeoutTime_Gateway_PQ46_A" SG_ 1386 ACA_res_45 500;
BA_ "GenSigTimeoutMsg_Gateway_PQ46_A" SG_ 1386 ACA_res_45 1386;
BA_ "GenSigSendType" SG_ 1386 ACA_res_45 0;
BA_ "GenSigTimeoutTime_Gateway_PQ35_A" SG_ 1386 ACA_ID_StaGRA 500;
BA_ "GenSigTimeoutMsg_Gateway_PQ35_A" SG_ 1386 ACA_ID_StaGRA 1386;
BA_ "GenSigTimeoutTime_Gateway_PQ46_A" SG_ 1386 ACA_ID_StaGRA 500;
BA_ "GenSigTimeoutMsg_Gateway_PQ46_A" SG_ 1386 ACA_ID_StaGRA 1386;
BA_ "GenSigSendType" SG_ 1386 ACA_ID_StaGRA 0;
BA_ "GenSigTimeoutTime_Gateway_PQ35_A" SG_ 1386 ACA_res_59 500;
BA_ "GenSigTimeoutMsg_Gateway_PQ35_A" SG_ 1386 ACA_res_59 1386;
BA_ "GenSigTimeoutTime_Gateway_PQ46_A" SG_ 1386 ACA_res_59 500;
BA_ "GenSigTimeoutMsg_Gateway_PQ46_A" SG_ 1386 ACA_res_59 1386;
BA_ "GenSigSendType" SG_ 1386 ACA_res_59 0;
BA_ "GenSigTimeoutTime_Gateway_PQ35_A" SG_ 1386 ACA_res_39 500;
BA_ "GenSigTimeoutMsg_Gateway_PQ35_A" SG_ 1386 ACA_res_39 1386;
BA_ "GenSigTimeoutTime_Gateway_PQ46_A" SG_ 1386 ACA_res_39 500;
BA_ "GenSigTimeoutMsg_Gateway_PQ46_A" SG_ 1386 ACA_res_39 1386;
BA_ "GenSigSendType" SG_ 1386 ACA_res_39 0;
BA_ "GenSigTimeoutTime_Gateway_PQ35_A" SG_ 1386 ACA_Aend_Zeitluecke 500;
BA_ "GenSigTimeoutMsg_Gateway_PQ35_A" SG_ 1386 ACA_Aend_Zeitluecke 1386;
BA_ "GenSigTimeoutTime_Gateway_PQ46_A" SG_ 1386 ACA_Aend_Zeitluecke 500;
BA_ "GenSigTimeoutMsg_Gateway_PQ46_A" SG_ 1386 ACA_Aend_Zeitluecke 1386;
BA_ "GenSigSendType" SG_ 1386 ACA_Aend_Zeitluecke 0;
BA_ "GenSigTimeoutTime_Gateway_PQ35_A" SG_ 1386 ACA_StaGRA 500;
BA_ "GenSigTimeoutMsg_Gateway_PQ35_A" SG_ 1386 ACA_StaGRA 1386;
BA_ "GenSigTimeoutTime_Gateway_PQ46_A" SG_ 1386 ACA_StaGRA 500;
BA_ "GenSigTimeoutMsg_Gateway_PQ46_A" SG_ 1386 ACA_StaGRA 1386;
BA_ "GenSigSendType" SG_ 1386 ACA_StaGRA 0;
BA_ "GenSigTimeoutMsg_Gateway_PQ46_A" SG_ 523 ADR_TP_Er 523;
BA_ "GenSigSendType" SG_ 523 ADR_TP_Er 5;
BA_ "GenSigTimeoutTime_DQ" SG_ 872 ACS_Schubabsch 500;
BA_ "GenSigTimeoutMsg_DQ" SG_ 872 ACS_Schubabsch 872;
BA_ "GenSigTimeoutTime_AG6" SG_ 872 ACS_Schubabsch 500;
BA_ "GenSigTimeoutMsg_AG6" SG_ 872 ACS_Schubabsch 872;
BA_ "GenSigTimeoutTime_Otto" SG_ 872 ACS_Schubabsch 500;
BA_ "GenSigTimeoutMsg_Otto" SG_ 872 ACS_Schubabsch 872;
BA_ "GenSigTimeoutTime_Diesel" SG_ 872 ACS_Schubabsch 500;
BA_ "GenSigTimeoutMsg_Diesel" SG_ 872 ACS_Schubabsch 872;
BA_ "GenSigSendType" SG_ 872 ACS_Schubabsch 0;
BA_ "GenSigTimeoutTime_AG6" SG_ 872 ACS_ADR_Schub 500;
BA_ "GenSigTimeoutMsg_AG6" SG_ 872 ACS_ADR_Schub 872;
BA_ "GenSigTimeoutTime_DQ" SG_ 872 ACS_ADR_Schub 500;
BA_ "GenSigTimeoutMsg_DQ" SG_ 872 ACS_ADR_Schub 872;
BA_ "GenSigTimeoutTime_Otto" SG_ 872 ACS_ADR_Schub 500;
BA_ "GenSigTimeoutMsg_Otto" SG_ 872 ACS_ADR_Schub 872;
BA_ "GenSigTimeoutTime_Diesel" SG_ 872 ACS_ADR_Schub 500;
BA_ "GenSigTimeoutMsg_Diesel" SG_ 872 ACS_ADR_Schub 872;
BA_ "GenSigSendType" SG_ 872 ACS_ADR_Schub 0;
BA_ "GenSigTimeoutTime_Daempfer" SG_ 872 ACS_Checksum 500;
BA_ "GenSigTimeoutMsg_Daempfer" SG_ 872 ACS_Checksum 872;
BA_ "GenSigTimeoutTime_Otto" SG_ 872 ACS_Checksum 500;
BA_ "GenSigTimeoutMsg_Otto" SG_ 872 ACS_Checksum 872;
BA_ "GenSigTimeoutTime_Diesel" SG_ 872 ACS_Checksum 500;
BA_ "GenSigTimeoutMsg_Diesel" SG_ 872 ACS_Checksum 872;
BA_ "GenSigSendType" SG_ 872 ACS_Checksum 0;
BA_ "INIT" SG_ 872 ACS_Checksum "CHK";
BA_ "GenSigTimeoutTime_DQ" SG_ 872 ACS_Sta_ADR 500;
BA_ "GenSigTimeoutMsg_DQ" SG_ 872 ACS_Sta_ADR 872;
BA_ "GenSigTimeoutTime_AG6" SG_ 872 ACS_Sta_ADR 500;
BA_ "GenSigTimeoutMsg_AG6" SG_ 872 ACS_Sta_ADR 872;
BA_ "GenSigTimeoutTime_Otto" SG_ 872 ACS_Sta_ADR 500;
BA_ "GenSigTimeoutMsg_Otto" SG_ 872 ACS_Sta_ADR 872;
BA_ "GenSigTimeoutTime_Diesel" SG_ 872 ACS_Sta_ADR 500;
BA_ "GenSigTimeoutMsg_Diesel" SG_ 872 ACS_Sta_ADR 872;
BA_ "GenSigSendType" SG_ 872 ACS_Sta_ADR 0;
BA_ "GenSigTimeoutTime_Otto" SG_ 872 ACS_StSt_Info 500;
BA_ "GenSigTimeoutMsg_Otto" SG_ 872 ACS_StSt_Info 872;
BA_ "GenSigTimeoutTime_Diesel" SG_ 872 ACS_StSt_Info 500;
BA_ "GenSigTimeoutMsg_Diesel" SG_ 872 ACS_StSt_Info 872;
BA_ "GenSigSendType" SG_ 872 ACS_StSt_Info 0;
BA_ "GenSigTimeoutTime_Daempfer" SG_ 872 ACS_Zaehler 500;
BA_ "GenSigTimeoutMsg_Daempfer" SG_ 872 ACS_Zaehler 872;
BA_ "GenSigTimeoutTime_Otto" SG_ 872 ACS_Zaehler 500;
BA_ "GenSigTimeoutMsg_Otto" SG_ 872 ACS_Zaehler 872;
BA_ "GenSigTimeoutTime_Diesel" SG_ 872 ACS_Zaehler 500;
BA_ "GenSigTimeoutMsg_Diesel" SG_ 872 ACS_Zaehler 872;
BA_ "GenSigSendType" SG_ 872 ACS_Zaehler 0;
BA_ "GenSigTimeoutTime_DQ" SG_ 872 ACS_MomEingriff 500;
BA_ "GenSigTimeoutMsg_DQ" SG_ 872 ACS_MomEingriff 872;
BA_ "GenSigTimeoutTime_AG6" SG_ 872 ACS_MomEingriff 500;
BA_ "GenSigTimeoutMsg_AG6" SG_ 872 ACS_MomEingriff 872;
BA_ "GenSigTimeoutTime_Otto" SG_ 872 ACS_MomEingriff 500;
BA_ "GenSigTimeoutMsg_Otto" SG_ 872 ACS_MomEingriff 872;
BA_ "GenSigTimeoutTime_Diesel" SG_ 872 ACS_MomEingriff 500;
BA_ "GenSigTimeoutMsg_Diesel" SG_ 872 ACS_MomEingriff 872;
BA_ "GenSigSendType" SG_ 872 ACS_MomEingriff 0;
BA_ "GenSigTimeoutTime_DQ" SG_ 872 ACS_FreigSollB 500;
BA_ "GenSigTimeoutMsg_DQ" SG_ 872 ACS_FreigSollB 872;
BA_ "GenSigTimeoutTime_AG6" SG_ 872 ACS_FreigSollB 500;
BA_ "GenSigTimeoutMsg_AG6" SG_ 872 ACS_FreigSollB 872;
BA_ "GenSigTimeoutTime_Daempfer" SG_ 872 ACS_FreigSollB 500;
BA_ "GenSigTimeoutMsg_Daempfer" SG_ 872 ACS_FreigSollB 872;
BA_ "GenSigTimeoutTime_Otto" SG_ 872 ACS_FreigSollB 500;
BA_ "GenSigTimeoutMsg_Otto" SG_ 872 ACS_FreigSollB 872;
BA_ "GenSigTimeoutTime_Diesel" SG_ 872 ACS_FreigSollB 500;
BA_ "GenSigTimeoutMsg_Diesel" SG_ 872 ACS_FreigSollB 872;
BA_ "GenSigSendType" SG_ 872 ACS_FreigSollB 0;
BA_ "GenSigTimeoutTime_AG6" SG_ 872 ACS_Sollbeschl 500;
BA_ "GenSigTimeoutMsg_AG6" SG_ 872 ACS_Sollbeschl 872;
BA_ "GenSigTimeoutTime_DQ" SG_ 872 ACS_Sollbeschl 500;
BA_ "GenSigTimeoutMsg_DQ" SG_ 872 ACS_Sollbeschl 872;
BA_ "GenSigTimeoutTime_Daempfer" SG_ 872 ACS_Sollbeschl 500;
BA_ "GenSigTimeoutMsg_Daempfer" SG_ 872 ACS_Sollbeschl 872;
BA_ "GenSigTimeoutTime_Otto" SG_ 872 ACS_Sollbeschl 500;
BA_ "GenSigTimeoutMsg_Otto" SG_ 872 ACS_Sollbeschl 872;
BA_ "GenSigTimeoutTime_Diesel" SG_ 872 ACS_Sollbeschl 500;
BA_ "GenSigTimeoutMsg_Diesel" SG_ 872 ACS_Sollbeschl 872;
BA_ "GenSigSendType" SG_ 872 ACS_Sollbeschl 0;
BA_ "GenSigStartValue" SG_ 872 ACS_Sollbeschl 2046;
BA_ "GenSigTimeoutTime_Diesel" SG_ 872 ACS_res_21 500;
BA_ "GenSigTimeoutMsg_Diesel" SG_ 872 ACS_res_21 872;
BA_ "GenSigTimeoutTime_Otto" SG_ 872 ACS_res_21 500;
BA_ "GenSigTimeoutMsg_Otto" SG_ 872 ACS_res_21 872;
BA_ "GenSigSendType" SG_ 872 ACS_res_21 0;
BA_ "GenSigTimeoutTime_Diesel" SG_ 872 ACS_res_37 500;
BA_ "GenSigTimeoutMsg_Diesel" SG_ 872 ACS_res_37 872;
BA_ "GenSigTimeoutTime_Otto" SG_ 872 ACS_res_37 500;
BA_ "GenSigTimeoutMsg_Otto" SG_ 872 ACS_res_37 872;
BA_ "GenSigSendType" SG_ 872 ACS_res_37 0;
BA_ "GenSigTimeoutTime_Diesel" SG_ 872 ACS_res_35 500;
BA_ "GenSigTimeoutMsg_Diesel" SG_ 872 ACS_res_35 872;
BA_ "GenSigTimeoutTime_Otto" SG_ 872 ACS_res_35 500;
BA_ "GenSigTimeoutMsg_Otto" SG_ 872 ACS_res_35 872;
BA_ "GenSigSendType" SG_ 872 ACS_res_35 0;
BA_ "GenSigTimeoutTime_AG6" SG_ 872 ACS_Typ_ACC 500;
BA_ "GenSigTimeoutMsg_AG6" SG_ 872 ACS_Typ_ACC 872;
BA_ "GenSigTimeoutTime_DQ" SG_ 872 ACS_Typ_ACC 500;
BA_ "GenSigTimeoutMsg_DQ" SG_ 872 ACS_Typ_ACC 872;
BA_ "GenSigTimeoutTime_Otto" SG_ 872 ACS_Typ_ACC 500;
BA_ "GenSigTimeoutMsg_Otto" SG_ 872 ACS_Typ_ACC 872;
BA_ "GenSigTimeoutTime_Diesel" SG_ 872 ACS_Typ_ACC 500;
BA_ "GenSigTimeoutMsg_Diesel" SG_ 872 ACS_Typ_ACC 872;
BA_ "GenSigSendType" SG_ 872 ACS_Typ_ACC 0;
BA_ "GenSigTimeoutTime_Otto" SG_ 872 ACS_Anhaltewunsch 500;
BA_ "GenSigTimeoutMsg_Otto" SG_ 872 ACS_Anhaltewunsch 872;
BA_ "GenSigTimeoutTime_Diesel" SG_ 872 ACS_Anhaltewunsch 500;
BA_ "GenSigTimeoutMsg_Diesel" SG_ 872 ACS_Anhaltewunsch 872;
BA_ "GenSigSendType" SG_ 872 ACS_Anhaltewunsch 0;
BA_ "GenSigTimeoutTime_Otto" SG_ 872 ACS_zul_Regelabw 500;
BA_ "GenSigTimeoutMsg_Otto" SG_ 872 ACS_zul_Regelabw 872;
BA_ "GenSigTimeoutTime_Diesel" SG_ 872 ACS_zul_Regelabw 500;
BA_ "GenSigTimeoutMsg_Diesel" SG_ 872 ACS_zul_Regelabw 872;
BA_ "GenSigSendType" SG_ 872 ACS_zul_Regelabw 0;
BA_ "GenSigStartValue" SG_ 872 ACS_zul_Regelabw 254;
BA_ "GenSigTimeoutTime_Diesel" SG_ 872 ACS_res_36 500;
BA_ "GenSigTimeoutMsg_Diesel" SG_ 872 ACS_res_36 872;
BA_ "GenSigTimeoutTime_Otto" SG_ 872 ACS_res_36 500;
BA_ "GenSigTimeoutMsg_Otto" SG_ 872 ACS_res_36 872;
BA_ "GenSigSendType" SG_ 872 ACS_res_36 0;
BA_ "GenSigTimeoutTime_Otto" SG_ 872 ACS_max_AendGrad 500;
BA_ "GenSigTimeoutMsg_Otto" SG_ 872 ACS_max_AendGrad 872;
BA_ "GenSigTimeoutTime_Diesel" SG_ 872 ACS_max_AendGrad 500;
BA_ "GenSigTimeoutMsg_Diesel" SG_ 872 ACS_max_AendGrad 872;
BA_ "GenSigSendType" SG_ 872 ACS_max_AendGrad 0;
BA_ "GenSigStartValue" SG_ 872 ACS_max_AendGrad 255;
BA_ "GenSigTimeoutTime_Diesel" SG_ 872 ACS_res_56 500;
BA_ "GenSigTimeoutMsg_Diesel" SG_ 872 ACS_res_56 872;
BA_ "GenSigTimeoutTime_Otto" SG_ 872 ACS_res_56 500;
BA_ "GenSigTimeoutMsg_Otto" SG_ 872 ACS_res_56 872;
BA_ "GenSigSendType" SG_ 872 ACS_res_56 0;
BA_ "GenSigTimeoutTime_Diesel" SG_ 872 ACS_res_57 500;
BA_ "GenSigTimeoutMsg_Diesel" SG_ 872 ACS_res_57 872;
BA_ "GenSigTimeoutTime_Otto" SG_ 872 ACS_res_57 500;
BA_ "GenSigTimeoutMsg_Otto" SG_ 872 ACS_res_57 872;
BA_ "GenSigSendType" SG_ 872 ACS_res_57 0;
BA_ "GenSigTimeoutTime_Gateway_PQ35_A" SG_ 872 ACS_Fehler 500;
BA_ "GenSigTimeoutMsg_Gateway_PQ35_A" SG_ 872 ACS_Fehler 872;
BA_ "GenSigTimeoutTime_Otto" SG_ 872 ACS_Fehler 500;
BA_ "GenSigTimeoutMsg_Otto" SG_ 872 ACS_Fehler 872;
BA_ "GenSigTimeoutTime_Diesel" SG_ 872 ACS_Fehler 500;
BA_ "GenSigTimeoutMsg_Diesel" SG_ 872 ACS_Fehler 872;
BA_ "GenSigTimeoutTime_Gateway_PQ46_A" SG_ 872 ACS_Fehler 500;
BA_ "GenSigTimeoutMsg_Gateway_PQ46_A" SG_ 872 ACS_Fehler 872;
BA_ "GenSigSendType" SG_ 872 ACS_Fehler 0;
BA_ "GenSigTimeoutTime_Diesel" SG_ 872 ACS_res_58 500;
BA_ "GenSigTimeoutMsg_Diesel" SG_ 872 ACS_res_58 872;
BA_ "GenSigTimeoutTime_Otto" SG_ 872 ACS_res_58 500;
BA_ "GenSigTimeoutMsg_Otto" SG_ 872 ACS_res_58 872;
BA_ "GenSigSendType" SG_ 872 ACS_res_58 0;
BA_ "GenSigTimeoutTime_Diesel" SG_ 872 ACS_res_59 500;
BA_ "GenSigTimeoutMsg_Diesel" SG_ 872 ACS_res_59 872;
BA_ "GenSigTimeoutTime_Otto" SG_ 872 ACS_res_59 500;
BA_ "GenSigTimeoutMsg_Otto" SG_ 872 ACS_res_59 872;
BA_ "GenSigSendType" SG_ 872 ACS_res_59 0;
BA_ "GenSigTimeoutTime_Diesel" SG_ 872 ACS_res_63 500;
BA_ "GenSigTimeoutMsg_Diesel" SG_ 872 ACS_res_63 872;
BA_ "GenSigTimeoutTime_Otto" SG_ 872 ACS_res_63 500;
BA_ "GenSigTimeoutMsg_Otto" SG_ 872 ACS_res_63 872;
BA_ "GenSigSendType" SG_ 872 ACS_res_63 0;
BA_ "GenSigTimeoutTime_Diesel" SG_ 872 ACS_res_60 500;
BA_ "GenSigTimeoutMsg_Diesel" SG_ 872 ACS_res_60 872;
BA_ "GenSigTimeoutTime_Otto" SG_ 872 ACS_res_60 500;
BA_ "GenSigTimeoutMsg_Otto" SG_ 872 ACS_res_60 872;
BA_ "GenSigSendType" SG_ 872 ACS_res_60 0;
BA_ "GenSigTimeoutTime_Diesel" SG_ 872 ACS_res_62 500;
BA_ "GenSigTimeoutMsg_Diesel" SG_ 872 ACS_res_62 872;
BA_ "GenSigTimeoutTime_Otto" SG_ 872 ACS_res_62 500;
BA_ "GenSigTimeoutMsg_Otto" SG_ 872 ACS_res_62 872;
BA_ "GenSigSendType" SG_ 872 ACS_res_62 0;
BA_ "GenSigTimeoutTime_Diesel" SG_ 872 ACS_res_61 500;
BA_ "GenSigTimeoutMsg_Diesel" SG_ 872 ACS_res_61 872;
BA_ "GenSigTimeoutTime_Otto" SG_ 872 ACS_res_61 500;
BA_ "GenSigTimeoutMsg_Otto" SG_ 872 ACS_res_61 872;
BA_ "GenSigSendType" SG_ 872 ACS_res_61 0;
BA_ "GenSigTimeoutTime_Gateway_PQ35_A" SG_ 870 AWV_2_Status 500;
BA_ "GenSigTimeoutMsg_Gateway_PQ35_A" SG_ 870 AWV_2_Status 870;
BA_ "GenSigTimeoutTime_HCA" SG_ 870 AWV_2_Status 500;
BA_ "GenSigTimeoutMsg_HCA" SG_ 870 AWV_2_Status 870;
BA_ "GenSigTimeoutTime_TRW_ESP" SG_ 870 AWV_2_Status 500;
BA_ "GenSigTimeoutMsg_TRW_ESP" SG_ 870 AWV_2_Status 870;
BA_ "GenSigTimeoutTime_Gateway_PQ46_A" SG_ 870 AWV_2_Status 500;
BA_ "GenSigTimeoutMsg_Gateway_PQ46_A" SG_ 870 AWV_2_Status 870;
BA_ "GenSigSendType" SG_ 870 AWV_2_Status 0;
BA_ "GenSigTimeoutTime_Gateway_PQ35_A" SG_ 870 AWV_2_SU_Warnzeit 500;
BA_ "GenSigTimeoutMsg_Gateway_PQ35_A" SG_ 870 AWV_2_SU_Warnzeit 870;
BA_ "GenSigTimeoutTime_HCA" SG_ 870 AWV_2_SU_Warnzeit 500;
BA_ "GenSigTimeoutMsg_HCA" SG_ 870 AWV_2_SU_Warnzeit 870;
BA_ "GenSigTimeoutTime_TRW_ESP" SG_ 870 AWV_2_SU_Warnzeit 500;
BA_ "GenSigTimeoutMsg_TRW_ESP" SG_ 870 AWV_2_SU_Warnzeit 870;
BA_ "GenSigTimeoutTime_Gateway_PQ46_A" SG_ 870 AWV_2_SU_Warnzeit 500;
BA_ "GenSigTimeoutMsg_Gateway_PQ46_A" SG_ 870 AWV_2_SU_Warnzeit 870;
BA_ "GenSigSendType" SG_ 870 AWV_2_SU_Warnzeit 0;
BA_ "GenSigTimeoutTime_Gateway_PQ35_A" SG_ 870 AWV_Checksumme 500;
BA_ "GenSigTimeoutMsg_Gateway_PQ35_A" SG_ 870 AWV_Checksumme 870;
BA_ "GenSigTimeoutTime_HCA" SG_ 870 AWV_Checksumme 500;
BA_ "GenSigTimeoutMsg_HCA" SG_ 870 AWV_Checksumme 870;
BA_ "GenSigTimeoutTime_TRW_ESP" SG_ 870 AWV_Checksumme 500;
BA_ "GenSigTimeoutMsg_TRW_ESP" SG_ 870 AWV_Checksumme 870;
BA_ "GenSigTimeoutTime_Gateway_PQ46_A" SG_ 870 AWV_Checksumme 500;
BA_ "GenSigTimeoutMsg_Gateway_PQ46_A" SG_ 870 AWV_Checksumme 870;
BA_ "GenSigSendType" SG_ 870 AWV_Checksumme 0;
BA_ "INIT" SG_ 870 AWV_Checksumme "CHK";
BA_ "GenSigTimeoutTime_Gateway_PQ35_A" SG_ 870 AWV_Zaehler 500;
BA_ "GenSigTimeoutMsg_Gateway_PQ35_A" SG_ 870 AWV_Zaehler 870;
BA_ "GenSigTimeoutTime_HCA" SG_ 870 AWV_Zaehler 500;
BA_ "GenSigTimeoutMsg_HCA" SG_ 870 AWV_Zaehler 870;
BA_ "GenSigTimeoutTime_TRW_ESP" SG_ 870 AWV_Zaehler 500;
BA_ "GenSigTimeoutMsg_TRW_ESP" SG_ 870 AWV_Zaehler 870;
BA_ "GenSigTimeoutTime_Gateway_PQ46_A" SG_ 870 AWV_Zaehler 500;
BA_ "GenSigTimeoutMsg_Gateway_PQ46_A" SG_ 870 AWV_Zaehler 870;
BA_ "GenSigSendType" SG_ 870 AWV_Zaehler 0;
BA_ "GenSigTimeoutTime_Gateway_PQ35_A" SG_ 870 AWV_2_Fehler 500;
BA_ "GenSigTimeoutMsg_Gateway_PQ35_A" SG_ 870 AWV_2_Fehler 870;
BA_ "GenSigTimeoutTime_HCA" SG_ 870 AWV_2_Fehler 500;
BA_ "GenSigTimeoutMsg_HCA" SG_ 870 AWV_2_Fehler 870;
BA_ "GenSigTimeoutTime_TRW_ESP" SG_ 870 AWV_2_Fehler 500;
BA_ "GenSigTimeoutMsg_TRW_ESP" SG_ 870 AWV_2_Fehler 870;
BA_ "GenSigTimeoutTime_Gateway_PQ46_A" SG_ 870 AWV_2_Fehler 500;
BA_ "GenSigTimeoutMsg_Gateway_PQ46_A" SG_ 870 AWV_2_Fehler 870;
BA_ "GenSigSendType" SG_ 870 AWV_2_Fehler 0;
BA_ "GenSigTimeoutTime_Gateway_PQ35_A" SG_ 870 AWV_1_Prefill 500;
BA_ "GenSigTimeoutMsg_Gateway_PQ35_A" SG_ 870 AWV_1_Prefill 870;
BA_ "GenSigTimeoutTime_HCA" SG_ 870 AWV_1_Prefill 500;
BA_ "GenSigTimeoutMsg_HCA" SG_ 870 AWV_1_Prefill 870;
BA_ "GenSigTimeoutTime_TRW_ESP" SG_ 870 AWV_1_Prefill 500;
BA_ "GenSigTimeoutMsg_TRW_ESP" SG_ 870 AWV_1_Prefill 870;
BA_ "GenSigTimeoutTime_Gateway_PQ46_A" SG_ 870 AWV_1_Prefill 500;
BA_ "GenSigTimeoutMsg_Gateway_PQ46_A" SG_ 870 AWV_1_Prefill 870;
BA_ "GenSigSendType" SG_ 870 AWV_1_Prefill 0;
BA_ "GenSigTimeoutTime_Gateway_PQ35_A" SG_ 870 AWV_Text 500;
BA_ "GenSigTimeoutMsg_Gateway_PQ35_A" SG_ 870 AWV_Text 870;
BA_ "GenSigTimeoutTime_HCA" SG_ 870 AWV_Text 500;
BA_ "GenSigTimeoutMsg_HCA" SG_ 870 AWV_Text 870;
BA_ "GenSigTimeoutTime_TRW_ESP" SG_ 870 AWV_Text 500;
BA_ "GenSigTimeoutMsg_TRW_ESP" SG_ 870 AWV_Text 870;
BA_ "GenSigTimeoutTime_Gateway_PQ46_A" SG_ 870 AWV_Text 500;
BA_ "GenSigTimeoutMsg_Gateway_PQ46_A" SG_ 870 AWV_Text 870;
BA_ "GenSigSendType" SG_ 870 AWV_Text 0;
BA_ "GenSigTimeoutTime_TRW_ESP" SG_ 870 AWV_res_20 500;
BA_ "GenSigTimeoutMsg_TRW_ESP" SG_ 870 AWV_res_20 870;
BA_ "GenSigTimeoutTime_HCA" SG_ 870 AWV_res_20 500;
BA_ "GenSigTimeoutMsg_HCA" SG_ 870 AWV_res_20 870;
BA_ "GenSigTimeoutTime_Gateway_PQ35_A" SG_ 870 AWV_res_20 500;
BA_ "GenSigTimeoutMsg_Gateway_PQ35_A" SG_ 870 AWV_res_20 870;
BA_ "GenSigTimeoutTime_Gateway_PQ46_A" SG_ 870 AWV_res_20 500;
BA_ "GenSigTimeoutMsg_Gateway_PQ46_A" SG_ 870 AWV_res_20 870;
BA_ "GenSigSendType" SG_ 870 AWV_res_20 0;
BA_ "GenSigTimeoutTime_Gateway_PQ35_A" SG_ 870 AWV_1_Freigabe 500;
BA_ "GenSigTimeoutMsg_Gateway_PQ35_A" SG_ 870 AWV_1_Freigabe 870;
BA_ "GenSigTimeoutTime_HCA" SG_ 870 AWV_1_Freigabe 500;
BA_ "GenSigTimeoutMsg_HCA" SG_ 870 AWV_1_Freigabe 870;
BA_ "GenSigTimeoutTime_TRW_ESP" SG_ 870 AWV_1_Freigabe 500;
BA_ "GenSigTimeoutMsg_TRW_ESP" SG_ 870 AWV_1_Freigabe 870;
BA_ "GenSigTimeoutTime_Gateway_PQ46_A" SG_ 870 AWV_1_Freigabe 500;
BA_ "GenSigTimeoutMsg_Gateway_PQ46_A" SG_ 870 AWV_1_Freigabe 870;
BA_ "GenSigSendType" SG_ 870 AWV_1_Freigabe 0;
BA_ "GenSigTimeoutTime_Gateway_PQ35_A" SG_ 870 AWV_2_SU_Bremsruck 500;
BA_ "GenSigTimeoutMsg_Gateway_PQ35_A" SG_ 870 AWV_2_SU_Bremsruck 870;
BA_ "GenSigTimeoutTime_HCA" SG_ 870 AWV_2_SU_Bremsruck 500;
BA_ "GenSigTimeoutMsg_HCA" SG_ 870 AWV_2_SU_Bremsruck 870;
BA_ "GenSigTimeoutTime_TRW_ESP" SG_ 870 AWV_2_SU_Bremsruck 500;
BA_ "GenSigTimeoutMsg_TRW_ESP" SG_ 870 AWV_2_SU_Bremsruck 870;
BA_ "GenSigTimeoutTime_Gateway_PQ46_A" SG_ 870 AWV_2_SU_Bremsruck 500;
BA_ "GenSigTimeoutMsg_Gateway_PQ46_A" SG_ 870 AWV_2_SU_Bremsruck 870;
BA_ "GenSigSendType" SG_ 870 AWV_2_SU_Bremsruck 0;
BA_ "GenSigStartValue" SG_ 870 AWV_2_SU_Bremsruck 1;
BA_ "GenSigTimeoutTime_Gateway_PQ35_A" SG_ 870 AWV_1_Parameter 500;
BA_ "GenSigTimeoutMsg_Gateway_PQ35_A" SG_ 870 AWV_1_Parameter 870;
BA_ "GenSigTimeoutTime_HCA" SG_ 870 AWV_1_Parameter 500;
BA_ "GenSigTimeoutMsg_HCA" SG_ 870 AWV_1_Parameter 870;
BA_ "GenSigTimeoutTime_TRW_ESP" SG_ 870 AWV_1_Parameter 500;
BA_ "GenSigTimeoutMsg_TRW_ESP" SG_ 870 AWV_1_Parameter 870;
BA_ "GenSigTimeoutTime_Gateway_PQ46_A" SG_ 870 AWV_1_Parameter 500;
BA_ "GenSigTimeoutMsg_Gateway_PQ46_A" SG_ 870 AWV_1_Parameter 870;
BA_ "GenSigSendType" SG_ 870 AWV_1_Parameter 0;
BA_ "GenSigTimeoutTime_Gateway_PQ35_A" SG_ 870 AWV_2_Umfeldwarn 500;
BA_ "GenSigTimeoutMsg_Gateway_PQ35_A" SG_ 870 AWV_2_Umfeldwarn 870;
BA_ "GenSigTimeoutTime_HCA" SG_ 870 AWV_2_Umfeldwarn 500;
BA_ "GenSigTimeoutMsg_HCA" SG_ 870 AWV_2_Umfeldwarn 870;
BA_ "GenSigTimeoutTime_TRW_ESP" SG_ 870 AWV_2_Umfeldwarn 500;
BA_ "GenSigTimeoutMsg_TRW_ESP" SG_ 870 AWV_2_Umfeldwarn 870;
BA_ "GenSigTimeoutTime_Gateway_PQ46_A" SG_ 870 AWV_2_Umfeldwarn 500;
BA_ "GenSigTimeoutMsg_Gateway_PQ46_A" SG_ 870 AWV_2_Umfeldwarn 870;
BA_ "GenSigSendType" SG_ 870 AWV_2_Umfeldwarn 0;
BA_ "GenSigTimeoutTime_Gateway_PQ35_A" SG_ 870 AWV_2_Freigabe 500;
BA_ "GenSigTimeoutMsg_Gateway_PQ35_A" SG_ 870 AWV_2_Freigabe 870;
BA_ "GenSigTimeoutTime_HCA" SG_ 870 AWV_2_Freigabe 500;
BA_ "GenSigTimeoutMsg_HCA" SG_ 870 AWV_2_Freigabe 870;
BA_ "GenSigTimeoutTime_TRW_ESP" SG_ 870 AWV_2_Freigabe 500;
BA_ "GenSigTimeoutMsg_TRW_ESP" SG_ 870 AWV_2_Freigabe 870;
BA_ "GenSigTimeoutTime_Gateway_PQ46_A" SG_ 870 AWV_2_Freigabe 500;
BA_ "GenSigTimeoutMsg_Gateway_PQ46_A" SG_ 870 AWV_2_Freigabe 870;
BA_ "GenSigSendType" SG_ 870 AWV_2_Freigabe 0;
BA_ "GenSigTimeoutTime_Gateway_PQ35_A" SG_ 870 AWV_2_Gurtstraffer 500;
BA_ "GenSigTimeoutMsg_Gateway_PQ35_A" SG_ 870 AWV_2_Gurtstraffer 870;
BA_ "GenSigTimeoutTime_HCA" SG_ 870 AWV_2_Gurtstraffer 500;
BA_ "GenSigTimeoutMsg_HCA" SG_ 870 AWV_2_Gurtstraffer 870;
BA_ "GenSigTimeoutTime_TRW_ESP" SG_ 870 AWV_2_Gurtstraffer 500;
BA_ "GenSigTimeoutMsg_TRW_ESP" SG_ 870 AWV_2_Gurtstraffer 870;
BA_ "GenSigTimeoutTime_Gateway_PQ46_A" SG_ 870 AWV_2_Gurtstraffer 500;
BA_ "GenSigTimeoutMsg_Gateway_PQ46_A" SG_ 870 AWV_2_Gurtstraffer 870;
BA_ "GenSigSendType" SG_ 870 AWV_2_Gurtstraffer 0;
BA_ "GenSigTimeoutTime_Gateway_PQ35_A" SG_ 870 AWV_2_SU_Gong 500;
BA_ "GenSigTimeoutMsg_Gateway_PQ35_A" SG_ 870 AWV_2_SU_Gong 870;
BA_ "GenSigTimeoutTime_HCA" SG_ 870 AWV_2_SU_Gong 500;
BA_ "GenSigTimeoutMsg_HCA" SG_ 870 AWV_2_SU_Gong 870;
BA_ "GenSigTimeoutTime_TRW_ESP" SG_ 870 AWV_2_SU_Gong 500;
BA_ "GenSigTimeoutMsg_TRW_ESP" SG_ 870 AWV_2_SU_Gong 870;
BA_ "GenSigTimeoutTime_Gateway_PQ46_A" SG_ 870 AWV_2_SU_Gong 500;
BA_ "GenSigTimeoutMsg_Gateway_PQ46_A" SG_ 870 AWV_2_SU_Gong 870;
BA_ "GenSigSendType" SG_ 870 AWV_2_SU_Gong 0;
BA_ "GenSigStartValue" SG_ 870 AWV_2_SU_Gong 1;
BA_ "GenSigTimeoutTime_Gateway_PQ35_A" SG_ 870 AWV_Infoton 500;
BA_ "GenSigTimeoutMsg_Gateway_PQ35_A" SG_ 870 AWV_Infoton 870;
BA_ "GenSigTimeoutTime_HCA" SG_ 870 AWV_Infoton 500;
BA_ "GenSigTimeoutMsg_HCA" SG_ 870 AWV_Infoton 870;
BA_ "GenSigTimeoutTime_TRW_ESP" SG_ 870 AWV_Infoton 500;
BA_ "GenSigTimeoutMsg_TRW_ESP" SG_ 870 AWV_Infoton 870;
BA_ "GenSigTimeoutTime_Gateway_PQ46_A" SG_ 870 AWV_Infoton 500;
BA_ "GenSigTimeoutMsg_Gateway_PQ46_A" SG_ 870 AWV_Infoton 870;
BA_ "GenSigSendType" SG_ 870 AWV_Infoton 0;
BA_ "GenSigTimeoutTime_Gateway_PQ35_A" SG_ 870 AWV_2_Warnsymbol 500;
BA_ "GenSigTimeoutMsg_Gateway_PQ35_A" SG_ 870 AWV_2_Warnsymbol 870;
BA_ "GenSigTimeoutTime_HCA" SG_ 870 AWV_2_Warnsymbol 500;
BA_ "GenSigTimeoutMsg_HCA" SG_ 870 AWV_2_Warnsymbol 870;
BA_ "GenSigTimeoutTime_TRW_ESP" SG_ 870 AWV_2_Warnsymbol 500;
BA_ "GenSigTimeoutMsg_TRW_ESP" SG_ 870 AWV_2_Warnsymbol 870;
BA_ "GenSigTimeoutTime_Gateway_PQ46_A" SG_ 870 AWV_2_Warnsymbol 500;
BA_ "GenSigTimeoutMsg_Gateway_PQ46_A" SG_ 870 AWV_2_Warnsymbol 870;
BA_ "GenSigSendType" SG_ 870 AWV_2_Warnsymbol 0;
BA_ "GenSigTimeoutTime_Gateway_PQ35_A" SG_ 870 AWV_2_Warnton 500;
BA_ "GenSigTimeoutMsg_Gateway_PQ35_A" SG_ 870 AWV_2_Warnton 870;
BA_ "GenSigTimeoutTime_HCA" SG_ 870 AWV_2_Warnton 500;
BA_ "GenSigTimeoutMsg_HCA" SG_ 870 AWV_2_Warnton 870;
BA_ "GenSigTimeoutTime_TRW_ESP" SG_ 870 AWV_2_Warnton 500;
BA_ "GenSigTimeoutMsg_TRW_ESP" SG_ 870 AWV_2_Warnton 870;
BA_ "GenSigTimeoutTime_Gateway_PQ46_A" SG_ 870 AWV_2_Warnton 500;
BA_ "GenSigTimeoutMsg_Gateway_PQ46_A" SG_ 870 AWV_2_Warnton 870;
BA_ "GenSigSendType" SG_ 870 AWV_2_Warnton 0;
BA_ "GenSigTimeoutTime_Gateway_PQ35_A" SG_ 870 AWV_2_Ruckprofil 500;
BA_ "GenSigTimeoutMsg_Gateway_PQ35_A" SG_ 870 AWV_2_Ruckprofil 870;
BA_ "GenSigTimeoutTime_HCA" SG_ 870 AWV_2_Ruckprofil 500;
BA_ "GenSigTimeoutMsg_HCA" SG_ 870 AWV_2_Ruckprofil 870;
BA_ "GenSigTimeoutTime_TRW_ESP" SG_ 870 AWV_2_Ruckprofil 500;
BA_ "GenSigTimeoutMsg_TRW_ESP" SG_ 870 AWV_2_Ruckprofil 870;
BA_ "GenSigTimeoutTime_Gateway_PQ46_A" SG_ 870 AWV_2_Ruckprofil 500;
BA_ "GenSigTimeoutMsg_Gateway_PQ46_A" SG_ 870 AWV_2_Ruckprofil 870;
BA_ "GenSigSendType" SG_ 870 AWV_2_Ruckprofil 0;
BA_ "GenSigTimeoutTime_Gateway_PQ35_A" SG_ 870 AWV_2_SU_Lampe 500;
BA_ "GenSigTimeoutMsg_Gateway_PQ35_A" SG_ 870 AWV_2_SU_Lampe 870;
BA_ "GenSigTimeoutTime_HCA" SG_ 870 AWV_2_SU_Lampe 500;
BA_ "GenSigTimeoutMsg_HCA" SG_ 870 AWV_2_SU_Lampe 870;
BA_ "GenSigTimeoutTime_TRW_ESP" SG_ 870 AWV_2_SU_Lampe 500;
BA_ "GenSigTimeoutMsg_TRW_ESP" SG_ 870 AWV_2_SU_Lampe 870;
BA_ "GenSigTimeoutTime_Gateway_PQ46_A" SG_ 870 AWV_2_SU_Lampe 500;
BA_ "GenSigTimeoutMsg_Gateway_PQ46_A" SG_ 870 AWV_2_SU_Lampe 870;
BA_ "GenSigSendType" SG_ 870 AWV_2_SU_Lampe 0;
BA_ "GenSigStartValue" SG_ 870 AWV_2_SU_Lampe 1;
BA_ "GenSigTimeoutMsg_Gateway_PQ35_A" SG_ 1652 BAP_Data_ACC 1652;
BA_ "GenSigTimeoutMsg_Gateway_PQ46_A" SG_ 1652 BAP_Data_ACC 1652;
BA_ "GenSigTimeoutMsg_Gateway_PQ35_A" SG_ 1652 BAP_var_ACC 1652;
BA_ "GenSigTimeoutMsg_Gateway_PQ46_A" SG_ 1652 BAP_var_ACC 1652;
BA_ "GenSigSendType" SG_ 1688 AFZ_ParaSW_L 0;
BA_ "GenSigSendType" SG_ 1688 AFZ_ParaSW_R 0;
BA_ "GenSigSendType" SG_ 1688 AFZ_Modus 0;
BA_ "GenSigSendType" SG_ 1688 AFZ_Init 0;
BA_ "GenSigSendType" SG_ 1688 AFZ_SafePos 0;
BA_ "GenSigSendType" SG_ 1688 AFZ_IstPosMot_L 0;
BA_ "GenSigStartValue" SG_ 1688 AFZ_IstPosMot_L 254;
BA_ "GenSigSendType" SG_ 1688 AFZ_IstPosMot_R 0;
BA_ "GenSigStartValue" SG_ 1688 AFZ_IstPosMot_R 254;
BA_ "GenSigSendType" SG_ 1688 AFZ_Soll_EVG 0;
BA_ "GenSigStartValue" SG_ 1688 AFZ_Soll_EVG 254;
BA_ "GenSigSendType" SG_ 1688 AFZ_IstDimAbLi 0;
BA_ "GenSigStartValue" SG_ 1688 AFZ_IstDimAbLi 254;
BA_ "GenSigSendType" SG_ 1688 AFZ_IstDimAbRe 0;
BA_ "GenSigStartValue" SG_ 1688 AFZ_IstDimAbRe 254;
BA_ "GenSigSendType" SG_ 1688 AFZ_StaLamp_L 0;
BA_ "GenSigSendType" SG_ 1688 AFZ_StaLamp_R 0;
BA_ "GenSigSendType" SG_ 1688 AFZ_res_56 0;
BA_ "GenSigTimeoutTime_AFS" SG_ 1428 NI2_Hoehe_HR 500;
BA_ "GenSigTimeoutMsg_AFS" SG_ 1428 NI2_Hoehe_HR 1428;
BA_ "GenSigTimeoutTime_LWR" SG_ 1428 NI2_Hoehe_HR 500;
BA_ "GenSigTimeoutMsg_LWR" SG_ 1428 NI2_Hoehe_HR 1428;
BA_ "GenSigSendType" SG_ 1428 NI2_Hoehe_HR 0;
BA_ "GenSigTimeoutTime_AFS" SG_ 1428 NI2_Hoehe_VL 500;
BA_ "GenSigTimeoutMsg_AFS" SG_ 1428 NI2_Hoehe_VL 1428;
BA_ "GenSigTimeoutTime_LWR" SG_ 1428 NI2_Hoehe_VL 500;
BA_ "GenSigTimeoutMsg_LWR" SG_ 1428 NI2_Hoehe_VL 1428;
BA_ "GenSigSendType" SG_ 1428 NI2_Hoehe_VL 0;
BA_ "GenSigTimeoutTime_AFS" SG_ 1428 NI2_Hoehe_HL 500;
BA_ "GenSigTimeoutMsg_AFS" SG_ 1428 NI2_Hoehe_HL 1428;
BA_ "GenSigTimeoutTime_LWR" SG_ 1428 NI2_Hoehe_HL 500;
BA_ "GenSigTimeoutMsg_LWR" SG_ 1428 NI2_Hoehe_HL 1428;
BA_ "GenSigSendType" SG_ 1428 NI2_Hoehe_HL 0;
BA_ "GenSigTimeoutTime_AFS" SG_ 1428 NI2_Checksum 500;
BA_ "GenSigTimeoutMsg_AFS" SG_ 1428 NI2_Checksum 1428;
BA_ "GenSigTimeoutTime_LWR" SG_ 1428 NI2_Checksum 500;
BA_ "GenSigTimeoutMsg_LWR" SG_ 1428 NI2_Checksum 1428;
BA_ "GenSigSendType" SG_ 1428 NI2_Checksum 0;
BA_ "INIT" SG_ 1428 NI2_Checksum "CHK";
BA_ "GenSigTimeoutTime_AFS" SG_ 1428 NI2_Hoehe_VR 500;
BA_ "GenSigTimeoutMsg_AFS" SG_ 1428 NI2_Hoehe_VR 1428;
BA_ "GenSigTimeoutTime_LWR" SG_ 1428 NI2_Hoehe_VR 500;
BA_ "GenSigTimeoutMsg_LWR" SG_ 1428 NI2_Hoehe_VR 1428;
BA_ "GenSigSendType" SG_ 1428 NI2_Hoehe_VR 0;
BA_ "GenSigTimeoutTime_LWR" SG_ 1428 NI2_AufbBeschl_VL 500;
BA_ "GenSigTimeoutMsg_LWR" SG_ 1428 NI2_AufbBeschl_VL 1428;
BA_ "GenSigTimeoutTime_AFS" SG_ 1428 NI2_AufbBeschl_VL 500;
BA_ "GenSigTimeoutMsg_AFS" SG_ 1428 NI2_AufbBeschl_VL 1428;
BA_ "GenSigSendType" SG_ 1428 NI2_AufbBeschl_VL 0;
BA_ "GenSigTimeoutTime_AFS" SG_ 1428 NI2_Zaehler 500;
BA_ "GenSigTimeoutMsg_AFS" SG_ 1428 NI2_Zaehler 1428;
BA_ "GenSigTimeoutTime_LWR" SG_ 1428 NI2_Zaehler 500;
BA_ "GenSigTimeoutMsg_LWR" SG_ 1428 NI2_Zaehler 1428;
BA_ "GenSigSendType" SG_ 1428 NI2_Zaehler 0;
BA_ "GenSigTimeoutTime_LWR" SG_ 1428 NI2_Reserve1 500;
BA_ "GenSigTimeoutMsg_LWR" SG_ 1428 NI2_Reserve1 1428;
BA_ "GenSigTimeoutTime_AFS" SG_ 1428 NI2_Reserve1 500;
BA_ "GenSigTimeoutMsg_AFS" SG_ 1428 NI2_Reserve1 1428;
BA_ "GenSigSendType" SG_ 1428 NI2_Reserve1 0;
BA_ "GenSigTimeoutTime_LWR" SG_ 1428 NI2_AufbBeschl_VR 500;
BA_ "GenSigTimeoutMsg_LWR" SG_ 1428 NI2_AufbBeschl_VR 1428;
BA_ "GenSigTimeoutTime_AFS" SG_ 1428 NI2_AufbBeschl_VR 500;
BA_ "GenSigTimeoutMsg_AFS" SG_ 1428 NI2_AufbBeschl_VR 1428;
BA_ "GenSigSendType" SG_ 1428 NI2_AufbBeschl_VR 0;
BA_ "GenSigTimeoutTime_AFS" SG_ 1428 NI2_Hoehe_VL_Roh 500;
BA_ "GenSigTimeoutMsg_AFS" SG_ 1428 NI2_Hoehe_VL_Roh 1428;
BA_ "GenSigSendType" SG_ 1428 NI2_Hoehe_VL_Roh 0;
BA_ "GenSigStartValue" SG_ 1428 NI2_Hoehe_VL_Roh 254;
BA_ "GenSigTimeoutTime_AFS" SG_ 1428 NI2_Hoehe_HR_Roh 500;
BA_ "GenSigTimeoutMsg_AFS" SG_ 1428 NI2_Hoehe_HR_Roh 1428;
BA_ "GenSigSendType" SG_ 1428 NI2_Hoehe_HR_Roh 0;
BA_ "GenSigStartValue" SG_ 1428 NI2_Hoehe_HR_Roh 254;
BA_ "GenSigTimeoutTime_AFS" SG_ 1428 NI2_Hoehe_HL_Roh 500;
BA_ "GenSigTimeoutMsg_AFS" SG_ 1428 NI2_Hoehe_HL_Roh 1428;
BA_ "GenSigSendType" SG_ 1428 NI2_Hoehe_HL_Roh 0;
BA_ "GenSigStartValue" SG_ 1428 NI2_Hoehe_HL_Roh 254;
BA_ "GenSigTimeoutTime_AFS" SG_ 1428 NI2_Hoehenflag 500;
BA_ "GenSigTimeoutMsg_AFS" SG_ 1428 NI2_Hoehenflag 1428;
BA_ "GenSigSendType" SG_ 1428 NI2_Hoehenflag 0;
BA_ "GenSigTimeoutTime_AFS" SG_ 1428 NI2_Hoehe_VR_Roh 500;
BA_ "GenSigTimeoutMsg_AFS" SG_ 1428 NI2_Hoehe_VR_Roh 1428;
BA_ "GenSigSendType" SG_ 1428 NI2_Hoehe_VR_Roh 0;
BA_ "GenSigStartValue" SG_ 1428 NI2_Hoehe_VR_Roh 254;
BA_ "GenSigTimeoutMsg_Gateway_PQ35_A" SG_ 524 Daempfer_TP_Er 524;
BA_ "GenSigTimeoutMsg_Gateway_PQ46_A" SG_ 524 Daempfer_TP_Er 524;
BA_ "GenSigSendType" SG_ 524 Daempfer_TP_Er 5;
BA_ "GenSigTimeoutTime_Gateway_PQ35_A" SG_ 1432 DA1_Warnlampe 1000;
BA_ "GenSigTimeoutMsg_Gateway_PQ35_A" SG_ 1432 DA1_Warnlampe 1432;
BA_ "GenSigTimeoutTime_Teves_MK60_ESP" SG_ 1432 DA1_Warnlampe 1000;
BA_ "GenSigTimeoutMsg_Teves_MK60_ESP" SG_ 1432 DA1_Warnlampe 1432;
BA_ "GenSigTimeoutTime_Gateway_PQ46_A" SG_ 1432 DA1_Warnlampe 1000;
BA_ "GenSigTimeoutMsg_Gateway_PQ46_A" SG_ 1432 DA1_Warnlampe 1432;
BA_ "GenSigSendType" SG_ 1432 DA1_Warnlampe 0;
BA_ "GenSigTimeoutTime_Gateway_PQ35_A" SG_ 1432 DA1_Systemstatus 1000;
BA_ "GenSigTimeoutMsg_Gateway_PQ35_A" SG_ 1432 DA1_Systemstatus 1432;
BA_ "GenSigTimeoutTime_Teves_MK60_ESP" SG_ 1432 DA1_Systemstatus 1000;
BA_ "GenSigTimeoutMsg_Teves_MK60_ESP" SG_ 1432 DA1_Systemstatus 1432;
BA_ "GenSigTimeoutTime_Gateway_PQ46_A" SG_ 1432 DA1_Systemstatus 1000;
BA_ "GenSigTimeoutMsg_Gateway_PQ46_A" SG_ 1432 DA1_Systemstatus 1432;
BA_ "GenSigSendType" SG_ 1432 DA1_Systemstatus 0;
BA_ "GenSigTimeoutTime_Gateway_PQ35_A" SG_ 1432 DA1_Taster 1000;
BA_ "GenSigTimeoutMsg_Gateway_PQ35_A" SG_ 1432 DA1_Taster 1432;
BA_ "GenSigTimeoutTime_Teves_MK60_ESP" SG_ 1432 DA1_Taster 1000;
BA_ "GenSigTimeoutMsg_Teves_MK60_ESP" SG_ 1432 DA1_Taster 1432;
BA_ "GenSigTimeoutTime_Gateway_PQ46_A" SG_ 1432 DA1_Taster 1000;
BA_ "GenSigTimeoutMsg_Gateway_PQ46_A" SG_ 1432 DA1_Taster 1432;
BA_ "GenSigSendType" SG_ 1432 DA1_Taster 0;
BA_ "GenSigTimeoutTime_Gateway_PQ35_A" SG_ 1432 DA1_Textbits 1000;
BA_ "GenSigTimeoutMsg_Gateway_PQ35_A" SG_ 1432 DA1_Textbits 1432;
BA_ "GenSigTimeoutTime_Teves_MK60_ESP" SG_ 1432 DA1_Textbits 1000;
BA_ "GenSigTimeoutMsg_Teves_MK60_ESP" SG_ 1432 DA1_Textbits 1432;
BA_ "GenSigTimeoutTime_Gateway_PQ46_A" SG_ 1432 DA1_Textbits 1000;
BA_ "GenSigTimeoutMsg_Gateway_PQ46_A" SG_ 1432 DA1_Textbits 1432;
BA_ "GenSigSendType" SG_ 1432 DA1_Textbits 0;
BA_ "GenSigTimeoutTime_Gateway_PQ35_A" SG_ 1432 DA1_Zaehler 1000;
BA_ "GenSigTimeoutMsg_Gateway_PQ35_A" SG_ 1432 DA1_Zaehler 1432;
BA_ "GenSigTimeoutTime_Teves_MK60_ESP" SG_ 1432 DA1_Zaehler 1000;
BA_ "GenSigTimeoutMsg_Teves_MK60_ESP" SG_ 1432 DA1_Zaehler 1432;
BA_ "GenSigTimeoutTime_Gateway_PQ46_A" SG_ 1432 DA1_Zaehler 1000;
BA_ "GenSigTimeoutMsg_Gateway_PQ46_A" SG_ 1432 DA1_Zaehler 1432;
BA_ "GenSigSendType" SG_ 1432 DA1_Zaehler 0;
BA_ "GenSigTimeoutTime_Teves_MK60_ESP" SG_ 1432 DA1_res_06 1000;
BA_ "GenSigTimeoutMsg_Teves_MK60_ESP" SG_ 1432 DA1_res_06 1432;
BA_ "GenSigTimeoutTime_Gateway_PQ35_A" SG_ 1432 DA1_res_06 1000;
BA_ "GenSigTimeoutMsg_Gateway_PQ35_A" SG_ 1432 DA1_res_06 1432;
BA_ "GenSigTimeoutTime_Gateway_PQ46_A" SG_ 1432 DA1_res_06 1000;
BA_ "GenSigTimeoutMsg_Gateway_PQ46_A" SG_ 1432 DA1_res_06 1432;
BA_ "GenSigSendType" SG_ 1432 DA1_res_06 0;
BA_ "GenSigTimeoutTime_Gateway_PQ35_A" SG_ 1432 DA1_Daempferreg 1000;
BA_ "GenSigTimeoutMsg_Gateway_PQ35_A" SG_ 1432 DA1_Daempferreg 1432;
BA_ "GenSigTimeoutTime_Teves_MK60_ESP" SG_ 1432 DA1_Daempferreg 1000;
BA_ "GenSigTimeoutMsg_Teves_MK60_ESP" SG_ 1432 DA1_Daempferreg 1432;
BA_ "GenSigTimeoutTime_Gateway_PQ46_A" SG_ 1432 DA1_Daempferreg 1000;
BA_ "GenSigTimeoutMsg_Gateway_PQ46_A" SG_ 1432 DA1_Daempferreg 1432;
BA_ "GenSigSendType" SG_ 1432 DA1_Daempferreg 0;
BA_ "GenSigTimeoutTime_Gateway_PQ35_A" SG_ 1432 DA1_Checksumme 1000;
BA_ "GenSigTimeoutMsg_Gateway_PQ35_A" SG_ 1432 DA1_Checksumme 1432;
BA_ "GenSigTimeoutTime_Teves_MK60_ESP" SG_ 1432 DA1_Checksumme 1000;
BA_ "GenSigTimeoutMsg_Teves_MK60_ESP" SG_ 1432 DA1_Checksumme 1432;
BA_ "GenSigTimeoutTime_Gateway_PQ46_A" SG_ 1432 DA1_Checksumme 1000;
BA_ "GenSigTimeoutMsg_Gateway_PQ46_A" SG_ 1432 DA1_Checksumme 1432;
BA_ "GenSigSendType" SG_ 1432 DA1_Checksumme 0;
BA_ "INIT" SG_ 1432 DA1_Checksumme "CHK";
BA_ "GenSigTimeoutTime_Gateway_PQ35_A" SG_ 1432 DA1_Fehlereintr 1000;
BA_ "GenSigTimeoutMsg_Gateway_PQ35_A" SG_ 1432 DA1_Fehlereintr 1432;
BA_ "GenSigTimeoutTime_Teves_MK60_ESP" SG_ 1432 DA1_Fehlereintr 1000;
BA_ "GenSigTimeoutMsg_Teves_MK60_ESP" SG_ 1432 DA1_Fehlereintr 1432;
BA_ "GenSigTimeoutTime_Gateway_PQ46_A" SG_ 1432 DA1_Fehlereintr 1000;
BA_ "GenSigTimeoutMsg_Gateway_PQ46_A" SG_ 1432 DA1_Fehlereintr 1432;
BA_ "GenSigSendType" SG_ 1432 DA1_Fehlereintr 0;
BA_ "GenSigTimeoutTime_Teves_MK60_ESP" SG_ 1432 DA1_res_32 1000;
BA_ "GenSigTimeoutMsg_Teves_MK60_ESP" SG_ 1432 DA1_res_32 1432;
BA_ "GenSigTimeoutTime_Gateway_PQ35_A" SG_ 1432 DA1_res_32 1000;
BA_ "GenSigTimeoutMsg_Gateway_PQ35_A" SG_ 1432 DA1_res_32 1432;
BA_ "GenSigTimeoutTime_Gateway_PQ46_A" SG_ 1432 DA1_res_32 1000;
BA_ "GenSigTimeoutMsg_Gateway_PQ46_A" SG_ 1432 DA1_res_32 1432;
BA_ "GenSigSendType" SG_ 1432 DA1_res_32 0;
BA_ "GenSigTimeoutTime_Gateway_PQ35_A" SG_ 1432 DA1_ESP_Zwang 1000;
BA_ "GenSigTimeoutMsg_Gateway_PQ35_A" SG_ 1432 DA1_ESP_Zwang 1432;
BA_ "GenSigTimeoutTime_Teves_MK60_ESP" SG_ 1432 DA1_ESP_Zwang 1000;
BA_ "GenSigTimeoutMsg_Teves_MK60_ESP" SG_ 1432 DA1_ESP_Zwang 1432;
BA_ "GenSigTimeoutTime_Gateway_PQ46_A" SG_ 1432 DA1_ESP_Zwang 1000;
BA_ "GenSigTimeoutMsg_Gateway_PQ46_A" SG_ 1432 DA1_ESP_Zwang 1432;
BA_ "GenSigSendType" SG_ 1432 DA1_ESP_Zwang 0;
BA_ "GenSigTimeoutTime_Teves_MK60_ESP" SG_ 1432 DA1_res_24 1000;
BA_ "GenSigTimeoutMsg_Teves_MK60_ESP" SG_ 1432 DA1_res_24 1432;
BA_ "GenSigTimeoutTime_Gateway_PQ35_A" SG_ 1432 DA1_res_24 1000;
BA_ "GenSigTimeoutMsg_Gateway_PQ35_A" SG_ 1432 DA1_res_24 1432;
BA_ "GenSigTimeoutTime_Gateway_PQ46_A" SG_ 1432 DA1_res_24 1000;
BA_ "GenSigTimeoutMsg_Gateway_PQ46_A" SG_ 1432 DA1_res_24 1432;
BA_ "GenSigSendType" SG_ 1432 DA1_res_24 0;
BA_ "GenSigTimeoutTime_Teves_MK60_ESP" SG_ 1432 DA1_res_18 1000;
BA_ "GenSigTimeoutMsg_Teves_MK60_ESP" SG_ 1432 DA1_res_18 1432;
BA_ "GenSigTimeoutTime_Gateway_PQ35_A" SG_ 1432 DA1_res_18 1000;
BA_ "GenSigTimeoutMsg_Gateway_PQ35_A" SG_ 1432 DA1_res_18 1432;
BA_ "GenSigTimeoutTime_Gateway_PQ46_A" SG_ 1432 DA1_res_18 1000;
BA_ "GenSigTimeoutMsg_Gateway_PQ46_A" SG_ 1432 DA1_res_18 1432;
BA_ "GenSigSendType" SG_ 1432 DA1_res_18 0;
BA_ "GenSigTimeoutTime_Teves_MK60_ESP" SG_ 1432 DA1_res_40 1000;
BA_ "GenSigTimeoutMsg_Teves_MK60_ESP" SG_ 1432 DA1_res_40 1432;
BA_ "GenSigTimeoutTime_Gateway_PQ35_A" SG_ 1432 DA1_res_40 1000;
BA_ "GenSigTimeoutMsg_Gateway_PQ35_A" SG_ 1432 DA1_res_40 1432;
BA_ "GenSigTimeoutTime_Gateway_PQ46_A" SG_ 1432 DA1_res_40 1000;
BA_ "GenSigTimeoutMsg_Gateway_PQ46_A" SG_ 1432 DA1_res_40 1432;
BA_ "GenSigSendType" SG_ 1432 DA1_res_40 0;
BA_ "GenSigTimeoutTime_Teves_MK60_ESP" SG_ 1432 DA1_res_48 1000;
BA_ "GenSigTimeoutMsg_Teves_MK60_ESP" SG_ 1432 DA1_res_48 1432;
BA_ "GenSigTimeoutTime_Gateway_PQ35_A" SG_ 1432 DA1_res_48 1000;
BA_ "GenSigTimeoutMsg_Gateway_PQ35_A" SG_ 1432 DA1_res_48 1432;
BA_ "GenSigTimeoutTime_Gateway_PQ46_A" SG_ 1432 DA1_res_48 1000;
BA_ "GenSigTimeoutMsg_Gateway_PQ46_A" SG_ 1432 DA1_res_48 1432;
BA_ "GenSigSendType" SG_ 1432 DA1_res_48 0;
BA_ "GenSigTimeoutTime_Gateway_PQ35_A" SG_ 1432 DA1_LampPruef 1000;
BA_ "GenSigTimeoutMsg_Gateway_PQ35_A" SG_ 1432 DA1_LampPruef 1432;
BA_ "GenSigTimeoutTime_Teves_MK60_ESP" SG_ 1432 DA1_LampPruef 1000;
BA_ "GenSigTimeoutMsg_Teves_MK60_ESP" SG_ 1432 DA1_LampPruef 1432;
BA_ "GenSigTimeoutTime_Gateway_PQ46_A" SG_ 1432 DA1_LampPruef 1000;
BA_ "GenSigTimeoutMsg_Gateway_PQ46_A" SG_ 1432 DA1_LampPruef 1432;
BA_ "GenSigSendType" SG_ 1432 DA1_LampPruef 0;
BA_ "GenSigTimeoutTime_Gateway_PQ35_A" SG_ 1432 DA1_Charisma 1000;
BA_ "GenSigTimeoutMsg_Gateway_PQ35_A" SG_ 1432 DA1_Charisma 1432;
BA_ "GenSigTimeoutTime_Gateway_PQ46_A" SG_ 1432 DA1_Charisma 1000;
BA_ "GenSigTimeoutMsg_Gateway_PQ46_A" SG_ 1432 DA1_Charisma 1432;
BA_ "GenSigSendType" SG_ 1432 DA1_Charisma 0;
BA_ "INIT" SG_ 1432 DA1_Charisma "const";
BA_ "GenSigTimeoutMsg_Gateway_PQ35_A" SG_ 520 RKA_Plus_TP_Er 520;
BA_ "GenSigSendType" SG_ 520 RKA_Plus_TP_Er 5;
BA_ "GenSigTimeoutTime_Gateway_PQ46_A" SG_ 1091 RDK_Prio1_Warnung 5000;
BA_ "GenSigTimeoutMsg_Gateway_PQ46_A" SG_ 1091 RDK_Prio1_Warnung 1091;
BA_ "GenSigTimeoutTime_Gateway_PQ35_A" SG_ 1091 RDK_Prio1_Warnung 5000;
BA_ "GenSigTimeoutMsg_Gateway_PQ35_A" SG_ 1091 RDK_Prio1_Warnung 1091;
BA_ "GenSigSendType" SG_ 1091 RDK_Prio1_Warnung 0;
BA_ "GenSigTimeoutTime_Gateway_PQ46_A" SG_ 1091 RDK_FMVSS_138_Warnung 5000;
BA_ "GenSigTimeoutMsg_Gateway_PQ46_A" SG_ 1091 RDK_FMVSS_138_Warnung 1091;
BA_ "GenSigTimeoutTime_Gateway_PQ35_A" SG_ 1091 RDK_FMVSS_138_Warnung 5000;
BA_ "GenSigTimeoutMsg_Gateway_PQ35_A" SG_ 1091 RDK_FMVSS_138_Warnung 1091;
BA_ "GenSigSendType" SG_ 1091 RDK_FMVSS_138_Warnung 0;
BA_ "GenSigStartValue" SG_ 1091 RDK_FMVSS_138_Warnung 1;
BA_ "GenSigTimeoutTime_Gateway_PQ35_A" SG_ 1091 RDK_neue_Solldruecke 5000;
BA_ "GenSigTimeoutMsg_Gateway_PQ35_A" SG_ 1091 RDK_neue_Solldruecke 1091;
BA_ "GenSigTimeoutTime_Gateway_PQ46_A" SG_ 1091 RDK_neue_Solldruecke 5000;
BA_ "GenSigTimeoutMsg_Gateway_PQ46_A" SG_ 1091 RDK_neue_Solldruecke 1091;
BA_ "GenSigSendType" SG_ 1091 RDK_neue_Solldruecke 0;
BA_ "GenSigTimeoutTime_Gateway_PQ35_A" SG_ 1091 RDK_Ack_IstZu_Solldruecke 5000;
BA_ "GenSigTimeoutMsg_Gateway_PQ35_A" SG_ 1091 RDK_Ack_IstZu_Solldruecke 1091;
BA_ "GenSigTimeoutTime_Gateway_PQ46_A" SG_ 1091 RDK_Ack_IstZu_Solldruecke 5000;
BA_ "GenSigTimeoutMsg_Gateway_PQ46_A" SG_ 1091 RDK_Ack_IstZu_Solldruecke 1091;
BA_ "GenSigSendType" SG_ 1091 RDK_Ack_IstZu_Solldruecke 0;
BA_ "GenSigTimeoutTime_Gateway_PQ35_A" SG_ 1091 RDK_res11 5000;
BA_ "GenSigTimeoutMsg_Gateway_PQ35_A" SG_ 1091 RDK_res11 1091;
BA_ "GenSigTimeoutTime_Gateway_PQ46_A" SG_ 1091 RDK_res11 5000;
BA_ "GenSigTimeoutMsg_Gateway_PQ46_A" SG_ 1091 RDK_res11 1091;
BA_ "GenSigSendType" SG_ 1091 RDK_res11 0;
BA_ "GenSigTimeoutTime_Gateway_PQ46_A" SG_ 1091 RDK_KD_Fehler 5000;
BA_ "GenSigTimeoutMsg_Gateway_PQ46_A" SG_ 1091 RDK_KD_Fehler 1091;
BA_ "GenSigTimeoutTime_Gateway_PQ35_A" SG_ 1091 RDK_KD_Fehler 5000;
BA_ "GenSigTimeoutMsg_Gateway_PQ35_A" SG_ 1091 RDK_KD_Fehler 1091;
BA_ "GenSigSendType" SG_ 1091 RDK_KD_Fehler 0;
BA_ "GenSigTimeoutTime_Gateway_PQ35_A" SG_ 1091 RDK_res12 5000;
BA_ "GenSigTimeoutMsg_Gateway_PQ35_A" SG_ 1091 RDK_res12 1091;
BA_ "GenSigTimeoutTime_Gateway_PQ46_A" SG_ 1091 RDK_res12 5000;
BA_ "GenSigTimeoutMsg_Gateway_PQ46_A" SG_ 1091 RDK_res12 1091;
BA_ "GenSigSendType" SG_ 1091 RDK_res12 0;
BA_ "GenSigTimeoutTime_Gateway_PQ35_A" SG_ 1091 RDK_res13 5000;
BA_ "GenSigTimeoutMsg_Gateway_PQ35_A" SG_ 1091 RDK_res13 1091;
BA_ "GenSigTimeoutTime_Gateway_PQ46_A" SG_ 1091 RDK_res13 5000;
BA_ "GenSigTimeoutMsg_Gateway_PQ46_A" SG_ 1091 RDK_res13 1091;
BA_ "GenSigSendType" SG_ 1091 RDK_res13 0;
BA_ "GenSigTimeoutTime_Gateway_PQ35_A" SG_ 1091 RDK_res23 5000;
BA_ "GenSigTimeoutMsg_Gateway_PQ35_A" SG_ 1091 RDK_res23 1091;
BA_ "GenSigTimeoutTime_Gateway_PQ46_A" SG_ 1091 RDK_res23 5000;
BA_ "GenSigTimeoutMsg_Gateway_PQ46_A" SG_ 1091 RDK_res23 1091;
BA_ "GenSigSendType" SG_ 1091 RDK_res23 0;
BA_ "GenSigTimeoutTime_Gateway_PQ35_A" SG_ 1091 RDK_res38 5000;
BA_ "GenSigTimeoutMsg_Gateway_PQ35_A" SG_ 1091 RDK_res38 1091;
BA_ "GenSigTimeoutTime_Gateway_PQ46_A" SG_ 1091 RDK_res38 5000;
BA_ "GenSigTimeoutMsg_Gateway_PQ46_A" SG_ 1091 RDK_res38 1091;
BA_ "GenSigSendType" SG_ 1091 RDK_res38 0;
BA_ "GenSigTimeoutTime_Gateway_PQ35_A" SG_ 1091 RDK_res22 5000;
BA_ "GenSigTimeoutMsg_Gateway_PQ35_A" SG_ 1091 RDK_res22 1091;
BA_ "GenSigTimeoutTime_Gateway_PQ46_A" SG_ 1091 RDK_res22 5000;
BA_ "GenSigTimeoutMsg_Gateway_PQ46_A" SG_ 1091 RDK_res22 1091;
BA_ "GenSigSendType" SG_ 1091 RDK_res22 0;
BA_ "GenSigTimeoutTime_Gateway_PQ35_A" SG_ 1091 RDK_res14 5000;
BA_ "GenSigTimeoutMsg_Gateway_PQ35_A" SG_ 1091 RDK_res14 1091;
BA_ "GenSigTimeoutTime_Gateway_PQ46_A" SG_ 1091 RDK_res14 5000;
BA_ "GenSigTimeoutMsg_Gateway_PQ46_A" SG_ 1091 RDK_res14 1091;
BA_ "GenSigSendType" SG_ 1091 RDK_res14 0;
BA_ "GenSigTimeoutTime_Gateway_PQ35_A" SG_ 1091 RDK_res47 5000;
BA_ "GenSigTimeoutMsg_Gateway_PQ35_A" SG_ 1091 RDK_res47 1091;
BA_ "GenSigTimeoutTime_Gateway_PQ46_A" SG_ 1091 RDK_res47 5000;
BA_ "GenSigTimeoutMsg_Gateway_PQ46_A" SG_ 1091 RDK_res47 1091;
BA_ "GenSigSendType" SG_ 1091 RDK_res47 0;
BA_ "GenSigTimeoutTime_Gateway_PQ46_A" SG_ 1091 RDK_Prio2_Warnung 5000;
BA_ "GenSigTimeoutMsg_Gateway_PQ46_A" SG_ 1091 RDK_Prio2_Warnung 1091;
BA_ "GenSigTimeoutTime_Gateway_PQ35_A" SG_ 1091 RDK_Prio2_Warnung 5000;
BA_ "GenSigTimeoutMsg_Gateway_PQ35_A" SG_ 1091 RDK_Prio2_Warnung 1091;
BA_ "GenSigSendType" SG_ 1091 RDK_Prio2_Warnung 0;
BA_ "GenSigTimeoutTime_Gateway_PQ35_A" SG_ 1091 RDK_res39 5000;
BA_ "GenSigTimeoutMsg_Gateway_PQ35_A" SG_ 1091 RDK_res39 1091;
BA_ "GenSigTimeoutTime_Gateway_PQ46_A" SG_ 1091 RDK_res39 5000;
BA_ "GenSigTimeoutMsg_Gateway_PQ46_A" SG_ 1091 RDK_res39 1091;
BA_ "GenSigSendType" SG_ 1091 RDK_res39 0;
BA_ "GenSigTimeoutTime_Gateway_PQ35_A" SG_ 1091 RDK_Status 5000;
BA_ "GenSigTimeoutMsg_Gateway_PQ35_A" SG_ 1091 RDK_Status 1091;
BA_ "GenSigTimeoutTime_Gateway_PQ46_A" SG_ 1091 RDK_Status 5000;
BA_ "GenSigTimeoutMsg_Gateway_PQ46_A" SG_ 1091 RDK_Status 1091;
BA_ "GenSigSendType" SG_ 1091 RDK_Status 0;
BA_ "GenSigTimeoutTime_Gateway_PQ46_A" SG_ 1091 RDK_Warnungen 5000;
BA_ "GenSigTimeoutMsg_Gateway_PQ46_A" SG_ 1091 RDK_Warnungen 1091;
BA_ "GenSigTimeoutTime_Gateway_PQ35_A" SG_ 1091 RDK_Warnungen 5000;
BA_ "GenSigTimeoutMsg_Gateway_PQ35_A" SG_ 1091 RDK_Warnungen 1091;
BA_ "GenSigSendType" SG_ 1091 RDK_Warnungen 0;
BA_ "GenSigTimeoutTime_Gateway_PQ35_A" SG_ 1091 RDK_xx_Color 5000;
BA_ "GenSigTimeoutMsg_Gateway_PQ35_A" SG_ 1091 RDK_xx_Color 1091;
BA_ "GenSigTimeoutTime_Gateway_PQ46_A" SG_ 1091 RDK_xx_Color 5000;
BA_ "GenSigTimeoutMsg_Gateway_PQ46_A" SG_ 1091 RDK_xx_Color 1091;
BA_ "GenSigSendType" SG_ 1091 RDK_xx_Color 0;
BA_ "GenSigTimeoutTime_Gateway_PQ35_A" SG_ 1091 RDK_xx_Ist_Temp 5000;
BA_ "GenSigTimeoutMsg_Gateway_PQ35_A" SG_ 1091 RDK_xx_Ist_Temp 1091;
BA_ "GenSigTimeoutTime_Gateway_PQ46_A" SG_ 1091 RDK_xx_Ist_Temp 5000;
BA_ "GenSigTimeoutMsg_Gateway_PQ46_A" SG_ 1091 RDK_xx_Ist_Temp 1091;
BA_ "GenSigSendType" SG_ 1091 RDK_xx_Ist_Temp 0;
BA_ "GenSigTimeoutTime_Gateway_PQ35_A" SG_ 1091 RDK_res46 5000;
BA_ "GenSigTimeoutMsg_Gateway_PQ35_A" SG_ 1091 RDK_res46 1091;
BA_ "GenSigTimeoutTime_Gateway_PQ46_A" SG_ 1091 RDK_res46 5000;
BA_ "GenSigTimeoutMsg_Gateway_PQ46_A" SG_ 1091 RDK_res46 1091;
BA_ "GenSigSendType" SG_ 1091 RDK_res46 0;
BA_ "GenSigTimeoutTime_Gateway_PQ35_A" SG_ 1091 RDK_xx_Soll_Druck 5000;
BA_ "GenSigTimeoutMsg_Gateway_PQ35_A" SG_ 1091 RDK_xx_Soll_Druck 1091;
BA_ "GenSigTimeoutTime_Gateway_PQ46_A" SG_ 1091 RDK_xx_Soll_Druck 5000;
BA_ "GenSigTimeoutMsg_Gateway_PQ46_A" SG_ 1091 RDK_xx_Soll_Druck 1091;
BA_ "GenSigSendType" SG_ 1091 RDK_xx_Soll_Druck 0;
BA_ "GenSigTimeoutTime_Gateway_PQ35_A" SG_ 1091 RDK_xx_Status_Sensor 5000;
BA_ "GenSigTimeoutMsg_Gateway_PQ35_A" SG_ 1091 RDK_xx_Status_Sensor 1091;
BA_ "GenSigTimeoutTime_Gateway_PQ46_A" SG_ 1091 RDK_xx_Status_Sensor 5000;
BA_ "GenSigTimeoutMsg_Gateway_PQ46_A" SG_ 1091 RDK_xx_Status_Sensor 1091;
BA_ "GenSigSendType" SG_ 1091 RDK_xx_Status_Sensor 0;
BA_ "GenSigTimeoutTime_Gateway_PQ35_A" SG_ 1091 RDK_Sensor_Multiplex 5000;
BA_ "GenSigTimeoutMsg_Gateway_PQ35_A" SG_ 1091 RDK_Sensor_Multiplex 1091;
BA_ "GenSigTimeoutTime_Gateway_PQ46_A" SG_ 1091 RDK_Sensor_Multiplex 5000;
BA_ "GenSigTimeoutMsg_Gateway_PQ46_A" SG_ 1091 RDK_Sensor_Multiplex 1091;
BA_ "GenSigSendType" SG_ 1091 RDK_Sensor_Multiplex 0;
BA_ "GenSigTimeoutTime_Gateway_PQ35_A" SG_ 1091 RDK_xx_Ist_Druck 5000;
BA_ "GenSigTimeoutMsg_Gateway_PQ35_A" SG_ 1091 RDK_xx_Ist_Druck 1091;
BA_ "GenSigTimeoutTime_Gateway_PQ46_A" SG_ 1091 RDK_xx_Ist_Druck 5000;
BA_ "GenSigTimeoutMsg_Gateway_PQ46_A" SG_ 1091 RDK_xx_Ist_Druck 1091;
BA_ "GenSigSendType" SG_ 1091 RDK_xx_Ist_Druck 0;
BA_ "GenSigTimeoutTime_Gateway_PQ46_A" SG_ 1091 RDK_FMVSS_138_MIL 5000;
BA_ "GenSigTimeoutMsg_Gateway_PQ46_A" SG_ 1091 RDK_FMVSS_138_MIL 1091;
BA_ "GenSigTimeoutTime_Gateway_PQ35_A" SG_ 1091 RDK_FMVSS_138_MIL 5000;
BA_ "GenSigTimeoutMsg_Gateway_PQ35_A" SG_ 1091 RDK_FMVSS_138_MIL 1091;
BA_ "GenSigSendType" SG_ 1091 RDK_FMVSS_138_MIL 0;
BA_ "GenSigTimeoutMsg_Gateway_PQ35_A" SG_ 514 Getriebe_TP_Er 514;
BA_ "GenSigTimeoutMsg_Gateway_PQ46_A" SG_ 514 Getriebe_TP_Er 514;
BA_ "GenSigSendType" SG_ 514 Getriebe_TP_Er 5;
BA_ "GenSigTimeoutTime_Hybrid_MSG" SG_ 1344 GE2_Sta_ZwGas 500;
BA_ "GenSigTimeoutMsg_Hybrid_MSG" SG_ 1344 GE2_Sta_ZwGas 1344;
BA_ "GenSigTimeoutTime_Gateway_PQ35_A" SG_ 1344 GE2_Sta_ZwGas 500;
BA_ "GenSigTimeoutMsg_Gateway_PQ35_A" SG_ 1344 GE2_Sta_ZwGas 1344;
BA_ "GenSigTimeoutTime_Otto" SG_ 1344 GE2_Sta_ZwGas 500;
BA_ "GenSigTimeoutMsg_Otto" SG_ 1344 GE2_Sta_ZwGas 1344;
BA_ "GenSigTimeoutTime_Diesel" SG_ 1344 GE2_Sta_ZwGas 500;
BA_ "GenSigTimeoutMsg_Diesel" SG_ 1344 GE2_Sta_ZwGas 1344;
BA_ "GenSigTimeoutTime_Gateway_PQ46_A" SG_ 1344 GE2_Sta_ZwGas 500;
BA_ "GenSigTimeoutMsg_Gateway_PQ46_A" SG_ 1344 GE2_Sta_ZwGas 1344;
BA_ "GenSigSendType" SG_ 1344 GE2_Sta_ZwGas 0;
BA_ "GenSigTimeoutTime_Gateway_PQ35_A" SG_ 1344 GE2_Sta_SAS 500;
BA_ "GenSigTimeoutMsg_Gateway_PQ35_A" SG_ 1344 GE2_Sta_SAS 1344;
BA_ "GenSigTimeoutTime_Otto" SG_ 1344 GE2_Sta_SAS 500;
BA_ "GenSigTimeoutMsg_Otto" SG_ 1344 GE2_Sta_SAS 1344;
BA_ "GenSigTimeoutTime_Gateway_PQ46_A" SG_ 1344 GE2_Sta_SAS 500;
BA_ "GenSigTimeoutMsg_Gateway_PQ46_A" SG_ 1344 GE2_Sta_SAS 1344;
BA_ "GenSigSendType" SG_ 1344 GE2_Sta_SAS 0;
BA_ "GenSigTimeoutTime_Hybrid_MSG" SG_ 1344 GE2_SlipStDZEingr 500;
BA_ "GenSigTimeoutMsg_Hybrid_MSG" SG_ 1344 GE2_SlipStDZEingr 1344;
BA_ "GenSigTimeoutTime_Gateway_PQ35_A" SG_ 1344 GE2_SlipStDZEingr 500;
BA_ "GenSigTimeoutMsg_Gateway_PQ35_A" SG_ 1344 GE2_SlipStDZEingr 1344;
BA_ "GenSigTimeoutTime_Gateway_PQ46_A" SG_ 1344 GE2_SlipStDZEingr 500;
BA_ "GenSigTimeoutMsg_Gateway_PQ46_A" SG_ 1344 GE2_SlipStDZEingr 1344;
BA_ "GenSigSendType" SG_ 1344 GE2_SlipStDZEingr 0;
BA_ "GenSigTimeoutTime_Hybrid_MSG" SG_ 1344 GE2_LFR_Adap 500;
BA_ "GenSigTimeoutMsg_Hybrid_MSG" SG_ 1344 GE2_LFR_Adap 1344;
BA_ "GenSigTimeoutTime_Gateway_PQ35_A" SG_ 1344 GE2_LFR_Adap 500;
BA_ "GenSigTimeoutMsg_Gateway_PQ35_A" SG_ 1344 GE2_LFR_Adap 1344;
BA_ "GenSigTimeoutTime_Otto" SG_ 1344 GE2_LFR_Adap 500;
BA_ "GenSigTimeoutMsg_Otto" SG_ 1344 GE2_LFR_Adap 1344;
BA_ "GenSigTimeoutTime_Diesel" SG_ 1344 GE2_LFR_Adap 500;
BA_ "GenSigTimeoutMsg_Diesel" SG_ 1344 GE2_LFR_Adap 1344;
BA_ "GenSigTimeoutTime_Gateway_PQ46_A" SG_ 1344 GE2_LFR_Adap 500;
BA_ "GenSigTimeoutMsg_Gateway_PQ46_A" SG_ 1344 GE2_LFR_Adap 1344;
BA_ "GenSigSendType" SG_ 1344 GE2_LFR_Adap 0;
BA_ "GenSigTimeoutTime_Hybrid_MSG" SG_ 1344 GE2_Zaehler 500;
BA_ "GenSigTimeoutMsg_Hybrid_MSG" SG_ 1344 GE2_Zaehler 1344;
BA_ "GenSigTimeoutTime_Gateway_PQ35_A" SG_ 1344 GE2_Zaehler 500;
BA_ "GenSigTimeoutMsg_Gateway_PQ35_A" SG_ 1344 GE2_Zaehler 1344;
BA_ "GenSigTimeoutTime_Otto" SG_ 1344 GE2_Zaehler 500;
BA_ "GenSigTimeoutMsg_Otto" SG_ 1344 GE2_Zaehler 1344;
BA_ "GenSigTimeoutTime_Diesel" SG_ 1344 GE2_Zaehler 500;
BA_ "GenSigTimeoutMsg_Diesel" SG_ 1344 GE2_Zaehler 1344;
BA_ "GenSigTimeoutTime_Gateway_PQ46_A" SG_ 1344 GE2_Zaehler 500;
BA_ "GenSigTimeoutMsg_Gateway_PQ46_A" SG_ 1344 GE2_Zaehler 1344;
BA_ "GenSigSendType" SG_ 1344 GE2_Zaehler 0;
BA_ "GenSigTimeoutTime_Hybrid_MSG" SG_ 1344 GE2_Grad_begr 500;
BA_ "GenSigTimeoutMsg_Hybrid_MSG" SG_ 1344 GE2_Grad_begr 1344;
BA_ "GenSigTimeoutTime_Gateway_PQ35_A" SG_ 1344 GE2_Grad_begr 500;
BA_ "GenSigTimeoutMsg_Gateway_PQ35_A" SG_ 1344 GE2_Grad_begr 1344;
BA_ "GenSigTimeoutTime_Otto" SG_ 1344 GE2_Grad_begr 500;
BA_ "GenSigTimeoutMsg_Otto" SG_ 1344 GE2_Grad_begr 1344;
BA_ "GenSigTimeoutTime_Diesel" SG_ 1344 GE2_Grad_begr 500;
BA_ "GenSigTimeoutMsg_Diesel" SG_ 1344 GE2_Grad_begr 1344;
BA_ "GenSigTimeoutTime_Gateway_PQ46_A" SG_ 1344 GE2_Grad_begr 500;
BA_ "GenSigTimeoutMsg_Gateway_PQ46_A" SG_ 1344 GE2_Grad_begr 1344;
BA_ "GenSigSendType" SG_ 1344 GE2_Grad_begr 0;
BA_ "GenSigStartValue" SG_ 1344 GE2_Grad_begr 255;
BA_ "GenSigTimeoutTime_Hybrid_MSG" SG_ 1344 GE2_LL_Solldz 500;
BA_ "GenSigTimeoutMsg_Hybrid_MSG" SG_ 1344 GE2_LL_Solldz 1344;
BA_ "GenSigTimeoutTime_Gateway_PQ35_A" SG_ 1344 GE2_LL_Solldz 500;
BA_ "GenSigTimeoutMsg_Gateway_PQ35_A" SG_ 1344 GE2_LL_Solldz 1344;
BA_ "GenSigTimeoutTime_Otto" SG_ 1344 GE2_LL_Solldz 500;
BA_ "GenSigTimeoutMsg_Otto" SG_ 1344 GE2_LL_Solldz 1344;
BA_ "GenSigTimeoutTime_Diesel" SG_ 1344 GE2_LL_Solldz 500;
BA_ "GenSigTimeoutMsg_Diesel" SG_ 1344 GE2_LL_Solldz 1344;
BA_ "GenSigTimeoutTime_Gateway_PQ46_A" SG_ 1344 GE2_LL_Solldz 500;
BA_ "GenSigTimeoutMsg_Gateway_PQ46_A" SG_ 1344 GE2_LL_Solldz 1344;
BA_ "GenSigSendType" SG_ 1344 GE2_LL_Solldz 0;
BA_ "GenSigTimeoutTime_Hybrid_MSG" SG_ 1344 GE2_Sync_Zeit 500;
BA_ "GenSigTimeoutMsg_Hybrid_MSG" SG_ 1344 GE2_Sync_Zeit 1344;
BA_ "GenSigTimeoutTime_Gateway_PQ35_A" SG_ 1344 GE2_Sync_Zeit 500;
BA_ "GenSigTimeoutMsg_Gateway_PQ35_A" SG_ 1344 GE2_Sync_Zeit 1344;
BA_ "GenSigTimeoutTime_Otto" SG_ 1344 GE2_Sync_Zeit 500;
BA_ "GenSigTimeoutMsg_Otto" SG_ 1344 GE2_Sync_Zeit 1344;
BA_ "GenSigTimeoutTime_Diesel" SG_ 1344 GE2_Sync_Zeit 500;
BA_ "GenSigTimeoutMsg_Diesel" SG_ 1344 GE2_Sync_Zeit 1344;
BA_ "GenSigTimeoutTime_Gateway_PQ46_A" SG_ 1344 GE2_Sync_Zeit 500;
BA_ "GenSigTimeoutMsg_Gateway_PQ46_A" SG_ 1344 GE2_Sync_Zeit 1344;
BA_ "GenSigSendType" SG_ 1344 GE2_Sync_Zeit 0;
BA_ "GenSigTimeoutTime_Gateway_PQ35_A" SG_ 1344 GE2_DZM_Daempf 500;
BA_ "GenSigTimeoutMsg_Gateway_PQ35_A" SG_ 1344 GE2_DZM_Daempf 1344;
BA_ "GenSigTimeoutTime_Gateway_PQ46_A" SG_ 1344 GE2_DZM_Daempf 500;
BA_ "GenSigTimeoutMsg_Gateway_PQ46_A" SG_ 1344 GE2_DZM_Daempf 1344;
BA_ "GenSigSendType" SG_ 1344 GE2_DZM_Daempf 0;
BA_ "GenSigTimeoutTime_Gateway_PQ35_A" SG_ 1344 GE2_Fehlertext_Freigabe 500;
BA_ "GenSigTimeoutMsg_Gateway_PQ35_A" SG_ 1344 GE2_Fehlertext_Freigabe 1344;
BA_ "GenSigTimeoutTime_Gateway_PQ46_A" SG_ 1344 GE2_Fehlertext_Freigabe 500;
BA_ "GenSigTimeoutMsg_Gateway_PQ46_A" SG_ 1344 GE2_Fehlertext_Freigabe 1344;
BA_ "GenSigSendType" SG_ 1344 GE2_Fehlertext_Freigabe 0;
BA_ "GenSigTimeoutTime_Gateway_PQ35_A" SG_ 1344 GE2_Gong 500;
BA_ "GenSigTimeoutMsg_Gateway_PQ35_A" SG_ 1344 GE2_Gong 1344;
BA_ "GenSigTimeoutTime_Gateway_PQ46_A" SG_ 1344 GE2_Gong 500;
BA_ "GenSigTimeoutMsg_Gateway_PQ46_A" SG_ 1344 GE2_Gong 1344;
BA_ "GenSigSendType" SG_ 1344 GE2_Gong 0;
BA_ "GenSigTimeoutTime_Gateway_PQ35_A" SG_ 1344 GE2_Senderkennung 500;
BA_ "GenSigTimeoutMsg_Gateway_PQ35_A" SG_ 1344 GE2_Senderkennung 1344;
BA_ "GenSigTimeoutTime_Gateway_PQ46_A" SG_ 1344 GE2_Senderkennung 500;
BA_ "GenSigTimeoutMsg_Gateway_PQ46_A" SG_ 1344 GE2_Senderkennung 1344;
BA_ "GenSigSendType" SG_ 1344 GE2_Senderkennung 0;
BA_ "INIT" SG_ 1344 GE2_Senderkennung "const";
BA_ "GenSigTimeoutTime_Gateway_PQ35_A" SG_ 1344 GE2_Shift_Lock 500;
BA_ "GenSigTimeoutMsg_Gateway_PQ35_A" SG_ 1344 GE2_Shift_Lock 1344;
BA_ "GenSigTimeoutTime_Gateway_PQ46_A" SG_ 1344 GE2_Shift_Lock 500;
BA_ "GenSigTimeoutMsg_Gateway_PQ46_A" SG_ 1344 GE2_Shift_Lock 1344;
BA_ "GenSigSendType" SG_ 1344 GE2_Shift_Lock 0;
BA_ "GenSigTimeoutTime_Waehlhebel_Sel" SG_ 1344 GE2_Variante 500;
BA_ "GenSigTimeoutMsg_Waehlhebel_Sel" SG_ 1344 GE2_Variante 1344;
BA_ "GenSigTimeoutTime_Gateway_PQ35_A" SG_ 1344 GE2_Variante 500;
BA_ "GenSigTimeoutMsg_Gateway_PQ35_A" SG_ 1344 GE2_Variante 1344;
BA_ "GenSigTimeoutTime_Gateway_PQ46_A" SG_ 1344 GE2_Variante 500;
BA_ "GenSigTimeoutMsg_Gateway_PQ46_A" SG_ 1344 GE2_Variante 1344;
BA_ "GenSigSendType" SG_ 1344 GE2_Variante 0;
BA_ "GenSigTimeoutTime_Hybrid_MSG" SG_ 1344 GE2_Sync_Dz 500;
BA_ "GenSigTimeoutMsg_Hybrid_MSG" SG_ 1344 GE2_Sync_Dz 1344;
BA_ "GenSigTimeoutTime_Gateway_PQ35_A" SG_ 1344 GE2_Sync_Dz 500;
BA_ "GenSigTimeoutMsg_Gateway_PQ35_A" SG_ 1344 GE2_Sync_Dz 1344;
BA_ "GenSigTimeoutTime_Otto" SG_ 1344 GE2_Sync_Dz 500;
BA_ "GenSigTimeoutMsg_Otto" SG_ 1344 GE2_Sync_Dz 1344;
BA_ "GenSigTimeoutTime_Diesel" SG_ 1344 GE2_Sync_Dz 500;
BA_ "GenSigTimeoutMsg_Diesel" SG_ 1344 GE2_Sync_Dz 1344;
BA_ "GenSigTimeoutTime_Gateway_PQ46_A" SG_ 1344 GE2_Sync_Dz 500;
BA_ "GenSigTimeoutMsg_Gateway_PQ46_A" SG_ 1344 GE2_Sync_Dz 1344;
BA_ "GenSigSendType" SG_ 1344 GE2_Sync_Dz 0;
BA_ "GenSigTimeoutTime_Otto" SG_ 1344 GE2_invMSB_Sync 500;
BA_ "GenSigTimeoutMsg_Otto" SG_ 1344 GE2_invMSB_Sync 1344;
BA_ "GenSigTimeoutTime_Diesel" SG_ 1344 GE2_invMSB_Sync 500;
BA_ "GenSigTimeoutMsg_Diesel" SG_ 1344 GE2_invMSB_Sync 1344;
BA_ "GenSigTimeoutTime_Gateway_PQ35_A" SG_ 1344 GE2_invMSB_Sync 500;
BA_ "GenSigTimeoutMsg_Gateway_PQ35_A" SG_ 1344 GE2_invMSB_Sync 1344;
BA_ "GenSigTimeoutTime_Gateway_PQ46_A" SG_ 1344 GE2_invMSB_Sync 500;
BA_ "GenSigTimeoutMsg_Gateway_PQ46_A" SG_ 1344 GE2_invMSB_Sync 1344;
BA_ "GenSigSendType" SG_ 1344 GE2_invMSB_Sync 0;
BA_ "GenSigStartValue" SG_ 1344 GE2_invMSB_Sync 1;
BA_ "GenSigTimeoutTime_Hybrid_MSG" SG_ 1344 GE2_WBA_Blinken 500;
BA_ "GenSigTimeoutMsg_Hybrid_MSG" SG_ 1344 GE2_WBA_Blinken 1344;
BA_ "GenSigTimeoutTime_Gateway_PQ35_A" SG_ 1344 GE2_WBA_Blinken 500;
BA_ "GenSigTimeoutMsg_Gateway_PQ35_A" SG_ 1344 GE2_WBA_Blinken 1344;
BA_ "GenSigTimeoutTime_Otto" SG_ 1344 GE2_WBA_Blinken 500;
BA_ "GenSigTimeoutMsg_Otto" SG_ 1344 GE2_WBA_Blinken 1344;
BA_ "GenSigTimeoutTime_Diesel" SG_ 1344 GE2_WBA_Blinken 500;
BA_ "GenSigTimeoutMsg_Diesel" SG_ 1344 GE2_WBA_Blinken 1344;
BA_ "GenSigTimeoutTime_Gateway_PQ46_A" SG_ 1344 GE2_WBA_Blinken 500;
BA_ "GenSigTimeoutMsg_Gateway_PQ46_A" SG_ 1344 GE2_WBA_Blinken 1344;
BA_ "GenSigSendType" SG_ 1344 GE2_WBA_Blinken 0;
BA_ "GenSigTimeoutTime_Diesel" SG_ 1344 GE2_MSB_Sync 500;
BA_ "GenSigTimeoutMsg_Diesel" SG_ 1344 GE2_MSB_Sync 1344;
BA_ "GenSigTimeoutTime_Otto" SG_ 1344 GE2_MSB_Sync 500;
BA_ "GenSigTimeoutMsg_Otto" SG_ 1344 GE2_MSB_Sync 1344;
BA_ "GenSigTimeoutTime_Gateway_PQ35_A" SG_ 1344 GE2_MSB_Sync 500;
BA_ "GenSigTimeoutMsg_Gateway_PQ35_A" SG_ 1344 GE2_MSB_Sync 1344;
BA_ "GenSigTimeoutTime_Gateway_PQ46_A" SG_ 1344 GE2_MSB_Sync 500;
BA_ "GenSigTimeoutMsg_Gateway_PQ46_A" SG_ 1344 GE2_MSB_Sync 1344;
BA_ "GenSigSendType" SG_ 1344 GE2_MSB_Sync 0;
BA_ "GenSigTimeoutTime_Gateway_PQ35_A" SG_ 1344 GE2_5Gang 500;
BA_ "GenSigTimeoutMsg_Gateway_PQ35_A" SG_ 1344 GE2_5Gang 1344;
BA_ "GenSigTimeoutTime_Gateway_PQ46_A" SG_ 1344 GE2_5Gang 500;
BA_ "GenSigTimeoutMsg_Gateway_PQ46_A" SG_ 1344 GE2_5Gang 1344;
BA_ "GenSigSendType" SG_ 1344 GE2_5Gang 0;
BA_ "GenSigTimeoutTime_Hybrid_MSG" SG_ 1344 GE2_invSync_Dz 500;
BA_ "GenSigTimeoutMsg_Hybrid_MSG" SG_ 1344 GE2_invSync_Dz 1344;
BA_ "GenSigTimeoutTime_Gateway_PQ35_A" SG_ 1344 GE2_invSync_Dz 500;
BA_ "GenSigTimeoutMsg_Gateway_PQ35_A" SG_ 1344 GE2_invSync_Dz 1344;
BA_ "GenSigTimeoutTime_Otto" SG_ 1344 GE2_invSync_Dz 500;
BA_ "GenSigTimeoutMsg_Otto" SG_ 1344 GE2_invSync_Dz 1344;
BA_ "GenSigTimeoutTime_Diesel" SG_ 1344 GE2_invSync_Dz 500;
BA_ "GenSigTimeoutMsg_Diesel" SG_ 1344 GE2_invSync_Dz 1344;
BA_ "GenSigTimeoutTime_Gateway_PQ46_A" SG_ 1344 GE2_invSync_Dz 500;
BA_ "GenSigTimeoutMsg_Gateway_PQ46_A" SG_ 1344 GE2_invSync_Dz 1344;
BA_ "GenSigSendType" SG_ 1344 GE2_invSync_Dz 0;
BA_ "GenSigStartValue" SG_ 1344 GE2_invSync_Dz 255;
BA_ "GenSigTimeoutTime_Gateway_PQ35_A" SG_ 1344 GE2_PRND 500;
BA_ "GenSigTimeoutMsg_Gateway_PQ35_A" SG_ 1344 GE2_PRND 1344;
BA_ "GenSigTimeoutTime_Gateway_PQ46_A" SG_ 1344 GE2_PRND 500;
BA_ "GenSigTimeoutMsg_Gateway_PQ46_A" SG_ 1344 GE2_PRND 1344;
BA_ "GenSigSendType" SG_ 1344 GE2_PRND 0;
BA_ "GenSigTimeoutTime_Gateway_PQ35_A" SG_ 1344 GE2_4Gang 500;
BA_ "GenSigTimeoutMsg_Gateway_PQ35_A" SG_ 1344 GE2_4Gang 1344;
BA_ "GenSigTimeoutTime_Gateway_PQ46_A" SG_ 1344 GE2_4Gang 500;
BA_ "GenSigTimeoutMsg_Gateway_PQ46_A" SG_ 1344 GE2_4Gang 1344;
BA_ "GenSigSendType" SG_ 1344 GE2_4Gang 0;
BA_ "GenSigTimeoutTime_Gateway_PQ35_A" SG_ 1344 GE2_Tip4Gang 500;
BA_ "GenSigTimeoutMsg_Gateway_PQ35_A" SG_ 1344 GE2_Tip4Gang 1344;
BA_ "GenSigTimeoutTime_Gateway_PQ46_A" SG_ 1344 GE2_Tip4Gang 500;
BA_ "GenSigTimeoutMsg_Gateway_PQ46_A" SG_ 1344 GE2_Tip4Gang 1344;
BA_ "GenSigSendType" SG_ 1344 GE2_Tip4Gang 0;
BA_ "GenSigTimeoutTime_Waehlhebel_Sel" SG_ 1344 GE2_akt_Gang 500;
BA_ "GenSigTimeoutMsg_Waehlhebel_Sel" SG_ 1344 GE2_akt_Gang 1344;
BA_ "GenSigTimeoutTime_Gateway_PQ35_A" SG_ 1344 GE2_akt_Gang 500;
BA_ "GenSigTimeoutMsg_Gateway_PQ35_A" SG_ 1344 GE2_akt_Gang 1344;
BA_ "GenSigTimeoutTime_Gateway_PQ46_A" SG_ 1344 GE2_akt_Gang 500;
BA_ "GenSigTimeoutMsg_Gateway_PQ46_A" SG_ 1344 GE2_akt_Gang 1344;
BA_ "GenSigSendType" SG_ 1344 GE2_akt_Gang 0;
BA_ "GenSigTimeoutTime_Gateway_PQ35_A" SG_ 1344 GE2_Tip6Gang 500;
BA_ "GenSigTimeoutMsg_Gateway_PQ35_A" SG_ 1344 GE2_Tip6Gang 1344;
BA_ "GenSigTimeoutTime_Gateway_PQ46_A" SG_ 1344 GE2_Tip6Gang 500;
BA_ "GenSigTimeoutMsg_Gateway_PQ46_A" SG_ 1344 GE2_Tip6Gang 1344;
BA_ "GenSigSendType" SG_ 1344 GE2_Tip6Gang 0;
BA_ "GenSigTimeoutTime_Gateway_PQ35_A" SG_ 1344 GE2_ASG 500;
BA_ "GenSigTimeoutMsg_Gateway_PQ35_A" SG_ 1344 GE2_ASG 1344;
BA_ "GenSigTimeoutTime_Gateway_PQ46_A" SG_ 1344 GE2_ASG 500;
BA_ "GenSigTimeoutMsg_Gateway_PQ46_A" SG_ 1344 GE2_ASG 1344;
BA_ "GenSigSendType" SG_ 1344 GE2_ASG 0;
BA_ "GenSigTimeoutTime_Gateway_PQ35_A" SG_ 1344 GE2_PRNDS 500;
BA_ "GenSigTimeoutMsg_Gateway_PQ35_A" SG_ 1344 GE2_PRNDS 1344;
BA_ "GenSigTimeoutTime_Gateway_PQ46_A" SG_ 1344 GE2_PRNDS 500;
BA_ "GenSigTimeoutMsg_Gateway_PQ46_A" SG_ 1344 GE2_PRNDS 1344;
BA_ "GenSigSendType" SG_ 1344 GE2_PRNDS 0;
BA_ "GenSigTimeoutTime_Gateway_PQ35_A" SG_ 1344 GE2_Tip7Gang 500;
BA_ "GenSigTimeoutMsg_Gateway_PQ35_A" SG_ 1344 GE2_Tip7Gang 1344;
BA_ "GenSigTimeoutTime_Gateway_PQ46_A" SG_ 1344 GE2_Tip7Gang 500;
BA_ "GenSigTimeoutMsg_Gateway_PQ46_A" SG_ 1344 GE2_Tip7Gang 1344;
BA_ "GenSigSendType" SG_ 1344 GE2_Tip7Gang 0;
BA_ "GenSigTimeoutTime_Waehlhebel_Sel" SG_ 1344 GE2_Selespeed 500;
BA_ "GenSigTimeoutMsg_Waehlhebel_Sel" SG_ 1344 GE2_Selespeed 1344;
BA_ "GenSigTimeoutTime_Gateway_PQ35_A" SG_ 1344 GE2_Selespeed 500;
BA_ "GenSigTimeoutMsg_Gateway_PQ35_A" SG_ 1344 GE2_Selespeed 1344;
BA_ "GenSigTimeoutTime_Gateway_PQ46_A" SG_ 1344 GE2_Selespeed 500;
BA_ "GenSigTimeoutMsg_Gateway_PQ46_A" SG_ 1344 GE2_Selespeed 1344;
BA_ "GenSigSendType" SG_ 1344 GE2_Selespeed 0;
BA_ "GenSigTimeoutTime_Gateway_PQ35_A" SG_ 1344 GE2_Tip5Gang 500;
BA_ "GenSigTimeoutMsg_Gateway_PQ35_A" SG_ 1344 GE2_Tip5Gang 1344;
BA_ "GenSigTimeoutTime_Gateway_PQ46_A" SG_ 1344 GE2_Tip5Gang 500;
BA_ "GenSigTimeoutMsg_Gateway_PQ46_A" SG_ 1344 GE2_Tip5Gang 1344;
BA_ "GenSigSendType" SG_ 1344 GE2_Tip5Gang 0;
BA_ "GenSigTimeoutTime_Waehlhebel_Sel" SG_ 1346 GE5_Ausl_Winter 500;
BA_ "GenSigTimeoutMsg_Waehlhebel_Sel" SG_ 1346 GE5_Ausl_Winter 1346;
BA_ "GenSigSendType" SG_ 1346 GE5_Ausl_Winter 0;
BA_ "GenSigTimeoutTime_Waehlhebel_Sel" SG_ 1346 GE5_Test 500;
BA_ "GenSigTimeoutMsg_Waehlhebel_Sel" SG_ 1346 GE5_Test 1346;
BA_ "GenSigSendType" SG_ 1346 GE5_Test 0;
BA_ "GenSigTimeoutTime_Waehlhebel_Sel" SG_ 1346 GE5_Testparam_1 500;
BA_ "GenSigTimeoutMsg_Waehlhebel_Sel" SG_ 1346 GE5_Testparam_1 1346;
BA_ "GenSigSendType" SG_ 1346 GE5_Testparam_1 0;
BA_ "GenSigTimeoutTime_Waehlhebel_Sel" SG_ 1346 GE5_Ausleuchtung 500;
BA_ "GenSigTimeoutMsg_Waehlhebel_Sel" SG_ 1346 GE5_Ausleuchtung 1346;
BA_ "GenSigSendType" SG_ 1346 GE5_Ausleuchtung 0;
BA_ "GenSigTimeoutTime_Waehlhebel_Sel" SG_ 1346 GE5_Ausl_Sport 500;
BA_ "GenSigTimeoutMsg_Waehlhebel_Sel" SG_ 1346 GE5_Ausl_Sport 1346;
BA_ "GenSigSendType" SG_ 1346 GE5_Ausl_Sport 0;
BA_ "GenSigTimeoutTime_Waehlhebel_Sel" SG_ 1346 GE5_Abschalten 500;
BA_ "GenSigTimeoutMsg_Waehlhebel_Sel" SG_ 1346 GE5_Abschalten 1346;
BA_ "GenSigSendType" SG_ 1346 GE5_Abschalten 0;
BA_ "GenSigTimeoutTime_Waehlhebel_Sel" SG_ 1346 GE5_Sta_Fahrstufe 500;
BA_ "GenSigTimeoutMsg_Waehlhebel_Sel" SG_ 1346 GE5_Sta_Fahrstufe 1346;
BA_ "GenSigSendType" SG_ 1346 GE5_Sta_Fahrstufe 0;
BA_ "GenSigSendType" SG_ 1346 GE5_res_07 0;
BA_ "GenSigTimeoutTime_Waehlhebel_Sel" SG_ 1346 GE5_Testparam_2 500;
BA_ "GenSigTimeoutMsg_Waehlhebel_Sel" SG_ 1346 GE5_Testparam_2 1346;
BA_ "GenSigSendType" SG_ 1346 GE5_Testparam_2 0;
BA_ "GenSigTimeoutTime_Gateway_PQ35_A" SG_ 1348 GE7_Text_01 1000;
BA_ "GenSigTimeoutMsg_Gateway_PQ35_A" SG_ 1348 GE7_Text_01 1348;
BA_ "GenSigSendType" SG_ 1348 GE7_Text_01 0;
BA_ "GenSigTimeoutTime_Gateway_PQ35_A" SG_ 1348 GE7_Text_04 1000;
BA_ "GenSigTimeoutMsg_Gateway_PQ35_A" SG_ 1348 GE7_Text_04 1348;
BA_ "GenSigSendType" SG_ 1348 GE7_Text_04 0;
BA_ "GenSigTimeoutTime_Gateway_PQ35_A" SG_ 1348 GE7_Text_05 1000;
BA_ "GenSigTimeoutMsg_Gateway_PQ35_A" SG_ 1348 GE7_Text_05 1348;
BA_ "GenSigSendType" SG_ 1348 GE7_Text_05 0;
BA_ "GenSigTimeoutTime_Gateway_PQ35_A" SG_ 1348 GE7_Text_03 1000;
BA_ "GenSigTimeoutMsg_Gateway_PQ35_A" SG_ 1348 GE7_Text_03 1348;
BA_ "GenSigSendType" SG_ 1348 GE7_Text_03 0;
BA_ "GenSigTimeoutTime_Gateway_PQ35_A" SG_ 1348 GE7_Gong 1000;
BA_ "GenSigTimeoutMsg_Gateway_PQ35_A" SG_ 1348 GE7_Gong 1348;
BA_ "GenSigSendType" SG_ 1348 GE7_Gong 0;
BA_ "GenSigTimeoutTime_Gateway_PQ35_A" SG_ 1348 GE7_Text_02 1000;
BA_ "GenSigTimeoutMsg_Gateway_PQ35_A" SG_ 1348 GE7_Text_02 1348;
BA_ "GenSigSendType" SG_ 1348 GE7_Text_02 0;
BA_ "GenSigTimeoutTime_Gateway_PQ35_A" SG_ 1348 GE7_res_11 1000;
BA_ "GenSigTimeoutMsg_Gateway_PQ35_A" SG_ 1348 GE7_res_11 1348;
BA_ "GenSigSendType" SG_ 1348 GE7_res_11 0;
BA_ "GenSigTimeoutTime_Gateway_PQ35_A" SG_ 1348 GE7_res_12 1000;
BA_ "GenSigTimeoutMsg_Gateway_PQ35_A" SG_ 1348 GE7_res_12 1348;
BA_ "GenSigSendType" SG_ 1348 GE7_res_12 0;
BA_ "GenSigTimeoutTime_Gateway_PQ35_A" SG_ 1348 GE7_res_15 1000;
BA_ "GenSigTimeoutMsg_Gateway_PQ35_A" SG_ 1348 GE7_res_15 1348;
BA_ "GenSigSendType" SG_ 1348 GE7_res_15 0;
BA_ "GenSigTimeoutTime_Gateway_PQ35_A" SG_ 1348 GE7_res_13 1000;
BA_ "GenSigTimeoutMsg_Gateway_PQ35_A" SG_ 1348 GE7_res_13 1348;
BA_ "GenSigSendType" SG_ 1348 GE7_res_13 0;
BA_ "GenSigTimeoutTime_Gateway_PQ35_A" SG_ 1348 GE7_res_17 1000;
BA_ "GenSigTimeoutMsg_Gateway_PQ35_A" SG_ 1348 GE7_res_17 1348;
BA_ "GenSigSendType" SG_ 1348 GE7_res_17 0;
BA_ "GenSigTimeoutTime_Gateway_PQ35_A" SG_ 1348 GE7_res_18 1000;
BA_ "GenSigTimeoutMsg_Gateway_PQ35_A" SG_ 1348 GE7_res_18 1348;
BA_ "GenSigSendType" SG_ 1348 GE7_res_18 0;
BA_ "GenSigTimeoutTime_Gateway_PQ35_A" SG_ 1348 GE7_res_16 1000;
BA_ "GenSigTimeoutMsg_Gateway_PQ35_A" SG_ 1348 GE7_res_16 1348;
BA_ "GenSigSendType" SG_ 1348 GE7_res_16 0;
BA_ "GenSigTimeoutTime_Gateway_PQ35_A" SG_ 1348 GE7_res_19 1000;
BA_ "GenSigTimeoutMsg_Gateway_PQ35_A" SG_ 1348 GE7_res_19 1348;
BA_ "GenSigSendType" SG_ 1348 GE7_res_19 0;
BA_ "GenSigTimeoutTime_Gateway_PQ35_A" SG_ 1348 GE7_res_20 1000;
BA_ "GenSigTimeoutMsg_Gateway_PQ35_A" SG_ 1348 GE7_res_20 1348;
BA_ "GenSigSendType" SG_ 1348 GE7_res_20 0;
BA_ "GenSigTimeoutTime_Gateway_PQ35_A" SG_ 1348 GE7_res_14 1000;
BA_ "GenSigTimeoutMsg_Gateway_PQ35_A" SG_ 1348 GE7_res_14 1348;
BA_ "GenSigSendType" SG_ 1348 GE7_res_14 0;
BA_ "GenSigTimeoutTime_Gateway_PQ35_A" SG_ 1348 GE7_res_21 1000;
BA_ "GenSigTimeoutMsg_Gateway_PQ35_A" SG_ 1348 GE7_res_21 1348;
BA_ "GenSigSendType" SG_ 1348 GE7_res_21 0;
BA_ "GenSigTimeoutTime_Gateway_PQ35_A" SG_ 1348 GE7_res_22 1000;
BA_ "GenSigTimeoutMsg_Gateway_PQ35_A" SG_ 1348 GE7_res_22 1348;
BA_ "GenSigSendType" SG_ 1348 GE7_res_22 0;
BA_ "GenSigTimeoutTime_Gateway_PQ35_A" SG_ 1348 GE7_res_23 1000;
BA_ "GenSigTimeoutMsg_Gateway_PQ35_A" SG_ 1348 GE7_res_23 1348;
BA_ "GenSigSendType" SG_ 1348 GE7_res_23 0;
BA_ "GenSigTimeoutTime_Gateway_PQ35_A" SG_ 1348 GE7_res_25 1000;
BA_ "GenSigTimeoutMsg_Gateway_PQ35_A" SG_ 1348 GE7_res_25 1348;
BA_ "GenSigSendType" SG_ 1348 GE7_res_25 0;
BA_ "GenSigTimeoutTime_Gateway_PQ35_A" SG_ 1348 GE7_res_27 1000;
BA_ "GenSigTimeoutMsg_Gateway_PQ35_A" SG_ 1348 GE7_res_27 1348;
BA_ "GenSigSendType" SG_ 1348 GE7_res_27 0;
BA_ "GenSigTimeoutTime_Gateway_PQ35_A" SG_ 1348 GE7_res_24 1000;
BA_ "GenSigTimeoutMsg_Gateway_PQ35_A" SG_ 1348 GE7_res_24 1348;
BA_ "GenSigSendType" SG_ 1348 GE7_res_24 0;
BA_ "GenSigTimeoutTime_Gateway_PQ35_A" SG_ 1348 GE7_res_26 1000;
BA_ "GenSigTimeoutMsg_Gateway_PQ35_A" SG_ 1348 GE7_res_26 1348;
BA_ "GenSigSendType" SG_ 1348 GE7_res_26 0;
BA_ "GenSigTimeoutTime_Gateway_PQ35_A" SG_ 1348 GE7_res_29 1000;
BA_ "GenSigTimeoutMsg_Gateway_PQ35_A" SG_ 1348 GE7_res_29 1348;
BA_ "GenSigSendType" SG_ 1348 GE7_res_29 0;
BA_ "GenSigTimeoutTime_Gateway_PQ35_A" SG_ 1348 GE7_res_30 1000;
BA_ "GenSigTimeoutMsg_Gateway_PQ35_A" SG_ 1348 GE7_res_30 1348;
BA_ "GenSigSendType" SG_ 1348 GE7_res_30 0;
BA_ "GenSigTimeoutTime_Gateway_PQ35_A" SG_ 1348 GE7_res_28 1000;
BA_ "GenSigTimeoutMsg_Gateway_PQ35_A" SG_ 1348 GE7_res_28 1348;
BA_ "GenSigSendType" SG_ 1348 GE7_res_28 0;
BA_ "GenSigTimeoutTime_Gateway_PQ35_A" SG_ 1348 GE7_res_31 1000;
BA_ "GenSigTimeoutMsg_Gateway_PQ35_A" SG_ 1348 GE7_res_31 1348;
BA_ "GenSigSendType" SG_ 1348 GE7_res_31 0;
BA_ "GenSigTimeoutTime_Gateway_PQ35_A" SG_ 1348 GE7_Text_07 1000;
BA_ "GenSigTimeoutMsg_Gateway_PQ35_A" SG_ 1348 GE7_Text_07 1348;
BA_ "GenSigSendType" SG_ 1348 GE7_Text_07 0;
BA_ "GenSigTimeoutTime_Gateway_PQ35_A" SG_ 1348 GE7_Feh_2Warn 1000;
BA_ "GenSigTimeoutMsg_Gateway_PQ35_A" SG_ 1348 GE7_Feh_2Warn 1348;
BA_ "GenSigSendType" SG_ 1348 GE7_Feh_2Warn 0;
BA_ "GenSigTimeoutTime_Gateway_PQ35_A" SG_ 1348 GE7_Waehlh_ausgef 1000;
BA_ "GenSigTimeoutMsg_Gateway_PQ35_A" SG_ 1348 GE7_Waehlh_ausgef 1348;
BA_ "GenSigSendType" SG_ 1348 GE7_Waehlh_ausgef 0;
BA_ "GenSigTimeoutTime_Gateway_PQ35_A" SG_ 1348 GE7_Feh_1Warn 1000;
BA_ "GenSigTimeoutMsg_Gateway_PQ35_A" SG_ 1348 GE7_Feh_1Warn 1348;
BA_ "GenSigSendType" SG_ 1348 GE7_Feh_1Warn 0;
BA_ "GenSigTimeoutTime_Gateway_PQ35_A" SG_ 1348 GE7_SyncWarn 1000;
BA_ "GenSigTimeoutMsg_Gateway_PQ35_A" SG_ 1348 GE7_SyncWarn 1348;
BA_ "GenSigSendType" SG_ 1348 GE7_SyncWarn 0;
BA_ "GenSigTimeoutTime_Hybrid_MSG" SG_ 1088 GE1_Klimakompr 500;
BA_ "GenSigTimeoutMsg_Hybrid_MSG" SG_ 1088 GE1_Klimakompr 1088;
BA_ "GenSigTimeoutTime_TRW_ESP" SG_ 1088 GE1_Klimakompr 500;
BA_ "GenSigTimeoutMsg_TRW_ESP" SG_ 1088 GE1_Klimakompr 1088;
BA_ "GenSigTimeoutTime_Otto" SG_ 1088 GE1_Klimakompr 500;
BA_ "GenSigTimeoutMsg_Otto" SG_ 1088 GE1_Klimakompr 1088;
BA_ "GenSigTimeoutTime_Diesel" SG_ 1088 GE1_Klimakompr 500;
BA_ "GenSigTimeoutMsg_Diesel" SG_ 1088 GE1_Klimakompr 1088;
BA_ "GenSigSendType" SG_ 1088 GE1_Klimakompr 0;
BA_ "GenSigTimeoutTime_Diesel" SG_ 1088 GE1_Sta_Schutz 500;
BA_ "GenSigTimeoutMsg_Diesel" SG_ 1088 GE1_Sta_Schutz 1088;
BA_ "GenSigTimeoutTime_TRW_ESP" SG_ 1088 GE1_Sta_Schutz 500;
BA_ "GenSigTimeoutMsg_TRW_ESP" SG_ 1088 GE1_Sta_Schutz 1088;
BA_ "GenSigTimeoutTime_Otto" SG_ 1088 GE1_Sta_Schutz 500;
BA_ "GenSigTimeoutMsg_Otto" SG_ 1088 GE1_Sta_Schutz 1088;
BA_ "GenSigSendType" SG_ 1088 GE1_Sta_Schutz 0;
BA_ "GenSigTimeoutTime_Hybrid_MSG" SG_ 1088 GE1_Zielgang 500;
BA_ "GenSigTimeoutMsg_Hybrid_MSG" SG_ 1088 GE1_Zielgang 1088;
BA_ "GenSigTimeoutTime_RKA_Plus" SG_ 1088 GE1_Zielgang 500;
BA_ "GenSigTimeoutMsg_RKA_Plus" SG_ 1088 GE1_Zielgang 1088;
BA_ "GenSigTimeoutTime_TRW_ESP" SG_ 1088 GE1_Zielgang 500;
BA_ "GenSigTimeoutMsg_TRW_ESP" SG_ 1088 GE1_Zielgang 1088;
BA_ "GenSigTimeoutTime_Teves_MK70_MAB" SG_ 1088 GE1_Zielgang 500;
BA_ "GenSigTimeoutMsg_Teves_MK70_MAB" SG_ 1088 GE1_Zielgang 1088;
BA_ "GenSigTimeoutTime_Teves_MK60_ESP" SG_ 1088 GE1_Zielgang 500;
BA_ "GenSigTimeoutMsg_Teves_MK60_ESP" SG_ 1088 GE1_Zielgang 1088;
BA_ "GenSigTimeoutTime_Otto" SG_ 1088 GE1_Zielgang 500;
BA_ "GenSigTimeoutMsg_Otto" SG_ 1088 GE1_Zielgang 1088;
BA_ "GenSigTimeoutTime_Diesel" SG_ 1088 GE1_Zielgang 500;
BA_ "GenSigTimeoutMsg_Diesel" SG_ 1088 GE1_Zielgang 1088;
BA_ "GenSigSendType" SG_ 1088 GE1_Zielgang 0;
BA_ "GenSigTimeoutTime_Hybrid_MSG" SG_ 1088 GE1_EGS_Anf 500;
BA_ "GenSigTimeoutMsg_Hybrid_MSG" SG_ 1088 GE1_EGS_Anf 1088;
BA_ "GenSigTimeoutTime_TRW_ESP" SG_ 1088 GE1_EGS_Anf 500;
BA_ "GenSigTimeoutMsg_TRW_ESP" SG_ 1088 GE1_EGS_Anf 1088;
BA_ "GenSigTimeoutTime_Otto" SG_ 1088 GE1_EGS_Anf 500;
BA_ "GenSigTimeoutMsg_Otto" SG_ 1088 GE1_EGS_Anf 1088;
BA_ "GenSigTimeoutTime_Diesel" SG_ 1088 GE1_EGS_Anf 500;
BA_ "GenSigTimeoutMsg_Diesel" SG_ 1088 GE1_EGS_Anf 1088;
BA_ "GenSigSendType" SG_ 1088 GE1_EGS_Anf 0;
BA_ "GenSigTimeoutTime_TRW_ESP" SG_ 1088 GE1_Soll_Mo 500;
BA_ "GenSigTimeoutMsg_TRW_ESP" SG_ 1088 GE1_Soll_Mo 1088;
BA_ "GenSigTimeoutTime_Otto" SG_ 1088 GE1_Soll_Mo 500;
BA_ "GenSigTimeoutMsg_Otto" SG_ 1088 GE1_Soll_Mo 1088;
BA_ "GenSigTimeoutTime_Diesel" SG_ 1088 GE1_Soll_Mo 500;
BA_ "GenSigTimeoutMsg_Diesel" SG_ 1088 GE1_Soll_Mo 1088;
BA_ "GenSigSendType" SG_ 1088 GE1_Soll_Mo 0;
BA_ "GenSigStartValue" SG_ 1088 GE1_Soll_Mo 254;
BA_ "GenSigTimeoutTime_Allrad" SG_ 1088 GE1_WK 500;
BA_ "GenSigTimeoutMsg_Allrad" SG_ 1088 GE1_WK 1088;
BA_ "GenSigTimeoutTime_Hybrid_MSG" SG_ 1088 GE1_WK 500;
BA_ "GenSigTimeoutMsg_Hybrid_MSG" SG_ 1088 GE1_WK 1088;
BA_ "GenSigTimeoutTime_RKA_Plus" SG_ 1088 GE1_WK 500;
BA_ "GenSigTimeoutMsg_RKA_Plus" SG_ 1088 GE1_WK 1088;
BA_ "GenSigTimeoutTime_TRW_ESP" SG_ 1088 GE1_WK 500;
BA_ "GenSigTimeoutMsg_TRW_ESP" SG_ 1088 GE1_WK 1088;
BA_ "GenSigTimeoutTime_Otto" SG_ 1088 GE1_WK 500;
BA_ "GenSigTimeoutMsg_Otto" SG_ 1088 GE1_WK 1088;
BA_ "GenSigTimeoutTime_Diesel" SG_ 1088 GE1_WK 500;
BA_ "GenSigTimeoutMsg_Diesel" SG_ 1088 GE1_WK 1088;
BA_ "GenSigSendType" SG_ 1088 GE1_WK 0;
BA_ "GenSigTimeoutTime_Hybrid_MSG" SG_ 1088 GE1_Schaltung 500;
BA_ "GenSigTimeoutMsg_Hybrid_MSG" SG_ 1088 GE1_Schaltung 1088;
BA_ "GenSigTimeoutTime_RKA_Plus" SG_ 1088 GE1_Schaltung 500;
BA_ "GenSigTimeoutMsg_RKA_Plus" SG_ 1088 GE1_Schaltung 1088;
BA_ "GenSigTimeoutTime_Gateway_PQ35_A" SG_ 1088 GE1_Schaltung 500;
BA_ "GenSigTimeoutMsg_Gateway_PQ35_A" SG_ 1088 GE1_Schaltung 1088;
BA_ "GenSigTimeoutTime_TRW_ESP" SG_ 1088 GE1_Schaltung 500;
BA_ "GenSigTimeoutMsg_TRW_ESP" SG_ 1088 GE1_Schaltung 1088;
BA_ "GenSigTimeoutTime_Teves_MK70_MAB" SG_ 1088 GE1_Schaltung 500;
BA_ "GenSigTimeoutMsg_Teves_MK70_MAB" SG_ 1088 GE1_Schaltung 1088;
BA_ "GenSigTimeoutTime_Teves_MK60_ESP" SG_ 1088 GE1_Schaltung 500;
BA_ "GenSigTimeoutMsg_Teves_MK60_ESP" SG_ 1088 GE1_Schaltung 1088;
BA_ "GenSigTimeoutTime_Otto" SG_ 1088 GE1_Schaltung 500;
BA_ "GenSigTimeoutMsg_Otto" SG_ 1088 GE1_Schaltung 1088;
BA_ "GenSigTimeoutTime_Diesel" SG_ 1088 GE1_Schaltung 500;
BA_ "GenSigTimeoutMsg_Diesel" SG_ 1088 GE1_Schaltung 1088;
BA_ "GenSigTimeoutTime_Gateway_PQ46_A" SG_ 1088 GE1_Schaltung 500;
BA_ "GenSigTimeoutMsg_Gateway_PQ46_A" SG_ 1088 GE1_Schaltung 1088;
BA_ "GenSigSendType" SG_ 1088 GE1_Schaltung 0;
BA_ "GenSigTimeoutTime_Hybrid_MSG" SG_ 1088 GE1_Mrad_Mkurb 500;
BA_ "GenSigTimeoutMsg_Hybrid_MSG" SG_ 1088 GE1_Mrad_Mkurb 1088;
BA_ "GenSigTimeoutTime_TRW_ESP" SG_ 1088 GE1_Mrad_Mkurb 500;
BA_ "GenSigTimeoutMsg_TRW_ESP" SG_ 1088 GE1_Mrad_Mkurb 1088;
BA_ "GenSigTimeoutTime_Teves_MK70_MAB" SG_ 1088 GE1_Mrad_Mkurb 500;
BA_ "GenSigTimeoutMsg_Teves_MK70_MAB" SG_ 1088 GE1_Mrad_Mkurb 1088;
BA_ "GenSigTimeoutTime_Teves_MK60_ESP" SG_ 1088 GE1_Mrad_Mkurb 500;
BA_ "GenSigTimeoutMsg_Teves_MK60_ESP" SG_ 1088 GE1_Mrad_Mkurb 1088;
BA_ "GenSigTimeoutTime_Otto" SG_ 1088 GE1_Mrad_Mkurb 500;
BA_ "GenSigTimeoutMsg_Otto" SG_ 1088 GE1_Mrad_Mkurb 1088;
BA_ "GenSigTimeoutTime_Diesel" SG_ 1088 GE1_Mrad_Mkurb 500;
BA_ "GenSigTimeoutMsg_Diesel" SG_ 1088 GE1_Mrad_Mkurb 1088;
BA_ "GenSigSendType" SG_ 1088 GE1_Mrad_Mkurb 0;
BA_ "GenSigTimeoutTime_Teves_MK60_ESP" SG_ 1088 GE1_Zaehler 500;
BA_ "GenSigTimeoutMsg_Teves_MK60_ESP" SG_ 1088 GE1_Zaehler 1088;
BA_ "GenSigTimeoutTime_ACC_Lidar" SG_ 1088 GE1_Zaehler 500;
BA_ "GenSigTimeoutMsg_ACC_Lidar" SG_ 1088 GE1_Zaehler 1088;
BA_ "GenSigTimeoutTime_Hybrid_MSG" SG_ 1088 GE1_Zaehler 500;
BA_ "GenSigTimeoutMsg_Hybrid_MSG" SG_ 1088 GE1_Zaehler 1088;
BA_ "GenSigTimeoutTime_ACC_Radar" SG_ 1088 GE1_Zaehler 500;
BA_ "GenSigTimeoutMsg_ACC_Radar" SG_ 1088 GE1_Zaehler 1088;
BA_ "GenSigTimeoutTime_TRW_ESP" SG_ 1088 GE1_Zaehler 500;
BA_ "GenSigTimeoutMsg_TRW_ESP" SG_ 1088 GE1_Zaehler 1088;
BA_ "GenSigTimeoutTime_EPB" SG_ 1088 GE1_Zaehler 500;
BA_ "GenSigTimeoutMsg_EPB" SG_ 1088 GE1_Zaehler 1088;
BA_ "GenSigTimeoutTime_Otto" SG_ 1088 GE1_Zaehler 500;
BA_ "GenSigTimeoutMsg_Otto" SG_ 1088 GE1_Zaehler 1088;
BA_ "GenSigTimeoutTime_Diesel" SG_ 1088 GE1_Zaehler 500;
BA_ "GenSigTimeoutMsg_Diesel" SG_ 1088 GE1_Zaehler 1088;
BA_ "GenSigSendType" SG_ 1088 GE1_Zaehler 0;
BA_ "GenSigTimeoutTime_TRW_ESP" SG_ 1088 GE1_Infobit 500;
BA_ "GenSigTimeoutMsg_TRW_ESP" SG_ 1088 GE1_Infobit 1088;
BA_ "GenSigSendType" SG_ 1088 GE1_Infobit 0;
BA_ "INIT" SG_ 1088 GE1_Infobit "const";
BA_ "GenSigTimeoutTime_Hybrid_MSG" SG_ 1088 GE1_Fahrwistd 500;
BA_ "GenSigTimeoutMsg_Hybrid_MSG" SG_ 1088 GE1_Fahrwistd 1088;
BA_ "GenSigTimeoutTime_TRW_ESP" SG_ 1088 GE1_Fahrwistd 500;
BA_ "GenSigTimeoutMsg_TRW_ESP" SG_ 1088 GE1_Fahrwistd 1088;
BA_ "GenSigTimeoutTime_Otto" SG_ 1088 GE1_Fahrwistd 500;
BA_ "GenSigTimeoutMsg_Otto" SG_ 1088 GE1_Fahrwistd 1088;
BA_ "GenSigTimeoutTime_Diesel" SG_ 1088 GE1_Fahrwistd 500;
BA_ "GenSigTimeoutMsg_Diesel" SG_ 1088 GE1_Fahrwistd 1088;
BA_ "GenSigSendType" SG_ 1088 GE1_Fahrwistd 0;
BA_ "GenSigStartValue" SG_ 1088 GE1_Fahrwistd 127;
BA_ "GenSigTimeoutTime_Teves_MK70_MAB" SG_ 1088 GE1_Wahl_Pos 500;
BA_ "GenSigTimeoutMsg_Teves_MK70_MAB" SG_ 1088 GE1_Wahl_Pos 1088;
BA_ "GenSigTimeoutTime_ACC_Lidar" SG_ 1088 GE1_Wahl_Pos 500;
BA_ "GenSigTimeoutMsg_ACC_Lidar" SG_ 1088 GE1_Wahl_Pos 1088;
BA_ "GenSigTimeoutTime_Hybrid_MSG" SG_ 1088 GE1_Wahl_Pos 500;
BA_ "GenSigTimeoutMsg_Hybrid_MSG" SG_ 1088 GE1_Wahl_Pos 1088;
BA_ "GenSigTimeoutTime_PDC_PLA" SG_ 1088 GE1_Wahl_Pos 500;
BA_ "GenSigTimeoutMsg_PDC_PLA" SG_ 1088 GE1_Wahl_Pos 1088;
BA_ "GenSigTimeoutTime_RKA_Plus" SG_ 1088 GE1_Wahl_Pos 500;
BA_ "GenSigTimeoutMsg_RKA_Plus" SG_ 1088 GE1_Wahl_Pos 1088;
BA_ "GenSigTimeoutTime_Gateway_PQ35_A" SG_ 1088 GE1_Wahl_Pos 500;
BA_ "GenSigTimeoutMsg_Gateway_PQ35_A" SG_ 1088 GE1_Wahl_Pos 1088;
BA_ "GenSigTimeoutTime_ACC_Radar" SG_ 1088 GE1_Wahl_Pos 500;
BA_ "GenSigTimeoutMsg_ACC_Radar" SG_ 1088 GE1_Wahl_Pos 1088;
BA_ "GenSigTimeoutTime_TRW_ESP" SG_ 1088 GE1_Wahl_Pos 500;
BA_ "GenSigTimeoutMsg_TRW_ESP" SG_ 1088 GE1_Wahl_Pos 1088;
BA_ "GenSigTimeoutTime_EPB" SG_ 1088 GE1_Wahl_Pos 500;
BA_ "GenSigTimeoutMsg_EPB" SG_ 1088 GE1_Wahl_Pos 1088;
BA_ "GenSigTimeoutTime_Teves_MK60_ESP" SG_ 1088 GE1_Wahl_Pos 500;
BA_ "GenSigTimeoutMsg_Teves_MK60_ESP" SG_ 1088 GE1_Wahl_Pos 1088;
BA_ "GenSigTimeoutTime_Otto" SG_ 1088 GE1_Wahl_Pos 500;
BA_ "GenSigTimeoutMsg_Otto" SG_ 1088 GE1_Wahl_Pos 1088;
BA_ "GenSigTimeoutTime_Diesel" SG_ 1088 GE1_Wahl_Pos 500;
BA_ "GenSigTimeoutMsg_Diesel" SG_ 1088 GE1_Wahl_Pos 1088;
BA_ "GenSigTimeoutTime_Gateway_PQ46_A" SG_ 1088 GE1_Wahl_Pos 500;
BA_ "GenSigTimeoutMsg_Gateway_PQ46_A" SG_ 1088 GE1_Wahl_Pos 1088;
BA_ "GenSigSendType" SG_ 1088 GE1_Wahl_Pos 0;
BA_ "GenSigTimeoutTime_Diesel" SG_ 1088 GE1_LaunchControl 500;
BA_ "GenSigTimeoutMsg_Diesel" SG_ 1088 GE1_LaunchControl 1088;
BA_ "GenSigTimeoutTime_Hybrid_MSG" SG_ 1088 GE1_LaunchControl 500;
BA_ "GenSigTimeoutMsg_Hybrid_MSG" SG_ 1088 GE1_LaunchControl 1088;
BA_ "GenSigTimeoutTime_TRW_ESP" SG_ 1088 GE1_LaunchControl 500;
BA_ "GenSigTimeoutMsg_TRW_ESP" SG_ 1088 GE1_LaunchControl 1088;
BA_ "GenSigTimeoutTime_Teves_MK70_MAB" SG_ 1088 GE1_LaunchControl 500;
BA_ "GenSigTimeoutMsg_Teves_MK70_MAB" SG_ 1088 GE1_LaunchControl 1088;
BA_ "GenSigTimeoutTime_Teves_MK60_ESP" SG_ 1088 GE1_LaunchControl 500;
BA_ "GenSigTimeoutMsg_Teves_MK60_ESP" SG_ 1088 GE1_LaunchControl 1088;
BA_ "GenSigTimeoutTime_Otto" SG_ 1088 GE1_LaunchControl 500;
BA_ "GenSigTimeoutMsg_Otto" SG_ 1088 GE1_LaunchControl 1088;
BA_ "GenSigSendType" SG_ 1088 GE1_LaunchControl 0;
BA_ "GenSigTimeoutTime_Gateway_PQ35_A" SG_ 1088 GE1_Fehlereintr 500;
BA_ "GenSigTimeoutMsg_Gateway_PQ35_A" SG_ 1088 GE1_Fehlereintr 1088;
BA_ "GenSigTimeoutTime_TRW_ESP" SG_ 1088 GE1_Fehlereintr 500;
BA_ "GenSigTimeoutMsg_TRW_ESP" SG_ 1088 GE1_Fehlereintr 1088;
BA_ "GenSigTimeoutTime_Gateway_PQ46_A" SG_ 1088 GE1_Fehlereintr 500;
BA_ "GenSigTimeoutMsg_Gateway_PQ46_A" SG_ 1088 GE1_Fehlereintr 1088;
BA_ "GenSigSendType" SG_ 1088 GE1_Fehlereintr 0;
BA_ "GenSigTimeoutTime_TRW_ESP" SG_ 1088 GE1_v_Umkehr 500;
BA_ "GenSigTimeoutMsg_TRW_ESP" SG_ 1088 GE1_v_Umkehr 1088;
BA_ "GenSigSendType" SG_ 1088 GE1_v_Umkehr 0;
BA_ "GenSigTimeoutTime_Gateway_PQ35_A" SG_ 1088 GE1_SleepInd 500;
BA_ "GenSigTimeoutMsg_Gateway_PQ35_A" SG_ 1088 GE1_SleepInd 1088;
BA_ "GenSigTimeoutTime_TRW_ESP" SG_ 1088 GE1_SleepInd 500;
BA_ "GenSigTimeoutMsg_TRW_ESP" SG_ 1088 GE1_SleepInd 1088;
BA_ "GenSigTimeoutTime_Gateway_PQ46_A" SG_ 1088 GE1_SleepInd 500;
BA_ "GenSigTimeoutMsg_Gateway_PQ46_A" SG_ 1088 GE1_SleepInd 1088;
BA_ "GenSigSendType" SG_ 1088 GE1_SleepInd 0;
BA_ "GenSigTimeoutTime_Hybrid_MSG" SG_ 1088 GE1_Notlauf 500;
BA_ "GenSigTimeoutMsg_Hybrid_MSG" SG_ 1088 GE1_Notlauf 1088;
BA_ "GenSigTimeoutTime_TRW_ESP" SG_ 1088 GE1_Notlauf 500;
BA_ "GenSigTimeoutMsg_TRW_ESP" SG_ 1088 GE1_Notlauf 1088;
BA_ "GenSigTimeoutTime_EPB" SG_ 1088 GE1_Notlauf 500;
BA_ "GenSigTimeoutMsg_EPB" SG_ 1088 GE1_Notlauf 1088;
BA_ "GenSigTimeoutTime_Otto" SG_ 1088 GE1_Notlauf 500;
BA_ "GenSigTimeoutMsg_Otto" SG_ 1088 GE1_Notlauf 1088;
BA_ "GenSigTimeoutTime_Diesel" SG_ 1088 GE1_Notlauf 500;
BA_ "GenSigTimeoutMsg_Diesel" SG_ 1088 GE1_Notlauf 1088;
BA_ "GenSigSendType" SG_ 1088 GE1_Notlauf 0;
BA_ "GenSigTimeoutTime_Hybrid_MSG" SG_ 1088 GE1_WaVerl_Mo 500;
BA_ "GenSigTimeoutMsg_Hybrid_MSG" SG_ 1088 GE1_WaVerl_Mo 1088;
BA_ "GenSigTimeoutTime_TRW_ESP" SG_ 1088 GE1_WaVerl_Mo 500;
BA_ "GenSigTimeoutMsg_TRW_ESP" SG_ 1088 GE1_WaVerl_Mo 1088;
BA_ "GenSigTimeoutTime_Otto" SG_ 1088 GE1_WaVerl_Mo 500;
BA_ "GenSigTimeoutMsg_Otto" SG_ 1088 GE1_WaVerl_Mo 1088;
BA_ "GenSigTimeoutTime_Diesel" SG_ 1088 GE1_WaVerl_Mo 500;
BA_ "GenSigTimeoutMsg_Diesel" SG_ 1088 GE1_WaVerl_Mo 1088;
BA_ "GenSigSendType" SG_ 1088 GE1_WaVerl_Mo 0;
BA_ "GenSigTimeoutTime_Hybrid_MSG" SG_ 1088 GE1_Kuehlung 500;
BA_ "GenSigTimeoutMsg_Hybrid_MSG" SG_ 1088 GE1_Kuehlung 1088;
BA_ "GenSigTimeoutTime_TRW_ESP" SG_ 1088 GE1_Kuehlung 500;
BA_ "GenSigTimeoutMsg_TRW_ESP" SG_ 1088 GE1_Kuehlung 1088;
BA_ "GenSigTimeoutTime_Otto" SG_ 1088 GE1_Kuehlung 500;
BA_ "GenSigTimeoutMsg_Otto" SG_ 1088 GE1_Kuehlung 1088;
BA_ "GenSigTimeoutTime_Diesel" SG_ 1088 GE1_Kuehlung 500;
BA_ "GenSigTimeoutMsg_Diesel" SG_ 1088 GE1_Kuehlung 1088;
BA_ "GenSigSendType" SG_ 1088 GE1_Kuehlung 0;
BA_ "GenSigTimeoutTime_Hybrid_MSG" SG_ 1088 GE1_Sta_OBD 500;
BA_ "GenSigTimeoutMsg_Hybrid_MSG" SG_ 1088 GE1_Sta_OBD 1088;
BA_ "GenSigTimeoutTime_TRW_ESP" SG_ 1088 GE1_Sta_OBD 500;
BA_ "GenSigTimeoutMsg_TRW_ESP" SG_ 1088 GE1_Sta_OBD 1088;
BA_ "GenSigTimeoutTime_Otto" SG_ 1088 GE1_Sta_OBD 500;
BA_ "GenSigTimeoutMsg_Otto" SG_ 1088 GE1_Sta_OBD 1088;
BA_ "GenSigTimeoutTime_Diesel" SG_ 1088 GE1_Sta_OBD 500;
BA_ "GenSigTimeoutMsg_Diesel" SG_ 1088 GE1_Sta_OBD 1088;
BA_ "GenSigSendType" SG_ 1088 GE1_Sta_OBD 0;
BA_ "GenSigTimeoutTime_Otto" SG_ 1088 GE1_StSt_Info 500;
BA_ "GenSigTimeoutMsg_Otto" SG_ 1088 GE1_StSt_Info 1088;
BA_ "GenSigTimeoutTime_Diesel" SG_ 1088 GE1_StSt_Info 500;
BA_ "GenSigTimeoutMsg_Diesel" SG_ 1088 GE1_StSt_Info 1088;
BA_ "GenSigTimeoutTime_TRW_ESP" SG_ 1088 GE1_StSt_Info 500;
BA_ "GenSigTimeoutMsg_TRW_ESP" SG_ 1088 GE1_StSt_Info 1088;
BA_ "GenSigSendType" SG_ 1088 GE1_StSt_Info 0;
VAL_ 1472 EP1_Spannkraft 31 "Fehler" ;
VAL_ 1472 EP1_Sta_EPB 1 "Bremse_geschlossen" 0 "Bremse_geoeffnet" ;
VAL_ 1472 EP1_Fehler_Sta 3 "beide_Seiten_fehlerhaft" 2 "rechte_Seite_fehlerhaft" 1 "linke_Seite_fehlerhaft" 0 "volle_Funktion" ;
VAL_ 1472 EP1_Schalterinfo 3 "Schalterfehler" 2 "Fahreranforderung_schliessen" 1 "Fahreranforderung_oeffnen" 0 "keine_Fahreranforderung" ;
VAL_ 1472 EP1_Sta_Schalter 1 "Schalter_ausser_Funktion" 0 "volle_Funktion" ;
VAL_ 1472 EP1_Sta_NWS 1 "keine_Funktion" 0 "volle_Funktion" ;
VAL_ 1472 EP1_Fkt_Lampe 1 "Lampe_an" 0 "Lampe_aus" ;
VAL_ 1472 EP1_Fehler_gelb 1 "Lampe_an" 0 "Lampe_aus" ;
VAL_ 1472 EP1_Warnton 1 "Warnton_an" 0 "Warnton_aus" ;
VAL_ 1472 EP1_Fehler_BKL 1 "BKL_an" 0 "BKL_aus" ;
VAL_ 1472 EP1_Fehlereintr 1 "Fehlereintrag" 0 "kein_Fehlereintrag" ;
VAL_ 1472 EP1__Text 8 "Text_8" 7 "reserviert" 6 "reserviert" 5 "Text_5" 4 "Text_4" 3 "Text_3" 2 "Text_2" 1 "Text_1" 0 "kein_Text" ;
VAL_ 1472 EP1_Freigabe_Ver 1 "Verzoegerungsanf_freigegeben" 0 "Verzoegerungsanf_nicht_freigegeb" ;
VAL_ 1472 EP1_Auto_Schl_Oe 1 "erlaubt" 0 "nicht_erlaubt" ;
VAL_ 1472 EP1_SleepInd 1 "Schlafbereit" 0 "Bus_wird_benoetigt" ;
VAL_ 1472 EP1_Bremslicht 1 "ein" 0 "aus" ;
VAL_ 1472 EP1_Status_Kl_15 1 "Kl_15_ein" 0 "Kl_15_aus" ;
VAL_ 1472 EP1_Warnton2 1 "ein" 0 "aus" ;
VAL_ 1472 EP1_Lampe_AutoP 1 "ein" 0 "aus" ;
VAL_ 1472 EP1_QualNeigWi 1 "Ersatz_Init_Fehler" 0 "gueltig" ;
VAL_ 1472 EP1_AnfShLock 1 "ein" 0 "aus" ;
VAL_ 1472 EP1_HydrHalten 1 "Fzg_hydr_geh" 0 "Fzg_nicht_hydr_geh" ;
VAL_ 1472 EP1_Warnton1 1 "ein" 0 "aus" ;
VAL_ 1472 EP1_KuppModBer 3 "Sensor_defekt" 2 "Sensorsignal_ungenau" 1 "Kupplsensor_im_Modbereich" 0 "Kuppsensor_aus_Modbereich" ;
VAL_ 1472 EP1_AutoHold_zul 1 "Pers_zulaessig" 0 "Pers_nicht_zulaessig" ;
VAL_ 1472 EP1_AutoHold_aktiv 1 "ja" 0 "nein" ;
VAL_ 1386 ACA_ID_StaACC 0 "keine_Anzeige" ;
VAL_ 1386 ACA_Fahrerhinw 1 "ein" 0 "aus" ;
VAL_ 1386 ACA_V_Wunsch 255 "kein_Wert_im_Speicher" ;
VAL_ 1386 ACA_PrioDisp 3 "keine_Anzeige_Anf" 2 "niedrige_Prio" 1 "mittlere_Prio" 0 "hohe_Prio" ;
VAL_ 1386 ACA_StaACC 7 "ACC_irrev_aus" 6 "ACC_rev_aus" 5 "frei" 4 "ACC_im_Hintergrund" 3 "ACC_aktiv" 2 "ACC_passiv" 1 "Reserve" 0 "Hauptschalter_aus" ;
VAL_ 1386 ACA_AnzDisplay 1 "Anzeige_erw" 0 "Anzeige_nicht_erw" ;
VAL_ 1386 ACA_Zeitluecke 15 "Zeitluecke15" 14 "Zeitluecke14" 13 "Zeitluecke13" 12 "Zeitluecke12" 11 "Zeitluecke11" 10 "Zeitluecke10" 9 "Zeitluecke9" 8 "Zeitluecke8" 7 "Zeitluecke7" 6 "Zeitluecke6" 5 "Zeitluecke5" 4 "Zeitluecke4" 3 "Zeitluecke3" 2 "Zeitluecke2" 1 "Zeitluecke1" 0 "nicht_definiert" ;
VAL_ 1386 ACA_gemZeitl 15 "Zeitluecke15" 14 "Zeitluecke14" 13 "Zeitluecke13" 12 "Zeitluecke12" 11 "Zeitluecke11" 10 "Zeitluecke10" 9 "Zeitluecke9" 8 "Zeitluecke8" 7 "Zeitluecke7" 6 "Zeitluecke6" 5 "Zeitluecke5" 4 "Zeitluecke4" 3 "Zeitluecke3" 2 "Zeitluecke2" 1 "Zeitluecke1" 0 "Kein_Objekt_erfasst" ;
VAL_ 1386 ACA_kmh_mph 1 "mph" 0 "km_h" ;
VAL_ 1386 ACA_Akustik1 1 "Gong" 0 "kein_Gong" ;
VAL_ 1386 ACA_Akustik2 1 "Summer" 0 "kein_Summer" ;
VAL_ 1386 ACA_Codierung 1 "GRA" 0 "ACC" ;
VAL_ 1386 ACA_Tachokranz 1 "beleuchtet" 0 "nicht_beleuchtet" ;
VAL_ 1386 ACA_ACC_Verz 1 "ACC_verzoegert" 0 "ACC_verzoegert_nicht" ;
VAL_ 1386 ACA_ID_StaGRA 0 "keine_Anzeige" ;
VAL_ 1386 ACA_Aend_Zeitluecke 1 "Anzeige_angef" 0 "keine_Anzeige" ;
VAL_ 1386 ACA_StaGRA 7 "GRA_Fehler" 6 "frei" 5 "frei" 4 "GRA_uebertreten" 3 "GRA_aktiv" 2 "GRA_passiv" 1 "Reserve" 0 "Hauptschalter_aus" ;
VAL_ 872 ACS_Schubabsch 1 "SA_nicht_zulaessig" 0 "SA_zulaessig" ;
VAL_ 872 ACS_ADR_Schub 1 "Verz_begr_auf_Schub" 0 "Verz_nicht_begr_auf_Schub" ;
VAL_ 872 ACS_Sta_ADR 3 "irrev_Fehler" 2 "ADR_passiv" 1 "ADR_aktiv" 0 "ADR_nicht_aktiv" ;
VAL_ 872 ACS_StSt_Info 3 "Systemfehler" 2 "Motoranlauf_notw" 1 "Stoppverbot_Motoranl_nn" 0 "Motorlauf_nn" ;
VAL_ 872 ACS_MomEingriff 1 "MomEingr_verhindern" 0 "keine_Beeinfl_MomEingr_Mot" ;
VAL_ 872 ACS_FreigSollB 1 "Sollbeschl_freigeg" 0 "Sollbeschl_nicht_freigeg" ;
VAL_ 872 ACS_Sollbeschl 2047 "Fehler" 2046 "ADR_nicht_aktiv" ;
VAL_ 872 ACS_Typ_ACC 3 "frei" 2 "frei" 1 "ACC_mit_FollowToStop" 0 "Basis_ACC" ;
VAL_ 872 ACS_Anhaltewunsch 1 "Fzg_haelt_an" 0 "kein_Haltewunsch" ;
VAL_ 872 ACS_zul_Regelabw 255 "Fehler" 254 "ADR_nicht_aktiv" ;
VAL_ 872 ACS_max_AendGrad 255 "Fehler" 254 "Neutralwert" 0 "Neutralwert" ;
VAL_ 872 ACS_Fehler 1 "Fehlerspeichereintrag" 0 "kein_Fehlerspeichereintrag" ;
VAL_ 870 AWV_2_Status 1 "Lampe_ein" 0 "Lampe_aus" ;
VAL_ 870 AWV_2_SU_Warnzeit 3 "adaptiv" 2 "spaet" 1 "normal" 0 "frueh" ;
VAL_ 870 AWV_2_Fehler 1 "Lampe_ein" 0 "Lampe_aus" ;
VAL_ 870 AWV_1_Prefill 1 "Prefill_Anf" 0 "keine_Prefill_Anf" ;
VAL_ 870 AWV_Text 7 "Vorhalt" 6 "FrontScan_Warnung" 5 "FrontScan_Fehler" 4 "FrontScan_Sens_reinig" 3 "FrontScan_nicht_verf" 2 "FrontScan_startet" 1 "FrontScan_aus" 0 "kein_Text" ;
VAL_ 870 AWV_1_Freigabe 1 "freigegeben" 0 "nicht_freigegeben" ;
VAL_ 870 AWV_2_SU_Bremsruck 1 "Bremsruck_aktiviert" 0 "Bremsruck_deaktiviert" ;
VAL_ 870 AWV_1_Parameter 3 "Par_hoechster_Empf" 2 "Par_erh_Empf" 1 "Par_leicht_erh_Empf" 0 "Defaultparametersatz" ;
VAL_ 870 AWV_2_Umfeldwarn 1 "Warnung" 0 "keine_Warnung" ;
VAL_ 870 AWV_2_Freigabe 1 "Ruckfreigabe" 0 "keine_Ruckfreigabe" ;
VAL_ 870 AWV_2_Gurtstraffer 1 "Gurt_straffen" 0 "Gurt_nicht_straffen" ;
VAL_ 870 AWV_2_SU_Gong 1 "Gong_aktiviert" 0 "Gong_deaktiviert" ;
VAL_ 870 AWV_Infoton 1 "ein" 0 "aus" ;
VAL_ 870 AWV_2_Warnsymbol 1 "ein" 0 "aus" ;
VAL_ 870 AWV_2_Warnton 1 "ein" 0 "aus" ;
VAL_ 870 AWV_2_Ruckprofil 0 "kein_Ruck" ;
VAL_ 870 AWV_2_SU_Lampe 1 "Lampe_aktiviert" 0 "Lampe_deaktiviert" ;
VAL_ 1688 AFZ_ParaSW_L 1 "Parametrisierung_erfolgt" 0 "Parametrisierung_nicht_erfolgt" ;
VAL_ 1688 AFZ_ParaSW_R 1 "Parametrisierung_erfolgt" 0 "Parametrisierung_nicht_erfolgt" ;
VAL_ 1688 AFZ_Modus 1 "AFS_ausgeschaltet" 0 "AFS_aktiv" ;
VAL_ 1688 AFZ_Init 1 "Initlauf_erfolgt" 0 "Initlauf_nicht_erfolgt" ;
VAL_ 1688 AFZ_SafePos 1 "Sicherheitsposition_ein" 0 "Sicherheitsposition_aus" ;
VAL_ 1688 AFZ_IstPosMot_L 255 "Fehler" 254 "Wert_ist_unbekannt" ;
VAL_ 1688 AFZ_IstPosMot_R 255 "Fehler" 254 "Wert_ist_unbekannt" ;
VAL_ 1688 AFZ_Soll_EVG 255 "Fehler" 254 "Wert_ist_unbekannt" ;
VAL_ 1688 AFZ_IstDimAbLi 255 "Fehler" 254 "Wert_ist_unbekannt" ;
VAL_ 1688 AFZ_IstDimAbRe 255 "Fehler" 254 "Wert_ist_unbekannt" ;
VAL_ 1688 AFZ_StaLamp_L 1 "Fehler" 0 "kein_Fehler" ;
VAL_ 1688 AFZ_StaLamp_R 1 "Fehler" 0 "kein_Fehler" ;
VAL_ 1428 NI2_Hoehe_HR 255 "Fehler" 254 "nicht_initialisiert" 127 "entsp_NN" ;
VAL_ 1428 NI2_Hoehe_VL 255 "Fehler" 254 "nicht_initialisiert" 127 "entsp_NN" ;
VAL_ 1428 NI2_Hoehe_HL 255 "Fehler" 254 "nicht_initialisiert" 127 "entsp_NN" ;
VAL_ 1428 NI2_Hoehe_VR 255 "Fehler" 254 "nicht_initialisiert" 127 "entsp_NN" ;
VAL_ 1428 NI2_AufbBeschl_VL 255 "Fehler" 254 "notdef" 253 "notdef" ;
VAL_ 1428 NI2_AufbBeschl_VR 255 "Fehler" 254 "notdef" 253 "notdef" ;
VAL_ 1428 NI2_Hoehe_VL_Roh 255 "Fehler" 254 "nicht_initialisiert" 253 "notdef" 252 "notdef" 251 "notdef" ;
VAL_ 1428 NI2_Hoehe_HR_Roh 255 "Fehler" 254 "nicht_initialisiert" 253 "notdef" 252 "notdef" 251 "notdef" ;
VAL_ 1428 NI2_Hoehe_HL_Roh 255 "Fehler" 254 "nicht_initialisiert" 253 "notdef" 252 "notdef" 251 "notdef" ;
VAL_ 1428 NI2_Hoehenflag 1 "Rohwerte" 0 "kalibrierte_Hoehenwerte" ;
VAL_ 1428 NI2_Hoehe_VR_Roh 255 "Fehler" 254 "nicht_initialisiert" 253 "notdef" 252 "notdef" 251 "notdef" ;
VAL_ 1432 DA1_Warnlampe 1 "Lampe_ein" 0 "Lampe_aus" ;
VAL_ 1432 DA1_Systemstatus 1 "funktionsfaehig" 0 "nicht_funktionsfaehig" ;
VAL_ 1432 DA1_Taster 1 "Taste_gedrueckt" 0 "Taste_nicht_gedrueckt" ;
VAL_ 1432 DA1_Textbits 0 "kein_Text" ;
VAL_ 1432 DA1_Daempferreg 7 "Notfahrfunktion" 6 "nicht_definiert" 5 "nicht_aktiv" 4 "sport_2" 3 "sport_1" 2 "normal" 1 "komfortabel" 0 "Init_oder_kein_Wert_verfuegbar" ;
VAL_ 1432 DA1_Fehlereintr 1 "ein_Fehlereintrag" 0 "kein_Fehlereintrag" ;
VAL_ 1432 DA1_ESP_Zwang 1 "ESP_zwangszuschalten" 0 "ESP_nicht_zuschalten" ;
VAL_ 1432 DA1_LampPruef 1 "Lampe_aufpruefen" 0 "Lampe_nucht_aufpr" ;
VAL_ 1432 DA1_Charisma 1 "Charisma_aktiv" 0 "kein_Charisma" ;
VAL_ 1091 RDK_Prio1_Warnung 1 "Prio1_Warnung" 0 "keine_Warnung" ;
VAL_ 1091 RDK_FMVSS_138_Warnung 1 "Lampe_an" 0 "Lampe_aus" ;
VAL_ 1091 RDK_Prio2_Warnung 1 "Prio2_Warnung" 0 "keine_Warnung" ;
VAL_ 1091 RDK_Warnungen 11 "PAX_Stop" 10 "Pax" 9 "Systemfehler" 8 "neue_Druecke_erk" 7 "an_Bel_anpassen" 6 "RD_RR" 5 "RD_hr" 4 "RD_hl" 3 "RD_vr" 2 "RD_vl" 1 "RD_pruefen" 0 "keine_Warnung" ;
VAL_ 1091 RDK_FMVSS_138_MIL 1 "MIL_an" 0 "MIL_aus" ;
VAL_ 1344 GE2_Sta_ZwGas 1 "aktiv" 0 "inaktiv" ;
VAL_ 1344 GE2_Sta_SAS 1 "aktiv" 0 "inaktiv" ;
VAL_ 1344 GE2_LFR_Adap 1 "fuer_Adaption_nicht_geeignet" 0 "fuer_Adaption_geeignet" ;
VAL_ 1344 GE2_Grad_begr 255 "keine_Begrenzung" ;
VAL_ 1344 GE2_LL_Solldz 255 "Fehler" ;
VAL_ 1344 GE2_Sync_Zeit 255 "Fehler" ;
VAL_ 1344 GE2_DZM_Daempf 1 "dynamisch" 0 "normal" ;
VAL_ 1344 GE2_Fehlertext_Freigabe 1 "Textausgabe_erlaubt" 0 "keine_Textausgabe" ;
VAL_ 1344 GE2_Gong 1 "ein" 0 "aus" ;
VAL_ 1344 GE2_Senderkennung 1 "MSG" 0 "GSG" ;
VAL_ 1344 GE2_Shift_Lock 1 "Lampe_ein" 0 "Lampe_aus" ;
VAL_ 1344 GE2_Variante 15 "aktuell_eingelegter_Gang" 13 "_7_Gang_Automat_Tiptronic" 12 "_6_Gang_Automat_Tiptronic" 9 "_5_Gang_Automat_Tiptronic" 8 "_4_Gang_automat_Tiptronic" 6 "Automat_PRNDS" 4 "Selespeed" 3 "ASG_Getriebe" 2 "_4_Gang_Automat" 1 "Automat_PRND" 0 "_5_Gang_automat" ;
VAL_ 1344 GE2_WBA_Blinken 1 "Lampe_ein_Blinken" 0 "Lampe_aus_kein_Blinken" ;
VAL_ 1344 GE2_5Gang 8 "_2" 7 "_3" 6 "_4" 5 "D" 4 "N" 3 "R" 2 "P" 1 "Inversdarstellung" 0 "Normaldarstellung" ;
VAL_ 1344 GE2_PRND 5 "D" 4 "N" 3 "R" 2 "P" 1 "Inversdarstellung" 0 "Normaldarstellung" ;
VAL_ 1344 GE2_4Gang 8 "_1" 7 "_2" 6 "_3" 5 "D" 4 "N" 3 "R" 2 "P" 1 "Inversdarstellung" 0 "Normaldarstellung" ;
VAL_ 1344 GE2_Tip4Gang 5 "_4" 4 "_3" 3 "_2" 2 "_1" 1 "Inversdarstellung" 0 "Normaldarstellung" ;
VAL_ 1344 GE2_akt_Gang 13 "N" 12 "R" 8 "_7" 7 "_6" 6 "_5" 5 "_4" 4 "_3" 3 "_2" 2 "_1" 0 "kein_Gang_eingelegt" ;
VAL_ 1344 GE2_Tip6Gang 7 "_6" 6 "_5" 5 "_4" 4 "_3" 3 "_2" 2 "_1" 1 "Inversdarstellung" 0 "Normaldarstellung" ;
VAL_ 1344 GE2_ASG 12 "E1" 11 "E2" 10 "E3" 9 "E4" 8 "E5" 7 "E6" 6 "E7" 5 "D_E" 4 "N" 3 "R" 2 "S" 1 "Inversdarstellung" 0 "Normaldarstellung" ;
VAL_ 1344 GE2_PRNDS 6 "S" 5 "D" 4 "N" 3 "R" 2 "P" 1 "Inversdarstellung" 0 "Normaldarstellung" ;
VAL_ 1344 GE2_Tip7Gang 8 "_7" 7 "_6" 6 "_5" 5 "_4" 4 "_3" 3 "_2" 2 "_1" 1 "Inversdarstellung" 0 "Normaldarstellung" ;
VAL_ 1344 GE2_Selespeed 10 "Vorhalt_W" 9 "Vorhalt_S" 8 "keine_Anzeige" 7 "A_W" 6 "A_S" 5 "A" 4 "M_W" 3 "M_S" 2 "M" 1 "Inversdarstellung" 0 "Normaldarstellung" ;
VAL_ 1344 GE2_Tip5Gang 6 "_5" 5 "_4" 4 "_3" 3 "_2" 2 "_1" 1 "Inversdarstellung" 0 "Normaldarstellung" ;
VAL_ 1346 GE5_Ausl_Winter 1 "aktiv" 0 "inaktiv" ;
VAL_ 1346 GE5_Test 1 "Test_freigegeben" 0 "kein_Test" ;
VAL_ 1346 GE5_Ausleuchtung 3 "Automatik" 2 "Manuell" 1 "N" 0 "R" ;
VAL_ 1346 GE5_Ausl_Sport 1 "aktiv" 0 "inaktiv" ;
VAL_ 1346 GE5_Abschalten 1 "Aus" 0 "Ein" ;
VAL_ 1346 GE5_Sta_Fahrstufe 1 "Fahrstufe_ungueltig" 0 "Fahrstufe_gueltig" ;
VAL_ 1348 GE7_Text_01 1 "Text_ein" 0 "Text_aus" ;
VAL_ 1348 GE7_Text_04 1 "Text_ein" 0 "Text_aus" ;
VAL_ 1348 GE7_Text_05 1 "Text_ein" 0 "Text_aus" ;
VAL_ 1348 GE7_Text_03 1 "Text_ein" 0 "Text_aus" ;
VAL_ 1348 GE7_Gong 1 "Gong_aktiv" 0 "kein_Gong" ;
VAL_ 1348 GE7_Text_02 1 "Text_ein" 0 "Text_aus" ;
VAL_ 1348 GE7_Text_07 1 "Text_ein" 0 "Text_aus" ;
VAL_ 1348 GE7_Waehlh_ausgef 1 "Waehlhebel_ausgef" 0 "Waehlhebel_OK" ;
VAL_ 1088 GE1_Klimakompr 1 "Kompressor_aus" 0 "keine_Anforderung" ;
VAL_ 1088 GE1_Sta_Schutz 1 "Schutz_angefordert" 0 "kein_Schutz" ;
VAL_ 1088 GE1_Zielgang 15 "Fehler" 14 "Istgang_nicht_definiert" 13 "Frei" 12 "Frei" 11 "Frei" 10 "Frei" 9 "Gang_7" 8 "Gang_6" 7 "Gang_R" 6 "_1m_Gang" 5 "Gang_5" 4 "Gang_4" 3 "Gang_3" 2 "Gang_2" 1 "Gang_1" 0 "Gang_P_N_ausgekuppelt" ;
VAL_ 1088 GE1_EGS_Anf 1 "EGS_Anforderung" 0 "keine_Anforderung" ;
VAL_ 1088 GE1_Soll_Mo 255 "Fehler" ;
VAL_ 1088 GE1_WK 3 "Fehler" 2 "WK_geschlossen" 1 "WK_geregelt" 0 "WK_geoeffnet" ;
VAL_ 1088 GE1_Schaltung 1 "Schaltung_laeuft" 0 "keine_Schaltung" ;
VAL_ 1088 GE1_Mrad_Mkurb 255 "Fehler" ;
VAL_ 1088 GE1_Infobit 1 "CVT" 0 "Stufenautomat" ;
VAL_ 1088 GE1_Fahrwistd 255 "Fehler" ;
VAL_ 1088 GE1_Wahl_Pos 15 "Fehler" 14 "Tipp_Gasse_Manual" 13 "Pos_L" 12 "Pos_S_Automatic_Sport" 11 "Pos_Z2" 10 "Pos_Z1" 9 "Pos_RSP_Manual_Sport" 8 "Pos_P_Key_Lock_Release" 7 "Pos_R" 6 "Pos_N" 5 "Pos_D_Automatic" 4 "Pos_4" 3 "Pos_3" 2 "Pos_2" 1 "Pos_1" 0 "Zwischenstellung" ;
VAL_ 1088 GE1_LaunchControl 1 "aktiv" 0 "nicht_aktiv" ;
VAL_ 1088 GE1_Fehlereintr 1 "Fehlerspeichereintrag" 0 "kein_Fehlerspeichereintrag" ;
VAL_ 1088 GE1_v_Umkehr 1 "Bremsunterstuetzung_notwendig" 0 "keine_Bremsunterstuetzung" ;
VAL_ 1088 GE1_SleepInd 1 "Sleep_bereit" 0 "CAN_wird_benoetigt" ;
VAL_ 1088 GE1_Notlauf 15 "Totalausfall" 7 "kein_Notlauf" 6 "kein_Notlauf" 5 "Kein_Notlauf" 4 "Fahren_ohne_UEK" 3 "Schalten_50_Prozent" 2 "Schalten_nach_n" 1 "kein_Schalten" 0 "kein_Notlauf" ;
VAL_ 1088 GE1_WaVerl_Mo 255 "Fehler" ;
VAL_ 1088 GE1_Kuehlung 3 "Stufe_3" 2 "Stufe_2" 1 "Stufe_1" 0 "OFF" ;
VAL_ 1088 GE1_Sta_OBD 1 "MIL_ein" 0 "MIL_aus" ;
VAL_ 1088 GE1_StSt_Info 3 "Systemfehler" 2 "Motoranlauf_notw" 1 "Stoppverbot_Motoranl_nn" 0 "Motorlauf_nn" ;
